VERSION "dbc-export 1 2026.26.6.5"

NS_ :

BS_:

BU_: ADSP APB APP APS APSB BB BMS CC CMP CMPD CP DAS DI DIF DIR DPB EPAS3P EPAS3S EPASTP EPASTS EPBL EPBR ESP EVSE FC GTW HCML HCMR HVP IBST ICR IDB LS OCS1P ODIN PARK PCS PCS2 PLG PM PMF PMR PNCD PTC RADC RCM RCM2 RCM3 RCU SCCM SCM SCS SDCR TAS TCU TCU2 TPMS TRCM UDS UI UIS UMC USM V2G VC VCBATT VCBATT0 VCBATT1 VCBATT2 VCCC VCFRONT VCFRONT1 VCFRONT2 VCLEFT VCRIGHT VCSEAT2L VCSEAT2R VCSEC VEH

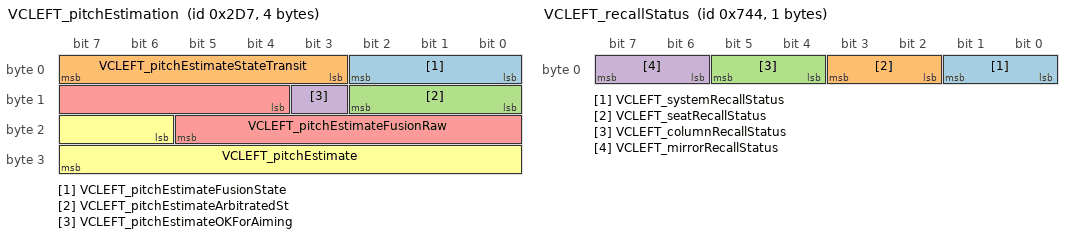
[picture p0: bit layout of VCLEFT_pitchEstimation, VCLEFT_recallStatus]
BO_ 727 VCLEFT_pitchEstimation: 4 VCLEFT
 SG_ VCLEFT_pitchEstimateFusionState : 0|3@1+ (1,0) [0|7] "" Vector__XXX
 SG_ VCLEFT_pitchEstimateStateTransit : 3|5@1+ (1,0) [0|31] "" Vector__XXX
 SG_ VCLEFT_pitchEstimateArbitratedSt : 8|3@1+ (1,0) [0|7] "" Vector__XXX
 SG_ VCLEFT_pitchEstimateOKForAiming : 11|1@1+ (1,0) [0|1] "" Vector__XXX
 SG_ VCLEFT_pitchEstimateFusionRaw : 12|10@1- (0.0002,0) [-0.1024|0.1022] "rad" Vector__XXX
 SG_ VCLEFT_pitchEstimate : 22|10@1- (0.0002,0) [-0.1022|0.1022] "rad" Vector__XXX

BO_ 1860 VCLEFT_recallStatus: 1 VCLEFT
 SG_ VCLEFT_systemRecallStatus : 0|2@1+ (1,0) [1|3] "" Vector__XXX
 SG_ VCLEFT_seatRecallStatus : 2|2@1+ (1,0) [1|3] "" Vector__XXX
 SG_ VCLEFT_columnRecallStatus : 4|2@1+ (1,0) [1|3] "" Vector__XXX
 SG_ VCLEFT_mirrorRecallStatus : 6|2@1+ (1,0) [1|3] "" Vector__XXX

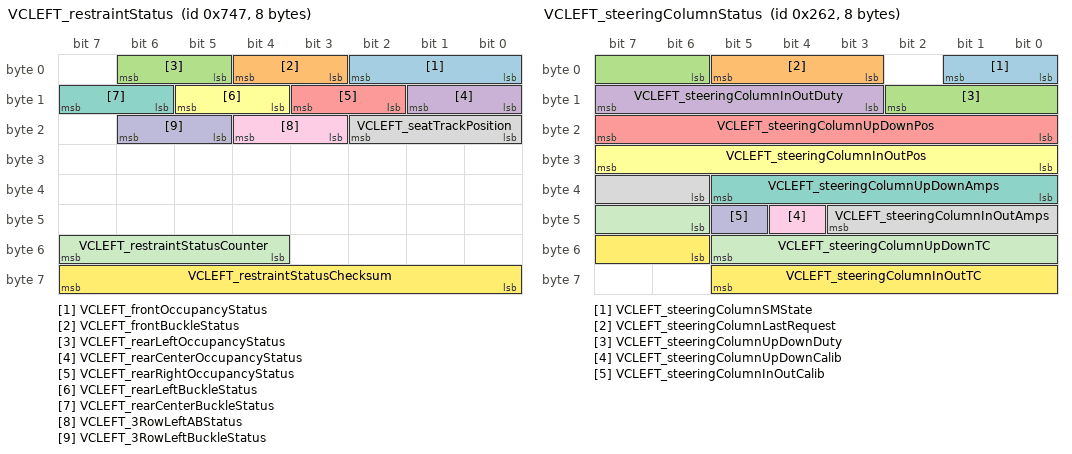
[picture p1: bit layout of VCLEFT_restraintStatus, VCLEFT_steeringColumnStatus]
BO_ 1863 VCLEFT_restraintStatus: 8 VCLEFT
 SG_ VCLEFT_frontOccupancyStatus : 0|3@1+ (1,0) [0|6] "" Vector__XXX
 SG_ VCLEFT_frontBuckleStatus : 3|2@1+ (1,0) [0|3] "" Vector__XXX
 SG_ VCLEFT_rearLeftOccupancyStatus : 5|2@1+ (1,0) [0|3] "" Vector__XXX
 SG_ VCLEFT_rearCenterOccupancyStatus : 8|2@1+ (1,0) [0|3] "" Vector__XXX
 SG_ VCLEFT_rearRightOccupancyStatus : 10|2@1+ (1,0) [0|3] "" Vector__XXX
 SG_ VCLEFT_rearLeftBuckleStatus : 12|2@1+ (1,0) [0|3] "" Vector__XXX
 SG_ VCLEFT_rearCenterBuckleStatus : 14|2@1+ (1,0) [0|3] "" Vector__XXX
 SG_ VCLEFT_seatTrackPosition : 16|3@1+ (1,0) [0|6] "" Vector__XXX
 SG_ VCLEFT_3RowLeftABStatus : 19|2@1+ (1,0) [0|3] "" Vector__XXX
 SG_ VCLEFT_3RowLeftBuckleStatus : 21|2@1+ (1,0) [0|3] "" Vector__XXX
 SG_ VCLEFT_restraintStatusCounter : 52|4@1+ (1,0) [0|15] "" Vector__XXX
 SG_ VCLEFT_restraintStatusChecksum : 56|8@1+ (1,0) [0|255] "" Vector__XXX

BO_ 1250 VCLEFT_seatStatus: 8 VCLEFT
 SG_ VCLEFT_seatStatusIndex M : 0|3@1+ (1,0) [0|7] "" Vector__XXX
 SG_ VC_AH_1RowLeftSeatMovementHealth m0 : 5|3@1+ (1,0) [0|7] "" Vector__XXX
 SG_ VCLEFT_frontSeatTrackPos m0 : 8|16@1- (1,0) [-32768|32767] "" Vector__XXX
 SG_ VCLEFT_frontSeatTrackCurrent m0 : 24|12@1- (0.01,0) [-20.48|20.47] "A" Vector__XXX
 SG_ VCLEFT_frontSeatTrackDuty m0 : 36|12@1- (0.1,0) [-204.8|204.7] "%" Vector__XXX
 SG_ VCLEFT_frontSeatTrackState m0 : 48|3@1+ (1,0) [0|7] "" Vector__XXX
 SG_ VCLEFT_frontSeatTrackCalibrated m0 : 51|1@1+ (1,0) [0|1] "" Vector__XXX
 SG_ VCLEFT_frontSeatTrackLog m0 : 52|1@1+ (1,0) [0|1] "" Vector__XXX
 SG_ VCLEFT_frontSeatTrackBridgeSt m0 : 53|2@1+ (1,0) [0|3] "" Vector__XXX
 SG_ VCLEFT_frontSeatTrackPercentage m0 : 55|7@1+ (1,0) [0|100] "%" Vector__XXX
 SG_ VCLEFT_frontSeatBackPos m1 : 8|16@1- (1,0) [-32768|32767] "" Vector__XXX
 SG_ VCLEFT_frontSeatBackCurrent m1 : 24|12@1- (0.01,0) [-20.48|20.47] "A" Vector__XXX
 SG_ VCLEFT_frontSeatBackDuty m1 : 36|12@1- (0.1,0) [-204.8|204.7] "%" Vector__XXX
 SG_ VCLEFT_frontSeatBackState m1 : 48|3@1+ (1,0) [0|7] "" Vector__XXX
 SG_ VCLEFT_frontSeatBackCalibrated m1 : 51|1@1+ (1,0) [0|1] "" Vector__XXX
 SG_ VCLEFT_frontSeatBackLog m1 : 52|1@1+ (1,0) [0|1] "" Vector__XXX
 SG_ VCLEFT_frontSeatBackBridgeSt m1 : 53|2@1+ (1,0) [0|3] "" Vector__XXX
 SG_ VCLEFT_frontSeatBackPercentage m1 : 55|7@1+ (1,0) [0|100] "%" Vector__XXX
 SG_ VCLEFT_frontSeatLiftPos m2 : 8|16@1- (1,0) [-32768|32767] "" Vector__XXX
 SG_ VCLEFT_frontSeatLiftCurrent m2 : 24|12@1- (0.01,0) [-20.48|20.47] "A" Vector__XXX
 SG_ VCLEFT_frontSeatLiftDuty m2 : 36|12@1- (0.1,0) [-204.8|204.7] "%" Vector__XXX
 SG_ VCLEFT_frontSeatLiftState m2 : 48|3@1+ (1,0) [0|7] "" Vector__XXX
 SG_ VCLEFT_frontSeatLiftCalibrated m2 : 51|1@1+ (1,0) [0|1] "" Vector__XXX
 SG_ VCLEFT_frontSeatLiftLog m2 : 52|1@1+ (1,0) [0|1] "" Vector__XXX
 SG_ VCLEFT_frontSeatLiftBridgeSt m2 : 53|2@1+ (1,0) [0|3] "" Vector__XXX
 SG_ VCLEFT_frontSeatLiftPercentage m2 : 55|7@1+ (1,0) [0|100] "%" Vector__XXX
 SG_ VCLEFT_frontSeatTiltPos m3 : 8|16@1- (1,0) [-32768|32767] "" Vector__XXX
 SG_ VCLEFT_frontSeatTiltCurrent m3 : 24|12@1- (0.01,0) [-20.48|20.47] "A" Vector__XXX
 SG_ VCLEFT_frontSeatTiltDuty m3 : 36|12@1- (0.1,0) [-204.8|204.7] "%" Vector__XXX
 SG_ VCLEFT_frontSeatTiltState m3 : 48|3@1+ (1,0) [0|7] "" Vector__XXX
 SG_ VCLEFT_frontSeatTiltCalibrated m3 : 51|1@1+ (1,0) [0|1] "" Vector__XXX
 SG_ VCLEFT_frontSeatTiltLog m3 : 52|1@1+ (1,0) [0|1] "" Vector__XXX
 SG_ VCLEFT_frontSeatTiltBridgeSt m3 : 53|2@1+ (1,0) [0|3] "" Vector__XXX
 SG_ VCLEFT_frontSeatTiltPercentage m3 : 55|7@1+ (1,0) [0|100] "%" Vector__XXX
 SG_ VCLEFT_lumbarAState m4 : 3|3@1+ (1,0) [0|7] "" Vector__XXX
 SG_ VCLEFT_lumbarBState m4 : 6|3@1+ (1,0) [0|7] "" Vector__XXX
 SG_ VCLEFT_lumbarAPressureHpa m4 : 9|12@1+ (1,0) [0|4095] "" Vector__XXX
 SG_ VCLEFT_lumbarAPressureHpaFilt m4 : 21|10@1+ (1,0) [0|1023] "" Vector__XXX
 SG_ VCLEFT_lumbarBPressureHpa m4 : 31|12@1+ (1,0) [0|4095] "" Vector__XXX
 SG_ VCLEFT_lumbarBPressureHpaFilt m4 : 43|10@1+ (1,0) [0|1023] "" Vector__XXX
 SG_ VCLEFT_lumbarActiveTooLongErr m4 : 53|1@1+ (1,0) [0|1] "" Vector__XXX
 SG_ VCLEFT_lumbarMaxPErr m4 : 54|1@1+ (1,0) [0|1] "" Vector__XXX
 SG_ VCLEFT_lumbarOvercurrentErr m4 : 55|1@1+ (1,0) [0|1] "" Vector__XXX
 SG_ VCLEFT_lumbarMaxOperatingPErr m4 : 56|1@1+ (1,0) [0|1] "" Vector__XXX
 SG_ VCLEFT_lumbarMinPErr m4 : 57|1@1+ (1,0) [0|1] "" Vector__XXX
 SG_ VCLEFT_lumbarGeneralErr m4 : 58|1@1+ (1,0) [0|1] "" Vector__XXX
 SG_ VCLEFT_lumbarDevMaxPumpPressA m4 : 59|1@1+ (1,0) [0|1] "" Vector__XXX
 SG_ VCLEFT_lumbarDevMaxPumpPressB m4 : 60|1@1+ (1,0) [0|1] "" Vector__XXX
 SG_ VCLEFT_frontSeatTrackPosReal m5 : 3|12@1- (1,0) [-2048|2047] "mm" Vector__XXX
 SG_ VCLEFT_frontSeatBackPosReal m5 : 16|12@1- (0.1,0) [-204.8|204.7] "deg" Vector__XXX
 SG_ VCLEFT_frontSeatLiftPosReal m5 : 28|12@1- (1,0) [-2048|2047] "mm" Vector__XXX
 SG_ VCLEFT_frontSeatTiltPosReal m5 : 40|12@1- (0.1,0) [-204.8|204.7] "deg" Vector__XXX
 SG_ VCLEFT_frontSeatThighSupportPosR m5 : 52|12@1- (1,0) [-2048|2047] "mm" Vector__XXX
 SG_ VCLEFT_frontSeatTrackPosOffset m6 : 3|12@1- (1,0) [-2048|2047] "mm" Vector__XXX
 SG_ VCLEFT_frontSeatBackPosOffset m6 : 16|12@1- (0.1,0) [-204.8|204.7] "deg" Vector__XXX
 SG_ VCLEFT_frontSeatLiftPosOffset m6 : 28|12@1- (1,0) [-2048|2047] "mm" Vector__XXX
 SG_ VCLEFT_frontSeatTiltPosOffset m6 : 40|12@1- (0.1,0) [-204.8|204.7] "deg" Vector__XXX
 SG_ VCLEFT_frontSeatThighSupportPosO m6 : 52|12@1- (1,0) [-2048|2047] "mm" Vector__XXX
 SG_ VCLEFT_lumbarAPressurePercentage m7 : 3|7@1+ (1,0) [0|100] "%" Vector__XXX
 SG_ VCLEFT_lumbarBPressurePercentage m7 : 10|7@1+ (1,0) [0|100] "%" Vector__XXX

BO_ 738 VCLEFT_seatStatus2: 8 VCLEFT
 SG_ VCLEFT_seatStatus2Index M : 0|4@1+ (1,0) [0|15] "" Vector__XXX
 SG_ VCLEFT_frontSeatHeatCurrent m0 : 4|12@1+ (0.01,0) [0|40.95] "A" Vector__XXX
 SG_ VCLEFT_frontSeatHeatDuty m0 : 16|8@1+ (1,0) [0|255] "%" Vector__XXX
 SG_ VCLEFT_frontSeatHeatTmp m0 : 24|12@1- (0.05,0) [-40|80] "degC" Vector__XXX
 SG_ VCLEFT_frontSeatHeatTmpTarget m0 : 36|8@1- (0.5,0) [0|60] "degC" Vector__XXX
 SG_ VCLEFT_frontSeatHeatInhibited m0 : 44|1@1+ (1,0) [0|1] "" Vector__XXX
 SG_ VCLEFT_frontSeatHeatPowered m0 : 45|1@1+ (1,0) [0|1] "" Vector__XXX
 SG_ VCLEFT_2RowSeatFoldLeftSwitch m0 : 46|2@1+ (1,0) [1|3] "" Vector__XXX
 SG_ VCLEFT_2RowSeatUnfoldLeftSwitch m0 : 48|2@1+ (1,0) [1|3] "" Vector__XXX
 SG_ VCLEFT_2RowSeatFoldRightSwitch m0 : 50|2@1+ (1,0) [1|3] "" Vector__XXX
 SG_ VCLEFT_2RowSeatUnfoldRightSwitch m0 : 52|2@1+ (1,0) [1|3] "" Vector__XXX
 SG_ VCLEFT_3RowSeatFoldLeftSwitch m0 : 54|2@1+ (1,0) [1|3] "" Vector__XXX
 SG_ VCLEFT_3RowSeatUnfoldLeftSwitch m0 : 56|2@1+ (1,0) [1|3] "" Vector__XXX
 SG_ VCLEFT_3RowSeatFoldRightSwitch m0 : 58|2@1+ (1,0) [1|3] "" Vector__XXX
 SG_ VCLEFT_3RowSeatUnfoldRightSwitch m0 : 60|2@1+ (1,0) [1|3] "" Vector__XXX
 SG_ VC_AH_1RowLeftSeatHeatVentHealth m0 : 62|2@1+ (1,0) [0|3] "" Vector__XXX
 SG_ VCLEFT_2RowSeatReclineState m11 : 4|4@1+ (1,0) [0|14] "" Vector__XXX
 SG_ VCLEFT_2RowSeatReclineDuty m11 : 8|8@1- (1,0) [-100|100] "%" Vector__XXX
 SG_ VCLEFT_2RowSeatReclineCurrent m11 : 16|12@1- (0.05,0) [-100|100] "A" Vector__XXX
 SG_ VCLEFT_2RowSeatReclineCalibrated m11 : 28|1@1+ (1,0) [0|1] "" Vector__XXX
 SG_ VCLEFT_2RowSeatReclinePositionRa m11 : 29|12@1- (1,0) [-2048|2047] "" Vector__XXX
 SG_ VCLEFT_2RowSeatReclineAngle m11 : 41|12@1- (0.1,0) [-204.8|204.7] "deg" Vector__XXX
 SG_ VCLEFT_2RowSeatReclineAbsPosSwit m11 : 53|2@1+ (1,0) [1|3] "" Vector__XXX
 SG_ VCLEFT_2RowSeatReclinePositionSt m12 : 4|3@1+ (1,0) [0|7] "" Vector__XXX
 SG_ VCLEFT_2RowSeatReclineAdjustment m12 : 7|1@1+ (1,0) [0|1] "" Vector__XXX
 SG_ VCLEFT_2RowSeatReclineFoldAllowe m12 : 8|1@1+ (1,0) [0|1] "" Vector__XXX
 SG_ VCLEFT_2RowSeatReclineUnfoldAllo m12 : 9|1@1+ (1,0) [0|1] "" Vector__XXX
 SG_ VCLEFT_2RowSeatReclineNextToggle m12 : 10|2@1+ (1,0) [0|3] "" Vector__XXX
 SG_ VCLEFT_2RowSeatReclineChoreoBloc m12 : 12|1@1+ (1,0) [0|1] "" Vector__XXX
 SG_ VCLEFT_2RowSeat1RClashAvoidanceB m12 : 13|3@1+ (1,0) [0|7] "" Vector__XXX
 SG_ VCLEFT_2RowSeat1RClashAvoidanceS m12 : 16|2@1+ (1,0) [0|3] "" Vector__XXX
 SG_ VCLEFT_2RowSeatReclineAbsPo_0001 m12 : 18|12@1- (0.1,0) [-204.8|204.7] "deg" Vector__XXX
 SG_ VC_AH_2RowLeftSeatMovementHealth m12 : 61|3@1+ (1,0) [0|7] "" Vector__XXX
 SG_ VCLEFT_3RowSeatReclineState m14 : 4|4@1+ (1,0) [0|14] "" Vector__XXX
 SG_ VCLEFT_3RowSeatReclineDuty m14 : 8|8@1- (1,0) [-100|100] "%" Vector__XXX
 SG_ VCLEFT_3RowSeatReclineCurrent m14 : 16|12@1- (0.05,0) [-100|100] "A" Vector__XXX
 SG_ VCLEFT_3RowSeatReclineCalibrated m14 : 28|1@1+ (1,0) [0|1] "" Vector__XXX
 SG_ VCLEFT_3RowSeatReclinePositionRa m14 : 29|12@1- (1,0) [-2048|2047] "" Vector__XXX
 SG_ VCLEFT_3RowSeatReclineAngle m14 : 41|12@1- (0.1,0) [-204.8|204.7] "deg" Vector__XXX
 SG_ VCLEFT_3RowSeatReclineNextToggle m14 : 53|2@1+ (1,0) [0|3] "" Vector__XXX
 SG_ VCLEFT_3RRightCushionHeatCurrent m15 : 4|12@1+ (0.01,0) [0|40.95] "A" Vector__XXX
 SG_ VCLEFT_3RRightCushionHeatDuty m15 : 16|8@1- (1,0) [-100|100] "%" Vector__XXX
 SG_ VCLEFT_3RRightCushionHeatTmp m15 : 24|12@1- (0.05,0) [-40|80] "degC" Vector__XXX
 SG_ VCLEFT_3RRightCushionHeatTmpTarg m15 : 36|8@1- (0.5,0) [0|60] "degC" Vector__XXX
 SG_ VCLEFT_3RRightCushionHeatInhibit m15 : 44|1@1+ (1,0) [0|1] "" Vector__XXX
 SG_ VCLEFT_3RowSeatReclinePositionSt m15 : 46|3@1+ (1,0) [0|7] "" Vector__XXX
 SG_ VCLEFT_3RowSeatReclineAdjustment m15 : 49|1@1+ (1,0) [0|1] "" Vector__XXX
 SG_ VCLEFT_3RowSeatReclineFoldAllowe m15 : 50|1@1+ (1,0) [0|1] "" Vector__XXX
 SG_ VCLEFT_3RowSeatReclineUnfoldAllo m15 : 51|1@1+ (1,0) [0|1] "" Vector__XXX
 SG_ VCLEFT_3RowSeatReclineChoreoBloc m15 : 52|1@1+ (1,0) [0|1] "" Vector__XXX
 SG_ VCLEFT_3RowSeatReclineAbsPosSwit m15 : 53|2@1+ (1,0) [1|3] "" Vector__XXX

BO_ 930 VCLEFT_status: 8 VCLEFT
 SG_ VCLEFT_statusIndex M : 0|2@1+ (1,0) [0|3] "" Vector__XXX
 SG_ VCLEFT_securityControllerEnable m0 : 5|1@1+ (1,0) [0|1] "" Vector__XXX
 SG_ VCLEFT_securityControllerVoltage m0 : 6|5@1+ (0.625,0) [0|19.375] "V" Vector__XXX
 SG_ VCLEFT_consoleDoorAssist m0 : 11|1@1+ (1,0) [0|1] "" Vector__XXX
 SG_ VCLEFT_OTAState m0 : 12|1@1+ (1,0) [0|1] "" Vector__XXX
 SG_ VCLEFT_5AVoltage m0 : 13|10@1+ (0.005443676,0) [0|5.568880548] "V" Vector__XXX
 SG_ VCLEFT_vbatProt m0 : 23|12@1+ (0.005443676,0) [0|22.29185322] "V" Vector__XXX
 SG_ VCLEFT_footwellLightCurrent m0 : 35|12@1- (0.1,0) [-204.8|204.7] "mA" Vector__XXX
 SG_ VCLEFT_swcInputVoltage m0 : 47|8@1+ (0.1,0) [0|25.4] "V" Vector__XXX
 SG_ VCLEFT_swcPCBATemperature m0 : 55|8@1- (1,68) [-59|195] "degC" Vector__XXX
 SG_ VCLEFT_obdEthernetActive m0 : 63|1@1+ (1,0) [0|1] "" Vector__XXX
 SG_ VCLEFT_rationalityAggregateCurre m1 : 12|8@1+ (0.5,0) [0|127.5] "A" Vector__XXX
 SG_ VCLEFT_LVBatteryTypeDBG m1 : 20|3@1+ (1,0) [0|7] "" Vector__XXX
 SG_ VCLEFT_DIeFuseFault m1 : 24|1@1+ (1,0) [0|1] "" Vector__XXX
 SG_ VCLEFT_eFuseMgmtVoltageMonitor m1 : 25|7@1+ (0.125,0) [0|15.875] "V" Vector__XXX
 SG_ VCLEFT_trailerAuxCurrent m1 : 32|12@1+ (0.025,0) [0|102.35] "A" Vector__XXX
 SG_ VCLEFT_swcHeatTmp m1 : 44|10@1+ (0.1,-35) [-35|65] "degC" Vector__XXX
 SG_ VCLEFT_swcHeatStatus m1 : 54|3@1+ (1,0) [1|7] "" Vector__XXX
 SG_ VCLEFT_swcHeatInhibited m1 : 57|1@1+ (1,0) [0|1] "" Vector__XXX
 SG_ VCLEFT_obdDeviceDetected m1 : 58|1@1+ (1,0) [0|1] "" Vector__XXX
 SG_ VCLEFT_pcbaTemperature m2 : 4|11@1+ (0.125,-40) [-40|150] "degC" Vector__XXX
 SG_ VCLEFT_swcHeatPwr m2 : 15|9@1+ (0.5,0) [0|254] "W" Vector__XXX
 SG_ VCLEFT_swcHeatDutyCycle m2 : 24|7@1+ (1,0) [0|100] "%" Vector__XXX
 SG_ VCLEFT_DIeFuseCurrent m2 : 31|6@1+ (0.1,0) [0|6.3] "A" Vector__XXX
 SG_ VCLEFT_SWCpresent m2 : 37|1@1+ (1,0) [0|1] "" Vector__XXX
 SG_ VCLEFT_trailerBrakeControllerCur m2 : 38|8@1+ (0.1,0) [0|25.5] "A" Vector__XXX
 SG_ VCLEFT_autonomyBehaviorStatus m2 : 46|2@1+ (1,0) [0|3] "" Vector__XXX
 SG_ VCLEFT_thirdRowLeftMapLightStatu m2 : 48|2@1+ (1,0) [0|2] "" Vector__XXX
 SG_ VCLEFT_thirdRowRightMapLightStat m2 : 50|2@1+ (1,0) [0|2] "" Vector__XXX

BO_ 610 VCLEFT_steeringColumnStatus: 8 VCLEFT
 SG_ VCLEFT_steeringColumnSMState : 0|2@1+ (1,0) [1|3] "" Vector__XXX
 SG_ VCLEFT_steeringColumnLastRequest : 3|3@1+ (1,0) [1|7] "" Vector__XXX
 SG_ VCLEFT_steeringColumnUpDownDuty : 6|5@1- (7,0) [-100|100] "%" Vector__XXX
 SG_ VCLEFT_steeringColumnInOutDuty : 11|5@1- (7,0) [-100|100] "%" Vector__XXX
 SG_ VCLEFT_steeringColumnUpDownPos : 16|8@1- (1,103) [-25|230] "mm" Vector__XXX
 SG_ VCLEFT_steeringColumnInOutPos : 24|8@1- (1,103) [-25|230] "mm" Vector__XXX
 SG_ VCLEFT_steeringColumnUpDownAmps : 32|6@1- (0.63,0) [-20|19.53] "A" Vector__XXX
 SG_ VCLEFT_steeringColumnInOutAmps : 38|6@1- (0.63,0) [-20|19.53] "A" Vector__XXX
 SG_ VCLEFT_steeringColumnUpDownCalib : 44|1@1+ (1,0) [0|1] "" Vector__XXX
 SG_ VCLEFT_steeringColumnInOutCalib : 45|1@1+ (1,0) [0|1] "" Vector__XXX
 SG_ VCLEFT_steeringColumnUpDownTC : 46|8@1+ (0.5,-10) [-10|117.5] "s" Vector__XXX
 SG_ VCLEFT_steeringColumnInOutTC : 54|8@1+ (0.5,-10) [-10|117.5] "s" Vector__XXX

BO_ 962 VCLEFT_switchStatus: 8 VCLEFT
 SG_ VCLEFT_switchStatusIndex M : 0|1@1+ (1,0) [0|1] "" Vector__XXX
 SG_ VCLEFT_hornSwitchPressed m0 : 2|1@1+ (1,0) [0|1] "" Vector__XXX
 SG_ VCLEFT_hazardButtonPressed m0 : 3|1@1+ (1,0) [0|1] "" Vector__XXX
 SG_ VCLEFT_brakeSwitchPressed m0 : 4|1@1+ (1,0) [0|1] "" Vector__XXX
 SG_ VCLEFT_rightMirrorTilt m0 : 5|3@1+ (1,0) [0|7] "" Vector__XXX
 SG_ VCLEFT_frontSeatTrackBack m0 : 8|2@1+ (1,0) [1|3] "" Vector__XXX
 SG_ VCLEFT_frontSeatTrackForward m0 : 10|2@1+ (1,0) [1|3] "" Vector__XXX
 SG_ VCLEFT_frontSeatTiltDown m0 : 12|2@1+ (1,0) [1|3] "" Vector__XXX
 SG_ VCLEFT_frontSeatTiltUp m0 : 14|2@1+ (1,0) [1|3] "" Vector__XXX
 SG_ VCLEFT_frontSeatLiftDown m0 : 16|2@1+ (1,0) [1|3] "" Vector__XXX
 SG_ VCLEFT_frontSeatLiftUp m0 : 18|2@1+ (1,0) [1|3] "" Vector__XXX
 SG_ VCLEFT_frontSeatBackrestBack m0 : 20|2@1+ (1,0) [1|3] "" Vector__XXX
 SG_ VCLEFT_frontSeatBackrestForward m0 : 22|2@1+ (1,0) [1|3] "" Vector__XXX
 SG_ VCLEFT_frontSeatLumbarDown m0 : 24|2@1+ (1,0) [1|3] "" Vector__XXX
 SG_ VCLEFT_frontSeatLumbarUp m0 : 26|2@1+ (1,0) [1|3] "" Vector__XXX
 SG_ VCLEFT_frontSeatLumbarIn m0 : 28|2@1+ (1,0) [1|3] "" Vector__XXX
 SG_ VCLEFT_frontSeatLumbarOut m0 : 30|2@1+ (1,0) [1|3] "" Vector__XXX
 SG_ VCLEFT_btnWindowSwPackUpLF m0 : 32|1@1+ (1,0) [0|1] "" Vector__XXX
 SG_ VCLEFT_btnWindowSwPackAutoUpLF m0 : 33|1@1+ (1,0) [0|1] "" Vector__XXX
 SG_ VCLEFT_btnWindowSwPackDownLF m0 : 34|1@1+ (1,0) [0|1] "" Vector__XXX
 SG_ VCLEFT_btnWindowSwPackAutoDownLF m0 : 35|1@1+ (1,0) [0|1] "" Vector__XXX
 SG_ VCLEFT_btnWindowSwPackUpLR m0 : 36|1@1+ (1,0) [0|1] "" Vector__XXX
 SG_ VCLEFT_btnWindowSwPackAutoUpLR m0 : 37|1@1+ (1,0) [0|1] "" Vector__XXX
 SG_ VCLEFT_btnWindowSwPackDownLR m0 : 38|1@1+ (1,0) [0|1] "" Vector__XXX
 SG_ VCLEFT_btnWindowSwPackAutoDownLR m0 : 39|1@1+ (1,0) [0|1] "" Vector__XXX
 SG_ VCLEFT_btnWindowSwPackUpRF m0 : 40|1@1+ (1,0) [0|1] "" Vector__XXX
 SG_ VCLEFT_btnWindowSwPackAutoUpRF m0 : 41|1@1+ (1,0) [0|1] "" Vector__XXX
 SG_ VCLEFT_btnWindowSwPackDownRF m0 : 42|1@1+ (1,0) [0|1] "" Vector__XXX
 SG_ VCLEFT_btnWindowSwPackAutoDownRF m0 : 43|1@1+ (1,0) [0|1] "" Vector__XXX
 SG_ VCLEFT_btnWindowSwPackUpRR m0 : 44|1@1+ (1,0) [0|1] "" Vector__XXX
 SG_ VCLEFT_btnWindowSwPackAutoUpRR m0 : 45|1@1+ (1,0) [0|1] "" Vector__XXX
 SG_ VCLEFT_btnWindowSwPackDownRR m0 : 46|1@1+ (1,0) [0|1] "" Vector__XXX
 SG_ VCLEFT_btnWindowSwPackAutoDownRR m0 : 47|1@1+ (1,0) [0|1] "" Vector__XXX
 SG_ VCLEFT_frontBuckleSwitch m0 : 48|2@1+ (1,0) [1|3] "" Vector__XXX
 SG_ VCLEFT_frontOccupancySwitch m0 : 50|2@1+ (1,0) [1|3] "" Vector__XXX
 SG_ VCLEFT_rearLeftBuckleSwitch m0 : 52|2@1+ (1,0) [1|3] "" Vector__XXX
 SG_ VCLEFT_rearCenterOccupancySwitch m0 : 54|2@1+ (1,0) [1|3] "" Vector__XXX
 SG_ VCLEFT_rearLeftOccupancySwitch m0 : 56|2@1+ (1,0) [1|3] "" Vector__XXX
 SG_ VCLEFT_rearRightOccupancySwitch m0 : 58|2@1+ (1,0) [1|3] "" Vector__XXX
 SG_ VCLEFT_brakePressed m0 : 60|1@1+ (1,0) [0|1] "" Vector__XXX
 SG_ VCLEFT_rearHVACButtonPressed m0 : 61|1@1+ (1,0) [0|1] "" Vector__XXX
 SG_ VCLEFT_rearCenterBuckleSwitch m0 : 62|2@1+ (1,0) [1|3] "" Vector__XXX
 SG_ VCLEFT_isAlcoholInterlockSet m1 : 2|1@1+ (1,0) [0|1] "" Vector__XXX
 SG_ VCLEFT_swcLeftTiltRight m1 : 3|2@1+ (1,0) [1|3] "" Vector__XXX
 SG_ VCLEFT_swcLeftPressed m1 : 5|2@1+ (1,0) [1|3] "" Vector__XXX
 SG_ VCLEFT_swcRightTiltLeft m1 : 8|2@1+ (1,0) [1|3] "" Vector__XXX
 SG_ VCLEFT_swcRightTiltRight m1 : 10|2@1+ (1,0) [1|3] "" Vector__XXX
 SG_ VCLEFT_swcRightPressed m1 : 12|2@1+ (1,0) [1|3] "" Vector__XXX
 SG_ VCLEFT_swcLeftTiltLeft m1 : 14|2@1+ (1,0) [1|3] "" Vector__XXX
 SG_ VCLEFT_swcLeftScrollTicks m1 : 16|6@1- (1,0) [-32|31] "" Vector__XXX
 SG_ VCLEFT_swcWiperButtonState m1 : 22|2@1+ (1,0) [0|3] "" Vector__XXX
 SG_ VCLEFT_swcRightScrollTicks m1 : 24|6@1- (1,0) [-32|31] "" Vector__XXX
 SG_ VCLEFT_swcTurnSignalLeftButtonSt m1 : 30|2@1+ (1,0) [0|3] "" Vector__XXX
 SG_ VCLEFT_btnWindowUpLR m1 : 32|1@1+ (1,0) [0|1] "" Vector__XXX
 SG_ VCLEFT_btnWindowAutoUpLR m1 : 33|1@1+ (1,0) [0|1] "" Vector__XXX
 SG_ VCLEFT_btnWindowDownLR m1 : 34|1@1+ (1,0) [0|1] "" Vector__XXX
 SG_ VCLEFT_btnWindowAutoDownLR m1 : 35|1@1+ (1,0) [0|1] "" Vector__XXX
 SG_ VCLEFT_2RowSeatReclineSwitch m1 : 36|1@1+ (1,0) [0|1] "" Vector__XXX
 SG_ VCLEFT_2RowSeatCenterSwitch m1 : 37|1@1+ (1,0) [0|1] "" Vector__XXX
 SG_ VCLEFT_2RowSeatLeftFoldFlatSwitc m1 : 38|1@1+ (1,0) [0|1] "" Vector__XXX
 SG_ VCLEFT_2RowSeatRightFoldFlatSwit m1 : 39|1@1+ (1,0) [0|1] "" Vector__XXX
 SG_ VCLEFT_2RowSeatBothFoldFlatSwitc m1 : 40|1@1+ (1,0) [0|1] "" Vector__XXX
 SG_ VCLEFT_swcLeftDoublePress m1 : 41|1@1+ (1,0) [0|1] "" Vector__XXX
 SG_ VCLEFT_swcRightDoublePress m1 : 42|1@1+ (1,0) [0|1] "" Vector__XXX
 SG_ VCLEFT_2RowSeatBackrestFoldSwitc m1 : 43|1@1+ (1,0) [0|1] "" Vector__XXX
 SG_ VCLEFT_swcTurnSignalRightButtonS m1 : 44|2@1+ (1,0) [0|3] "" Vector__XXX
 SG_ VCLEFT_swcHighBeamButtonState m1 : 46|2@1+ (1,0) [0|3] "" Vector__XXX
 SG_ VCLEFT_swcVoiceControlPress m1 : 48|2@1+ (1,0) [1|3] "" Vector__XXX
 SG_ VCLEFT_swcCameraButtonState m1 : 50|2@1+ (1,0) [0|3] "" Vector__XXX
 SG_ VCLEFT_swcRightPressedQF m1 : 52|1@1+ (1,0) [0|1] "" Vector__XXX
 SG_ VCLEFT_2RowSeatReclineSwitchpack m1 : 53|3@1+ (1,0) [0|7] "" Vector__XXX
 SG_ VCLEFT_3RowLeftBuckleSwitch m1 : 56|2@1+ (1,0) [1|3] "" Vector__XXX
 SG_ VCLEFT_frontSeatThighSupportExte m1 : 58|2@1+ (1,0) [1|3] "" Vector__XXX
 SG_ VCLEFT_frontSeatThighSupportRetr m1 : 60|2@1+ (1,0) [1|3] "" Vector__XXX
 SG_ VCLEFT_frontSeatResistiveOccupan m1 : 62|2@1+ (1,0) [1|3] "" Vector__XXX

BO_ 656 VCLEFT_thermalLogging10Hz: 8 VCLEFT
 SG_ VCLEFT_thermalLogging10HzIndex M : 0|3@1+ (1,0) [0|7] "" Vector__XXX
 SG_ VCLEFT_hvac2RLeftLateralVoltage m2 : 8|8@1+ (0.02,0) [0|5] "V" Vector__XXX
 SG_ VCLEFT_hvac2RLeftVerticalVoltage m2 : 16|8@1+ (0.02,0) [0|5] "V" Vector__XXX
 SG_ VCLEFT_hvac2RRightLateralVoltage m2 : 24|8@1+ (0.02,0) [0|5] "V" Vector__XXX
 SG_ VCLEFT_hvac2RRightVerticalVoltag m2 : 32|8@1+ (0.02,0) [0|5] "V" Vector__XXX
 SG_ VCLEFT_hvac2RLeftLateralCalibrat m2 : 40|1@1+ (1,0) [0|1] "" Vector__XXX
 SG_ VCLEFT_hvac2RLeftVerticalCalibra m2 : 41|1@1+ (1,0) [0|1] "" Vector__XXX
 SG_ VCLEFT_hvac2RRightLateralCalibra m2 : 42|1@1+ (1,0) [0|1] "" Vector__XXX
 SG_ VCLEFT_hvac2RRightVerticalCalibr m2 : 43|1@1+ (1,0) [0|1] "" Vector__XXX
 SG_ VCLEFT_hvac2RLeftLateralState m2 : 44|4@1+ (1,0) [0|15] "" Vector__XXX
 SG_ VCLEFT_hvac2RLeftVerticalState m2 : 48|4@1+ (1,0) [0|15] "" Vector__XXX
 SG_ VCLEFT_hvac2RRightLateralState m2 : 52|4@1+ (1,0) [0|15] "" Vector__XXX
 SG_ VCLEFT_hvac2RRightVerticalState m2 : 56|4@1+ (1,0) [0|15] "" Vector__XXX
 SG_ VCLEFT_hvacBlowerWindmillElecRpm m3 : 3|14@1+ (1,0) [0|16383] "RPM" Vector__XXX
 SG_ VCLEFT_hvac2RRightVerticalVeloci m3 : 17|8@1- (1,0) [-100|100] "deg/s" Vector__XXX
 SG_ VCLEFT_hvacBlowerWindmillBemf m3 : 25|14@1+ (4,0) [0|65532] "mV" Vector__XXX
 SG_ VCLEFT_hvac2RLeftVerticalVelocit m3 : 39|8@1- (1,0) [-100|100] "deg/s" Vector__XXX
 SG_ VCLEFT_hvac2RLeftLateralVelocity m3 : 47|8@1- (1,0) [-100|100] "deg/s" Vector__XXX
 SG_ VCLEFT_vcusbLinSchedule m3 : 55|2@1+ (1,0) [0|3] "" Vector__XXX
 SG_ VCLEFT_hvacBlowerArbState m3 : 57|3@1+ (1,0) [0|7] "" Vector__XXX
 SG_ VCLEFT_hvacBlowerArbResult m3 : 60|2@1+ (1,0) [0|3] "" Vector__XXX
 SG_ VCLEFT_hvac2RLeftLateralDuty m4 : 3|8@1- (1,0) [-100|100] "%" Vector__XXX
 SG_ VCLEFT_hvac2RLeftVerticalDuty m4 : 11|8@1- (1,0) [-100|100] "%" Vector__XXX
 SG_ VCLEFT_hvac2RRightLateralDuty m4 : 19|8@1- (1,0) [-100|100] "%" Vector__XXX
 SG_ VCLEFT_hvac2RRightVerticalDuty m4 : 27|8@1- (1,0) [-100|100] "%" Vector__XXX
 SG_ VCLEFT_hvacBlowerWindmilling m4 : 35|1@1+ (1,0) [0|1] "" Vector__XXX
 SG_ VCLEFT_hvac2RRightLateralVelocit m4 : 36|8@1- (1,0) [-100|100] "deg/s" Vector__XXX
 SG_ VCLEFT_hvacBlower1msOverrunFrequ m4 : 44|10@1+ (1,0) [0|1023] "" Vector__XXX
 SG_ VCLEFT_hvacBlower10msOverrunFreq m4 : 54|7@1+ (1,0) [0|127] "" Vector__XXX

BO_ 657 VCLEFT_thermalLogging1Hz: 7 VCLEFT
 SG_ VCLEFT_thermalLogging1HzIndex M : 0|4@1+ (1,0) [0|15] "" Vector__XXX
 SG_ VCLEFT_hvac2RLeftLateralZeroStop m0 : 8|8@1+ (0.02,0) [0|5] "V" Vector__XXX
 SG_ VCLEFT_hvac2RLeftVerticalZeroSto m0 : 16|8@1+ (0.02,0) [0|5] "V" Vector__XXX
 SG_ VCLEFT_hvac2RRightLateralZeroSto m0 : 24|8@1+ (0.02,0) [0|5] "V" Vector__XXX
 SG_ VCLEFT_hvac2RRightVerticalZeroSt m0 : 32|8@1+ (0.02,0) [0|5] "V" Vector__XXX
 SG_ VCLEFT_hvac2RLeftLateralEndStopV m1 : 8|8@1+ (0.02,0) [0|5] "V" Vector__XXX
 SG_ VCLEFT_hvac2RLeftVerticalEndStop m1 : 16|8@1+ (0.02,0) [0|5] "V" Vector__XXX
 SG_ VCLEFT_hvac2RRightLateralEndStop m1 : 24|8@1+ (0.02,0) [0|5] "V" Vector__XXX
 SG_ VCLEFT_hvac2RRightVerticalEndSto m1 : 32|8@1+ (0.02,0) [0|5] "V" Vector__XXX
 SG_ VCLEFT_hvacBlowerArbCurrent m1 : 40|8@1+ (0.1,0) [0|25.5] "A" Vector__XXX
 SG_ VCLEFT_hvacBlowerTorqueIndexFilt m1 : 48|7@1+ (1,0) [0|127] "%" Vector__XXX

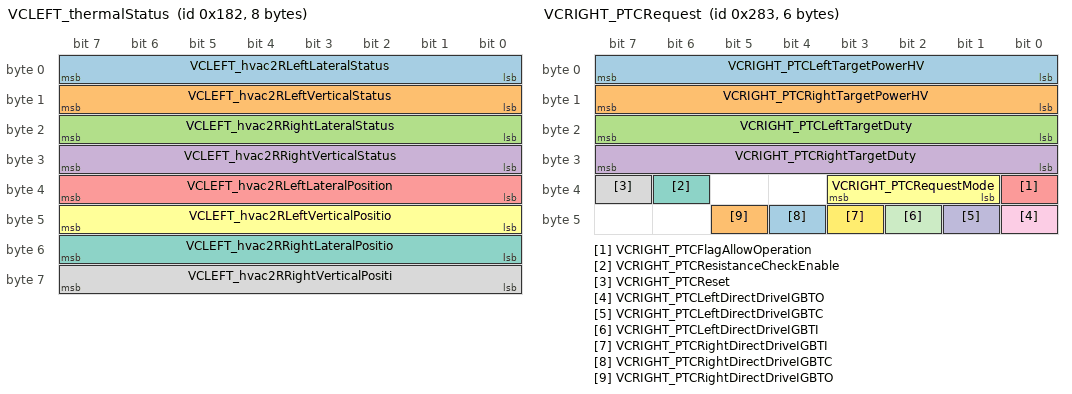
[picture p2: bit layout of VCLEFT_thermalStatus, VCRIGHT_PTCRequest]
BO_ 386 VCLEFT_thermalStatus: 8 VCLEFT
 SG_ VCLEFT_hvac2RLeftLateralStatus : 0|8@1+ (1,0) [0|255] "" Vector__XXX
 SG_ VCLEFT_hvac2RLeftVerticalStatus : 8|8@1+ (1,0) [0|255] "" Vector__XXX
 SG_ VCLEFT_hvac2RRightLateralStatus : 16|8@1+ (1,0) [0|255] "" Vector__XXX
 SG_ VCLEFT_hvac2RRightVerticalStatus : 24|8@1+ (1,0) [0|255] "" Vector__XXX
 SG_ VCLEFT_hvac2RLeftLateralPosition : 32|8@1+ (0.4,0) [0|100] "%" Vector__XXX
 SG_ VCLEFT_hvac2RLeftVerticalPositio : 40|8@1+ (0.4,0) [0|100] "%" Vector__XXX
 SG_ VCLEFT_hvac2RRightLateralPositio : 48|8@1+ (0.4,0) [0|100] "%" Vector__XXX
 SG_ VCLEFT_hvac2RRightVerticalPositi : 56|8@1+ (0.4,0) [0|100] "%" Vector__XXX

BO_ 1571 VCLEFT_udsResponse: 8 VCLEFT
 SG_ VCLEFT_udsResponseData_H : 7|32@0+ (1,0) [0|4294967295] "" Vector__XXX
 SG_ VCLEFT_udsResponseData_L : 39|32@0+ (1,0) [0|4294967295] "" Vector__XXX

BO_ 706 VCLEFT_windowStatus: 8 VCLEFT
 SG_ VCLEFT_windowStatusIndex M : 0|1@1+ (1,0) [0|1] "" Vector__XXX
 SG_ VCLEFT_windowStateLF m0 : 1|4@1+ (1,0) [0|15] "" Vector__XXX
 SG_ VCLEFT_windowTrimClearMoveReques m0 : 5|2@1+ (1,0) [0|3] "" Vector__XXX
 SG_ VCLEFT_windowDutyLF m0 : 8|6@1- (5,0) [-100|100] "%" Vector__XXX
 SG_ VCLEFT_windowTrimClearActiveRequ m0 : 14|2@1+ (1,0) [1|3] "" Vector__XXX
 SG_ VCLEFT_windowCurrentLF m0 : 16|6@1- (0.5,0) [-15|15] "A" Vector__XXX
 SG_ VCLEFT_windowPositionLF m0 : 22|9@1- (1.25,265) [-50|580] "mm" Vector__XXX
 SG_ VCLEFT_windowCalibratedLF m0 : 32|1@1+ (1,0) [0|1] "" Vector__XXX
 SG_ VCLEFT_windowStateLR m0 : 33|4@1+ (1,0) [0|15] "" Vector__XXX
 SG_ VCLEFT_windowDutyLR m0 : 40|6@1- (5,0) [-100|100] "%" Vector__XXX
 SG_ VCLEFT_windowCurrentLR m0 : 48|6@1- (0.5,0) [-15|15] "A" Vector__XXX
 SG_ VCLEFT_windowPositionLR m0 : 54|9@1- (1.25,265) [-50|580] "mm" Vector__XXX
 SG_ VCLEFT_windowCalibratedLR m0 : 63|1@1+ (1,0) [0|1] "" Vector__XXX
 SG_ VCLEFT_windowThermalTCLF m1 : 1|8@1+ (1,0) [0|255] "s" Vector__XXX
 SG_ VCLEFT_windowThermalModeLF m1 : 9|2@1+ (1,0) [1|3] "" Vector__XXX
 SG_ VCLEFT_windowStopReasonLF m1 : 11|3@1+ (1,0) [0|7] "" Vector__XXX
 SG_ VCLEFT_windowStopReqReasonLF m1 : 14|4@1+ (1,0) [0|15] "" Vector__XXX
 SG_ VCLEFT_windowThermalTCLR m1 : 18|8@1+ (1,0) [0|255] "s" Vector__XXX
 SG_ VCLEFT_windowThermalModeLR m1 : 26|2@1+ (1,0) [1|3] "" Vector__XXX
 SG_ VCLEFT_windowStopReasonLR m1 : 28|3@1+ (1,0) [0|7] "" Vector__XXX
 SG_ VCLEFT_windowStopReqReasonLR m1 : 31|4@1+ (1,0) [0|15] "" Vector__XXX
 SG_ VCLEFT_windowControlStateLF m1 : 35|2@1+ (1,0) [0|3] "" Vector__XXX
 SG_ VCLEFT_windowCtrlUnavailableLF m1 : 38|3@1+ (1,0) [0|7] "" Vector__XXX
 SG_ VCLEFT_windowControlStateLR m1 : 42|2@1+ (1,0) [0|3] "" Vector__XXX
 SG_ VCLEFT_windowCtrlUnavailableLR m1 : 45|3@1+ (1,0) [0|7] "" Vector__XXX
 SG_ VCLEFT_windowPositionStateLF m1 : 49|3@1+ (1,0) [0|7] "" Vector__XXX
 SG_ VCLEFT_windowPositionStateLR m1 : 52|3@1+ (1,0) [0|7] "" Vector__XXX
 SG_ VCLEFT_windowVehGearStateLF m1 : 56|2@1+ (1,0) [1|3] "" Vector__XXX
 SG_ VCLEFT_windowVehGearStateLR m1 : 58|2@1+ (1,0) [1|3] "" Vector__XXX
 SG_ VCLEFT_windowSpeedTableStatusLF m1 : 60|2@1+ (1,0) [1|3] "" Vector__XXX
 SG_ VCLEFT_windowSpeedTableStatusLR m1 : 62|2@1+ (1,0) [1|3] "" Vector__XXX

BO_ 1114 VCRIGHT_AP_hvacState10Hz: 8 VCRIGHT
 SG_ VCRIGHT_AP_hvacState10HzIndex M : 0|2@1+ (1,0) [0|3] "" Vector__XXX
 SG_ VCRIGHT_AP_autoDefogAvailable m0 : 2|1@1+ (1,0) [0|1] "" Vector__XXX
 SG_ VCRIGHT_AP_hvacFlashFoggingDetec m0 : 3|1@1+ (1,0) [0|1] "" Vector__XXX
 SG_ VCRIGHT_AP_hvacModelInitStatus m0 : 4|3@1+ (1,0) [0|7] "" Vector__XXX
 SG_ VCRIGHT_AP_cabinTempWindshield m0 : 7|8@1+ (0.5,-40) [-40|80] "degC" Vector__XXX
 SG_ VCRIGHT_AP_cabinTempSideGlassRig m0 : 15|8@1+ (0.5,-40) [-40|80] "degC" Vector__XXX
 SG_ VCRIGHT_AP_cabinTempSideGlassLef m0 : 23|8@1+ (0.5,-40) [-40|80] "degC" Vector__XXX
 SG_ VCRIGHT_AP_hvacRecircDoorPercent m0 : 31|6@1+ (1.6,0) [0|100] "%" Vector__XXX
 SG_ VCRIGHT_AP_hvacAirDistributionMo m0 : 37|3@1+ (1,0) [0|7] "" Vector__XXX
 SG_ VCRIGHT_AP_hvacEstimateWindshiel m0 : 40|8@1+ (1,0) [0|150] "%" Vector__XXX
 SG_ VCRIGHT_AP_hvacMassflowTarget m0 : 48|8@1+ (1,0) [0|200] "g/s" Vector__XXX
 SG_ VCRIGHT_AP_tempDuctDefrost m0 : 56|8@1+ (0.5,-22) [-22|105] "degC" Vector__XXX
 SG_ VCRIGHT_AP_cameraTurnOnTime m1 : 2|9@1+ (5,0) [0|2540] "min" Vector__XXX
 SG_ VCRIGHT_AP_cameraDefogType m1 : 11|3@1+ (1,0) [0|7] "" Vector__XXX
 SG_ VCRIGHT_ah_hvacFaultSurvivabilit m1 : 14|5@1+ (10,0) [0|300] "sec" Vector__XXX
 SG_ VCRIGHT_ah_defoggingTimeNeeded m1 : 19|5@1+ (1,0) [0|30] "min" Vector__XXX
 SG_ VCRIGHT_AP_cameraFanDutyRequest m1 : 24|7@1+ (1,0) [0|100] "%" Vector__XXX
 SG_ VCRIGHT_ah_defogSystemState m1 : 31|3@1+ (1,0) [0|6] "" Vector__XXX
 SG_ VCRIGHT_AP_turnForwardCameraHeat m1 : 34|4@1+ (1,0) [0|15] "" Vector__XXX
 SG_ VCRIGHT_AP_turnCameraFanOffReaso m1 : 38|3@1+ (1,0) [0|7] "" Vector__XXX
 SG_ VCRIGHT_AP_forwardCameraIntegrat m1 : 41|1@1+ (1,0) [0|1] "" Vector__XXX
 SG_ VCRIGHT_AP_solarFluxOnRightWindo m1 : 48|8@1+ (5,0) [0|1150] "W/m2" Vector__XXX
 SG_ VCRIGHT_AP_solarFluxOnLeftWindow m1 : 56|8@1+ (5,0) [0|1150] "W/m2" Vector__XXX

BO_ 1124 VCRIGHT_AP_hvacState1Hz: 8 VCRIGHT
 SG_ VCRIGHT_AP_hvacState1HzIndex M : 0|1@1+ (1,0) [0|1] "" Vector__XXX
 SG_ VCRIGHT_AP_tempCameraModele_0001 m0 : 2|8@1+ (0.5,-40) [-40|85] "degC" Vector__XXX
 SG_ VCRIGHT_AP_tempCameraModeledWind m0 : 10|8@1+ (0.5,-40) [-40|85] "degC" Vector__XXX
 SG_ VCRIGHT_AP_cameraModeledWin_0001 m0 : 18|7@1+ (1,0) [0|100] "%" Vector__XXX
 SG_ VCRIGHT_AP_cameraModeledWindshie m0 : 25|7@1+ (1,0) [0|100] "%" Vector__XXX
 SG_ VCRIGHT_AP_maxAchievableASideTem m0 : 32|7@1+ (1,-20) [-20|70] "degC" Vector__XXX
 SG_ VCRIGHT_AP_cameraModeledPocketWa m0 : 42|10@1+ (0.04,0) [0|40] "g/kg" Vector__XXX
 SG_ VCRIGHT_AP_humidityModelInitStat m0 : 52|5@1+ (1,0) [0|31] "" Vector__XXX
 SG_ VCRIGHT_AP_humidityModelStatus m0 : 57|5@1+ (1,0) [0|31] "" Vector__XXX

BO_ 549 VCRIGHT_LVPowerState: 4 VCRIGHT
 SG_ VCRIGHT_ptcLVState : 0|2@1+ (1,0) [0|3] "" Vector__XXX
 SG_ VCRIGHT_ocsLVState : 2|2@1+ (1,0) [0|3] "" Vector__XXX
 SG_ VCRIGHT_premAudioLVState : 4|2@1+ (1,0) [0|3] "" Vector__XXX
 SG_ VCRIGHT_rearOilPumpLVState : 6|2@1+ (1,0) [0|3] "" Vector__XXX
 SG_ VCRIGHT_tunerLVState : 8|2@1+ (1,0) [0|3] "" Vector__XXX
 SG_ VCRIGHT_hvcLVState : 10|2@1+ (1,0) [0|3] "" Vector__XXX
 SG_ VCRIGHT_rcmLVState : 12|2@1+ (1,0) [0|3] "" Vector__XXX
 SG_ VCRIGHT_lumbarLVState : 14|2@1+ (1,0) [0|3] "" Vector__XXX
 SG_ VCRIGHT_3RUSBPowered : 16|1@1+ (1,0) [0|1] "" Vector__XXX
 SG_ VCRIGHT_cntctrPwrState : 17|1@1+ (1,0) [0|1] "" Vector__XXX
 SG_ VCRIGHT_eFuseLockoutStatus : 18|2@1+ (1,0) [0|3] "" Vector__XXX
 SG_ VCRIGHT_swEnStatus : 20|1@1+ (1,0) [0|1] "" Vector__XXX
 SG_ VCRIGHT_vehiclePowerStateDBG : 21|2@1+ (1,0) [0|3] "" Vector__XXX
 SG_ VCRIGHT_parkLVState : 23|2@1+ (1,0) [0|3] "" Vector__XXX
 SG_ VCRIGHT_icrLVState : 25|2@1+ (1,0) [0|3] "" Vector__XXX
 SG_ VCRIGHT_interiorCameraLedLVState : 27|2@1+ (1,0) [0|3] "" Vector__XXX
 SG_ VCRIGHT_diLVState : 29|2@1+ (1,0) [0|3] "" Vector__XXX
 SG_ VCRIGHT_accDevicesDetected : 31|1@1+ (1,0) [0|1] "" Vector__XXX

BO_ 643 VCRIGHT_PTCRequest: 6 VCRIGHT
 SG_ VCRIGHT_PTCLeftTargetPowerHV : 0|8@1+ (30,0) [0|7650] "W" Vector__XXX
 SG_ VCRIGHT_PTCRightTargetPowerHV : 8|8@1+ (30,0) [0|7650] "W" Vector__XXX
 SG_ VCRIGHT_PTCLeftTargetDuty : 16|8@1+ (0.5,0) [0|100] "%" Vector__XXX
 SG_ VCRIGHT_PTCRightTargetDuty : 24|8@1+ (0.5,0) [0|100] "%" Vector__XXX
 SG_ VCRIGHT_PTCFlagAllowOperation : 32|1@1+ (1,0) [0|1] "" Vector__XXX
 SG_ VCRIGHT_PTCRequestMode : 33|3@1+ (1,0) [0|7] "" Vector__XXX
 SG_ VCRIGHT_PTCResistanceCheckEnable : 38|1@1+ (1,0) [0|1] "" Vector__XXX
 SG_ VCRIGHT_PTCReset : 39|1@1+ (1,0) [0|1] "" Vector__XXX
 SG_ VCRIGHT_PTCLeftDirectDriveIGBTO : 40|1@1+ (1,0) [0|1] "" Vector__XXX
 SG_ VCRIGHT_PTCLeftDirectDriveIGBTC : 41|1@1+ (1,0) [0|1] "" Vector__XXX
 SG_ VCRIGHT_PTCLeftDirectDriveIGBTI : 42|1@1+ (1,0) [0|1] "" Vector__XXX
 SG_ VCRIGHT_PTCRightDirectDriveIGBTI : 43|1@1+ (1,0) [0|1] "" Vector__XXX
 SG_ VCRIGHT_PTCRightDirectDriveIGBTC : 44|1@1+ (1,0) [0|1] "" Vector__XXX
 SG_ VCRIGHT_PTCRightDirectDriveIGBTO : 45|1@1+ (1,0) [0|1] "" Vector__XXX

BO_ 2011 VCRIGHT_alertLog: 8 VCRIGHT
 SG_ VCRIGHT_alertID M : 0|10@1+ (1,0) [0|1023] "" Vector__XXX
 SG_ VCRIGHT_alertState : 15|1@1+ (1,0) [0|1] "" Vector__XXX
 SG_ VCRIGHT_a001_InternalWatchdog m1 : 16|1@1+ (1,0) [0|1] "" Vector__XXX
 SG_ VCRIGHT_a010_UnderVoltageDetecte m10 : 16|1@1+ (1,0) [0|1] "" Vector__XXX
 SG_ VCRIGHT_a010_UnderVoltageTimeout m10 : 17|1@1+ (1,0) [0|1] "" Vector__XXX
 SG_ VCRIGHT_a015_NVMMMemOverflow m15 : 16|1@1+ (1,0) [0|1] "" Vector__XXX
 SG_ VCRIGHT_a015_NVMMFilesystemError m15 : 17|1@1+ (1,0) [0|1] "" Vector__XXX
 SG_ VCRIGHT_a015_NVMMRecordIDError m15 : 18|1@1+ (1,0) [0|1] "" Vector__XXX
 SG_ VCRIGHT_a057_VEH_cpControl m57 : 16|1@1+ (1,0) [0|1] "" Vector__XXX
 SG_ VCRIGHT_a059_voltageDrop m59 : 16|12@1+ (0.005443676,0) [0|22.29185322] "V" Vector__XXX
 SG_ VCRIGHT_a059_resistanceEstimate m59 : 28|12@1+ (0.00244,0) [0|9.9918] "Ohms" Vector__XXX
 SG_ VCRIGHT_a059_current m59 : 40|12@1+ (0.05,0) [0|204.75] "A" Vector__XXX
 SG_ VCRIGHT_a063_switchChannel m63 : 16|8@1+ (1,0) [0|255] "" Vector__XXX
 SG_ VCRIGHT_a063_switchType m63 : 24|8@1+ (1,0) [0|255] "" Vector__XXX
 SG_ VCRIGHT_a063_ADCVoltage m63 : 32|8@1+ (0.025,0) [0|6.375] "V" Vector__XXX
 SG_ VCRIGHT_a063_disconnected m63 : 40|1@1+ (1,0) [0|1] "" Vector__XXX
 SG_ VCRIGHT_a063_indeterminate m63 : 41|1@1+ (1,0) [0|1] "" Vector__XXX
 SG_ VCRIGHT_a063_stuckActive m63 : 42|1@1+ (1,0) [0|1] "" Vector__XXX
 SG_ VCRIGHT_a063_faulted m63 : 43|1@1+ (1,0) [0|1] "" Vector__XXX
 SG_ VCRIGHT_a082_RIPC_epbPrivateStat m82 : 16|1@1+ (1,0) [0|1] "" Vector__XXX
 SG_ VCRIGHT_a082_RIPC_remoteHSD m82 : 17|1@1+ (1,0) [0|1] "" Vector__XXX
 SG_ VCRIGHT_a082_RIPC_railStatus m82 : 18|1@1+ (1,0) [0|1] "" Vector__XXX
 SG_ VCRIGHT_a082_RIPC_remoteMux m82 : 19|1@1+ (1,0) [0|1] "" Vector__XXX
 SG_ VCRIGHT_a083_LIPC_epbPrivateStat m83 : 16|1@1+ (1,0) [0|1] "" Vector__XXX
 SG_ VCRIGHT_a083_LIPC_remoteHSD m83 : 17|1@1+ (1,0) [0|1] "" Vector__XXX
 SG_ VCRIGHT_a083_LIPC_railStatus m83 : 18|1@1+ (1,0) [0|1] "" Vector__XXX
 SG_ VCRIGHT_a083_LIPC_HSDFaults m83 : 19|1@1+ (1,0) [0|1] "" Vector__XXX
 SG_ VCRIGHT_a084_CH_StatusC m84 : 16|1@1+ (1,0) [0|1] "" Vector__XXX
 SG_ VCRIGHT_a085_PARTY_buttonStatus m85 : 16|1@1+ (1,0) [0|1] "" Vector__XXX
 SG_ VCRIGHT_a086_VEH_LVBMS_statusHig m86 : 16|1@1+ (1,0) [0|1] "" Vector__XXX
 SG_ VCRIGHT_a086_VEH_LVBMS_statusLow m86 : 17|1@1+ (1,0) [0|1] "" Vector__XXX
 SG_ VCRIGHT_a086_VEH_status m86 : 18|1@1+ (1,0) [0|1] "" Vector__XXX
 SG_ VCRIGHT_a086_VEH_12VBatteryStatu m86 : 19|1@1+ (1,0) [0|1] "" Vector__XXX
 SG_ VCRIGHT_a086_VEH_LVPowerState m86 : 20|1@1+ (1,0) [0|1] "" Vector__XXX
 SG_ VCRIGHT_a086_VEH_lightStatus m86 : 21|1@1+ (1,0) [0|1] "" Vector__XXX
 SG_ VCRIGHT_a086_VEH_systemStatus m86 : 22|1@1+ (1,0) [0|1] "" Vector__XXX
 SG_ VCRIGHT_a086_VEH_thermalStatus m86 : 23|1@1+ (1,0) [0|1] "" Vector__XXX
 SG_ VCRIGHT_a086_VEH_vehNm m86 : 24|1@1+ (1,0) [0|1] "" Vector__XXX
 SG_ VCRIGHT_a086_BDY_LVSelfTests m86 : 60|1@1+ (1,0) [0|1] "" Vector__XXX
 SG_ VCRIGHT_a086_VEH_LVSelfTests m86 : 61|1@1+ (1,0) [0|1] "" Vector__XXX
 SG_ VCRIGHT_a086_VEH_LVHealth m86 : 62|1@1+ (1,0) [0|1] "" Vector__XXX
 SG_ VCRIGHT_a086_BDY_12VBatteryStatu m86 : 63|1@1+ (1,0) [0|1] "" Vector__XXX
 SG_ VCRIGHT_a087_VEH_temperature m87 : 16|1@1+ (1,0) [0|1] "" Vector__XXX
 SG_ VCRIGHT_a087_VEH_thermalControl m87 : 17|1@1+ (1,0) [0|1] "" Vector__XXX
 SG_ VCRIGHT_a087_VEH_torque m87 : 18|1@1+ (1,0) [0|1] "" Vector__XXX
 SG_ VCRIGHT_a087_VEH_status m87 : 19|1@1+ (1,0) [0|1] "" Vector__XXX
 SG_ VCRIGHT_a087_PARTY_torque m87 : 20|1@1+ (1,0) [0|1] "" Vector__XXX
 SG_ VCRIGHT_a087_PARTY_status m87 : 21|1@1+ (1,0) [0|1] "" Vector__XXX
 SG_ VCRIGHT_a087_PARTY_temperature m87 : 22|1@1+ (1,0) [0|1] "" Vector__XXX
 SG_ VCRIGHT_a087_PARTY_thermalContro m87 : 23|1@1+ (1,0) [0|1] "" Vector__XXX
 SG_ VCRIGHT_a087_VEH_motorStatus m87 : 24|1@1+ (1,0) [0|1] "" Vector__XXX
 SG_ VCRIGHT_a088_VEH_temperature m88 : 16|1@1+ (1,0) [0|1] "" Vector__XXX
 SG_ VCRIGHT_a088_VEH_thermalControl m88 : 17|1@1+ (1,0) [0|1] "" Vector__XXX
 SG_ VCRIGHT_a088_VEH_torque m88 : 18|1@1+ (1,0) [0|1] "" Vector__XXX
 SG_ VCRIGHT_a088_VEH_status m88 : 19|1@1+ (1,0) [0|1] "" Vector__XXX
 SG_ VCRIGHT_a088_PARTY_torque m88 : 20|1@1+ (1,0) [0|1] "" Vector__XXX
 SG_ VCRIGHT_a088_PARTY_status m88 : 21|1@1+ (1,0) [0|1] "" Vector__XXX
 SG_ VCRIGHT_a088_PARTY_temperature m88 : 22|1@1+ (1,0) [0|1] "" Vector__XXX
 SG_ VCRIGHT_a088_PARTY_thermalContro m88 : 23|1@1+ (1,0) [0|1] "" Vector__XXX
 SG_ VCRIGHT_a088_VEH_motorStatus m88 : 24|1@1+ (1,0) [0|1] "" Vector__XXX
 SG_ VCRIGHT_a089_PARTY_party1 m89 : 16|1@1+ (1,0) [0|1] "" Vector__XXX
 SG_ VCRIGHT_a089_PARTY_status m89 : 17|1@1+ (1,0) [0|1] "" Vector__XXX
 SG_ VCRIGHT_a089_VEH_status m89 : 18|1@1+ (1,0) [0|1] "" Vector__XXX
 SG_ VCRIGHT_a089_BDY_party1 m89 : 19|1@1+ (1,0) [0|1] "" Vector__XXX
 SG_ VCRIGHT_a089_BDY_status m89 : 20|1@1+ (1,0) [0|1] "" Vector__XXX
 SG_ VCRIGHT_a089_CH_status m89 : 21|1@1+ (1,0) [0|1] "" Vector__XXX
 SG_ VCRIGHT_a089_CH_party1 m89 : 22|1@1+ (1,0) [0|1] "" Vector__XXX
 SG_ VCRIGHT_a089_CH_party3 m89 : 23|1@1+ (1,0) [0|1] "" Vector__XXX
 SG_ VCRIGHT_a089_VEH_party1 m89 : 24|1@1+ (1,0) [0|1] "" Vector__XXX
 SG_ VCRIGHT_a089_VEH_party3 m89 : 25|1@1+ (1,0) [0|1] "" Vector__XXX
 SG_ VCRIGHT_a091_VEH_faultsAndExtras m91 : 16|1@1+ (1,0) [0|1] "" Vector__XXX
 SG_ VCRIGHT_a091_VEH_info m91 : 17|1@1+ (1,0) [0|1] "" Vector__XXX
 SG_ VCRIGHT_a091_VEH_state m91 : 18|1@1+ (1,0) [0|1] "" Vector__XXX
 SG_ VCRIGHT_a092_VEH_restraintStatus m92 : 16|1@1+ (1,0) [0|1] "" Vector__XXX
 SG_ VCRIGHT_a092_VEH_switchStatus m92 : 17|1@1+ (1,0) [0|1] "" Vector__XXX
 SG_ VCRIGHT_a092_VEH_seatStatus2 m92 : 18|1@1+ (1,0) [0|1] "" Vector__XXX
 SG_ VCRIGHT_a092_VEH_vehNm m92 : 19|1@1+ (1,0) [0|1] "" Vector__XXX
 SG_ VCRIGHT_a093_VEH_restraintStatus m93 : 16|1@1+ (1,0) [0|1] "" Vector__XXX
 SG_ VCRIGHT_a093_VEH_switchStatus m93 : 17|1@1+ (1,0) [0|1] "" Vector__XXX
 SG_ VCRIGHT_a093_VEH_seatStatus2 m93 : 18|1@1+ (1,0) [0|1] "" Vector__XXX
 SG_ VCRIGHT_a093_VEH_vehNm m93 : 19|1@1+ (1,0) [0|1] "" Vector__XXX
 SG_ VCRIGHT_a094_VEH_sysStatus m94 : 16|1@1+ (1,0) [0|1] "" Vector__XXX
 SG_ VCRIGHT_a094_PARTY_sysStatus m94 : 17|1@1+ (1,0) [0|1] "" Vector__XXX
 SG_ VCRIGHT_a094_CH_sysStatus m94 : 18|1@1+ (1,0) [0|1] "" Vector__XXX
 SG_ VCRIGHT_a095_PT_ptNm m95 : 16|1@1+ (1,0) [0|1] "" Vector__XXX
 SG_ VCRIGHT_a095_PT_status m95 : 17|1@1+ (1,0) [0|1] "" Vector__XXX
 SG_ VCRIGHT_a096_VEH_status m96 : 16|1@1+ (1,0) [0|1] "" Vector__XXX
 SG_ VCRIGHT_a096_CH_status m96 : 17|1@1+ (1,0) [0|1] "" Vector__XXX
 SG_ VCRIGHT_a097_VEH_HVStatus m97 : 16|1@1+ (1,0) [0|1] "" Vector__XXX
 SG_ VCRIGHT_a097_VEH_state m97 : 17|1@1+ (1,0) [0|1] "" Vector__XXX
 SG_ VCRIGHT_a098_CH_torque m98 : 16|1@1+ (1,0) [0|1] "" Vector__XXX
 SG_ VCRIGHT_a098_VEH_hvStatus m98 : 17|1@1+ (1,0) [0|1] "" Vector__XXX
 SG_ VCRIGHT_a098_VEH_status m98 : 18|1@1+ (1,0) [0|1] "" Vector__XXX
 SG_ VCRIGHT_a098_VEH_thermalControl m98 : 19|1@1+ (1,0) [0|1] "" Vector__XXX
 SG_ VCRIGHT_a098_VEH_temperature m98 : 20|1@1+ (1,0) [0|1] "" Vector__XXX
 SG_ VCRIGHT_a098_VEH_torque m98 : 21|1@1+ (1,0) [0|1] "" Vector__XXX
 SG_ VCRIGHT_a098_PARTY_status m98 : 22|1@1+ (1,0) [0|1] "" Vector__XXX
 SG_ VCRIGHT_a098_PARTY_temperature m98 : 23|1@1+ (1,0) [0|1] "" Vector__XXX
 SG_ VCRIGHT_a098_PARTY_thermalContro m98 : 24|1@1+ (1,0) [0|1] "" Vector__XXX
 SG_ VCRIGHT_a098_PARTY_torque m98 : 25|1@1+ (1,0) [0|1] "" Vector__XXX
 SG_ VCRIGHT_a098_PT_thermalControl m98 : 26|1@1+ (1,0) [0|1] "" Vector__XXX
 SG_ VCRIGHT_a098_PT_temperature m98 : 27|1@1+ (1,0) [0|1] "" Vector__XXX
 SG_ VCRIGHT_a098_PARTY_motorStatus m98 : 28|1@1+ (1,0) [0|1] "" Vector__XXX
 SG_ VCRIGHT_a098_VEH_motorStatus m98 : 29|1@1+ (1,0) [0|1] "" Vector__XXX
 SG_ VCRIGHT_a099_VEH_oocStatus m99 : 16|1@1+ (1,0) [0|1] "" Vector__XXX
 SG_ VCRIGHT_a100_VEH m100 : 16|1@1+ (1,0) [0|1] "" Vector__XXX
 SG_ VCRIGHT_a100_PARTY m100 : 17|1@1+ (1,0) [0|1] "" Vector__XXX
 SG_ VCRIGHT_a100_PT m100 : 18|1@1+ (1,0) [0|1] "" Vector__XXX
 SG_ VCRIGHT_a100_CH m100 : 19|1@1+ (1,0) [0|1] "" Vector__XXX
 SG_ VCRIGHT_a100_OBD m100 : 20|1@1+ (1,0) [0|1] "" Vector__XXX
 SG_ VCRIGHT_a101_VEH_state m101 : 16|1@1+ (1,0) [0|1] "" Vector__XXX
 SG_ VCRIGHT_a101_PARTY_locState m101 : 17|1@1+ (1,0) [0|1] "" Vector__XXX
 SG_ VCRIGHT_a101_LIPC_externalWatchd m101 : 18|1@1+ (1,0) [0|1] "" Vector__XXX
 SG_ VCRIGHT_a101_VEH_locState m101 : 19|1@1+ (1,0) [0|1] "" Vector__XXX
 SG_ VCRIGHT_a101_BDY_locState m101 : 20|1@1+ (1,0) [0|1] "" Vector__XXX
 SG_ VCRIGHT_a102_VEH_faultsAndExtras m102 : 16|1@1+ (1,0) [0|1] "" Vector__XXX
 SG_ VCRIGHT_a102_VEH_feedbackStatus m102 : 17|1@1+ (1,0) [0|1] "" Vector__XXX
 SG_ VCRIGHT_a102_VEH_sensorStatus m102 : 18|1@1+ (1,0) [0|1] "" Vector__XXX
 SG_ VCRIGHT_a102_VEH_rods m102 : 19|1@1+ (1,0) [0|1] "" Vector__XXX
 SG_ VCRIGHT_a103_VEH_hvsNm m103 : 16|1@1+ (1,0) [0|1] "" Vector__XXX
 SG_ VCRIGHT_a103_VEH_vehNm m103 : 17|1@1+ (1,0) [0|1] "" Vector__XXX
 SG_ VCRIGHT_a103_VEH_status m103 : 18|1@1+ (1,0) [0|1] "" Vector__XXX
 SG_ VCRIGHT_a103_PT_ptNm m103 : 19|1@1+ (1,0) [0|1] "" Vector__XXX
 SG_ VCRIGHT_a103_PT_status m103 : 20|1@1+ (1,0) [0|1] "" Vector__XXX
 SG_ VCRIGHT_a103_VEH_evseStatus m103 : 21|1@1+ (1,0) [0|1] "" Vector__XXX
 SG_ VCRIGHT_a105_VEH_states m105 : 16|1@1+ (1,0) [0|1] "" Vector__XXX
 SG_ VCRIGHT_a105_VEH_chNm m105 : 17|1@1+ (1,0) [0|1] "" Vector__XXX
 SG_ VCRIGHT_a105_VEH_dampingStates m105 : 18|1@1+ (1,0) [0|1] "" Vector__XXX
 SG_ VCRIGHT_a106_VEH_dcdcStatus m106 : 16|1@1+ (1,0) [0|1] "" Vector__XXX
 SG_ VCRIGHT_a106_VEH_thermalControl m106 : 17|1@1+ (1,0) [0|1] "" Vector__XXX
 SG_ VCRIGHT_a106_VEH_dcdcRailStatus m106 : 18|1@1+ (1,0) [0|1] "" Vector__XXX
 SG_ VCRIGHT_a106_CH_dcdcRailStatus m106 : 19|1@1+ (1,0) [0|1] "" Vector__XXX
 SG_ VCRIGHT_a106_CH_alertMatrix m106 : 20|1@1+ (1,0) [0|1] "" Vector__XXX
 SG_ VCRIGHT_a107_VEH_hvsNm m107 : 16|1@1+ (1,0) [0|1] "" Vector__XXX
 SG_ VCRIGHT_a107_VEH_vehNm m107 : 17|1@1+ (1,0) [0|1] "" Vector__XXX
 SG_ VCRIGHT_a107_VEH_status m107 : 18|1@1+ (1,0) [0|1] "" Vector__XXX
 SG_ VCRIGHT_a107_VEH_thermalStatus m107 : 19|1@1+ (1,0) [0|1] "" Vector__XXX
 SG_ VCRIGHT_a107_VEH_bmbMinMax m107 : 20|1@1+ (1,0) [0|1] "" Vector__XXX
 SG_ VCRIGHT_a107_VEH_powerAvailable m107 : 21|1@1+ (1,0) [0|1] "" Vector__XXX
 SG_ VCRIGHT_a107_PT_ptNm m107 : 22|1@1+ (1,0) [0|1] "" Vector__XXX
 SG_ VCRIGHT_a107_PT_status m107 : 23|1@1+ (1,0) [0|1] "" Vector__XXX
 SG_ VCRIGHT_a107_PT_thermalStatus m107 : 24|1@1+ (1,0) [0|1] "" Vector__XXX
 SG_ VCRIGHT_a107_PT_socStatus m107 : 25|1@1+ (1,0) [0|1] "" Vector__XXX
 SG_ VCRIGHT_a107_VEH_socStatus m107 : 26|1@1+ (1,0) [0|1] "" Vector__XXX
 SG_ VCRIGHT_a107_VEH_packConfig m107 : 27|1@1+ (1,0) [0|1] "" Vector__XXX
 SG_ VCRIGHT_a107_VEH_energyStatus m107 : 28|1@1+ (1,0) [0|1] "" Vector__XXX
 SG_ VCRIGHT_a107_VEH_chargeInfo m107 : 29|1@1+ (1,0) [0|1] "" Vector__XXX
 SG_ VCRIGHT_a108_VEH_hvStatus m108 : 16|1@1+ (1,0) [0|1] "" Vector__XXX
 SG_ VCRIGHT_a108_VEH_temperature m108 : 17|1@1+ (1,0) [0|1] "" Vector__XXX
 SG_ VCRIGHT_a108_VEH_thermalControl m108 : 18|1@1+ (1,0) [0|1] "" Vector__XXX
 SG_ VCRIGHT_a108_VEH_torque m108 : 19|1@1+ (1,0) [0|1] "" Vector__XXX
 SG_ VCRIGHT_a108_VEH_status m108 : 20|1@1+ (1,0) [0|1] "" Vector__XXX
 SG_ VCRIGHT_a108_PARTY_torque m108 : 21|1@1+ (1,0) [0|1] "" Vector__XXX
 SG_ VCRIGHT_a108_PARTY_status m108 : 22|1@1+ (1,0) [0|1] "" Vector__XXX
 SG_ VCRIGHT_a108_PARTY_temperature m108 : 23|1@1+ (1,0) [0|1] "" Vector__XXX
 SG_ VCRIGHT_a108_PARTY_thermalContro m108 : 24|1@1+ (1,0) [0|1] "" Vector__XXX
 SG_ VCRIGHT_a108_PT_temperature m108 : 25|1@1+ (1,0) [0|1] "" Vector__XXX
 SG_ VCRIGHT_a108_PT_thermalControl m108 : 26|1@1+ (1,0) [0|1] "" Vector__XXX
 SG_ VCRIGHT_a108_PARTY_motorStatus m108 : 27|1@1+ (1,0) [0|1] "" Vector__XXX
 SG_ VCRIGHT_a108_VEH_motorStatus m108 : 28|1@1+ (1,0) [0|1] "" Vector__XXX
 SG_ VCRIGHT_a108_CH_torque m108 : 29|1@1+ (1,0) [0|1] "" Vector__XXX
 SG_ VCRIGHT_a110_VEH_carState m110 : 16|1@1+ (1,0) [0|1] "" Vector__XXX
 SG_ VCRIGHT_a110_VEH_carConfig m110 : 17|1@1+ (1,0) [0|1] "" Vector__XXX
 SG_ VCRIGHT_a110_VEH_time m110 : 18|1@1+ (1,0) [0|1] "" Vector__XXX
 SG_ VCRIGHT_a110_VEH_updateStatus m110 : 19|1@1+ (1,0) [0|1] "" Vector__XXX
 SG_ VCRIGHT_a110_VEH_vehNm m110 : 20|1@1+ (1,0) [0|1] "" Vector__XXX
 SG_ VCRIGHT_a110_VEH_mismatchFault m110 : 21|1@1+ (1,0) [0|1] "" Vector__XXX
 SG_ VCRIGHT_a110_VEH_vin m110 : 22|1@1+ (1,0) [0|1] "" Vector__XXX
 SG_ VCRIGHT_a110_VEH_bmpDebug m110 : 23|1@1+ (1,0) [0|1] "" Vector__XXX
 SG_ VCRIGHT_a110_VEH_gearControl m110 : 24|1@1+ (1,0) [0|1] "" Vector__XXX
 SG_ VCRIGHT_a110_VEH_canLogAvailabil m110 : 25|1@1+ (1,0) [0|1] "" Vector__XXX
 SG_ VCRIGHT_a110_CH_airbagCutoffStat m110 : 26|1@1+ (1,0) [0|1] "" Vector__XXX
 SG_ VCRIGHT_a110_CH_carConfig m110 : 27|1@1+ (1,0) [0|1] "" Vector__XXX
 SG_ VCRIGHT_a110_CH_carState m110 : 28|1@1+ (1,0) [0|1] "" Vector__XXX
 SG_ VCRIGHT_a110_CH_vin m110 : 29|1@1+ (1,0) [0|1] "" Vector__XXX
 SG_ VCRIGHT_a110_CH_chNm m110 : 30|1@1+ (1,0) [0|1] "" Vector__XXX
 SG_ VCRIGHT_a110_CH_epochTimeGtw m110 : 31|1@1+ (1,0) [0|1] "" Vector__XXX
 SG_ VCRIGHT_a110_PARTY_carConfig m110 : 32|1@1+ (1,0) [0|1] "" Vector__XXX
 SG_ VCRIGHT_a111_VEH_internalStatus m111 : 16|1@1+ (1,0) [0|1] "" Vector__XXX
 SG_ VCRIGHT_a111_VEH_status m111 : 17|1@1+ (1,0) [0|1] "" Vector__XXX
 SG_ VCRIGHT_a111_VEH_vehNm m111 : 18|1@1+ (1,0) [0|1] "" Vector__XXX
 SG_ VCRIGHT_a111_RIPC_LVPowerState m111 : 19|1@1+ (1,0) [0|1] "" Vector__XXX
 SG_ VCRIGHT_a111_RIPC_epbPrivateStat m111 : 20|1@1+ (1,0) [0|1] "" Vector__XXX
 SG_ VCRIGHT_a111_RIPC_railStatus m111 : 21|1@1+ (1,0) [0|1] "" Vector__XXX
 SG_ VCRIGHT_a111_RIPC_remoteADC m111 : 22|1@1+ (1,0) [0|1] "" Vector__XXX
 SG_ VCRIGHT_a111_RIPC_switchStatus m111 : 23|1@1+ (1,0) [0|1] "" Vector__XXX
 SG_ VCRIGHT_a111_VEH_LVPowerState m111 : 24|1@1+ (1,0) [0|1] "" Vector__XXX
 SG_ VCRIGHT_a111_VEH_seatStatus m111 : 25|1@1+ (1,0) [0|1] "" Vector__XXX
 SG_ VCRIGHT_a111_PARTY_status m111 : 26|1@1+ (1,0) [0|1] "" Vector__XXX
 SG_ VCRIGHT_a111_CH_status m111 : 27|1@1+ (1,0) [0|1] "" Vector__XXX
 SG_ VCRIGHT_a112_VEH_internalStatus m112 : 16|1@1+ (1,0) [0|1] "" Vector__XXX
 SG_ VCRIGHT_a112_VEH_status m112 : 17|1@1+ (1,0) [0|1] "" Vector__XXX
 SG_ VCRIGHT_a112_VEH_vehNm m112 : 18|1@1+ (1,0) [0|1] "" Vector__XXX
 SG_ VCRIGHT_a112_LIPC_LVPowerState m112 : 19|1@1+ (1,0) [0|1] "" Vector__XXX
 SG_ VCRIGHT_a112_LIPC_epbPrivateStat m112 : 20|1@1+ (1,0) [0|1] "" Vector__XXX
 SG_ VCRIGHT_a112_LIPC_railStatus m112 : 21|1@1+ (1,0) [0|1] "" Vector__XXX
 SG_ VCRIGHT_a112_LIPC_remoteADC m112 : 22|1@1+ (1,0) [0|1] "" Vector__XXX
 SG_ VCRIGHT_a112_LIPC_switchStatus m112 : 23|1@1+ (1,0) [0|1] "" Vector__XXX
 SG_ VCRIGHT_a112_VEH_LVPowerState m112 : 24|1@1+ (1,0) [0|1] "" Vector__XXX
 SG_ VCRIGHT_a112_PARTY_status m112 : 25|1@1+ (1,0) [0|1] "" Vector__XXX
 SG_ VCRIGHT_a112_CH_status m112 : 26|1@1+ (1,0) [0|1] "" Vector__XXX
 SG_ VCRIGHT_a114_PARTY_status m114 : 16|1@1+ (1,0) [0|1] "" Vector__XXX
 SG_ VCRIGHT_a114_PARTY_wheelSpeeds m114 : 17|1@1+ (1,0) [0|1] "" Vector__XXX
 SG_ VCRIGHT_a114_VEH_wheelSpeeds m114 : 18|1@1+ (1,0) [0|1] "" Vector__XXX
 SG_ VCRIGHT_a114_CH_wheelSpeeds m114 : 19|1@1+ (1,0) [0|1] "" Vector__XXX
 SG_ VCRIGHT_a114_PARTY_party3 m114 : 20|1@1+ (1,0) [0|1] "" Vector__XXX
 SG_ VCRIGHT_a114_VEH_party3 m114 : 21|1@1+ (1,0) [0|1] "" Vector__XXX
 SG_ VCRIGHT_a114_VEH_status m114 : 22|1@1+ (1,0) [0|1] "" Vector__XXX
 SG_ VCRIGHT_a114_PARTY_wheelRotation m114 : 23|1@1+ (1,0) [0|1] "" Vector__XXX
 SG_ VCRIGHT_a114_CH_wheelRotation m114 : 24|1@1+ (1,0) [0|1] "" Vector__XXX
 SG_ VCRIGHT_a114_VEH_wheelRotation m114 : 25|1@1+ (1,0) [0|1] "" Vector__XXX
 SG_ VCRIGHT_a114_PARTY_brakeTorque m114 : 26|1@1+ (1,0) [0|1] "" Vector__XXX
 SG_ VCRIGHT_a114_PARTY_offsets m114 : 27|1@1+ (1,0) [0|1] "" Vector__XXX
 SG_ VCRIGHT_a114_BDY_offsets m114 : 28|1@1+ (1,0) [0|1] "" Vector__XXX
 SG_ VCRIGHT_a114_BDY_party3 m114 : 29|1@1+ (1,0) [0|1] "" Vector__XXX
 SG_ VCRIGHT_a114_BDY_status m114 : 30|1@1+ (1,0) [0|1] "" Vector__XXX
 SG_ VCRIGHT_a114_BDY_wheelRotation m114 : 31|1@1+ (1,0) [0|1] "" Vector__XXX
 SG_ VCRIGHT_a114_BDY_wheelSpeeds m114 : 32|1@1+ (1,0) [0|1] "" Vector__XXX
 SG_ VCRIGHT_a114_CH_party1 m114 : 33|1@1+ (1,0) [0|1] "" Vector__XXX
 SG_ VCRIGHT_a114_CH_party3 m114 : 34|1@1+ (1,0) [0|1] "" Vector__XXX
 SG_ VCRIGHT_a114_CH_status m114 : 35|1@1+ (1,0) [0|1] "" Vector__XXX
 SG_ VCRIGHT_a115_VEH_vehNm m115 : 16|1@1+ (1,0) [0|1] "" Vector__XXX
 SG_ VCRIGHT_a115_VEH_authentication m115 : 17|1@1+ (1,0) [0|1] "" Vector__XXX
 SG_ VCRIGHT_a115_VEH_BLEResetRequest m115 : 18|1@1+ (1,0) [0|1] "" Vector__XXX
 SG_ VCRIGHT_a115_VEH_requests m115 : 19|1@1+ (1,0) [0|1] "" Vector__XXX
 SG_ VCRIGHT_a115_VEH_requests2 m115 : 20|1@1+ (1,0) [0|1] "" Vector__XXX
 SG_ VCRIGHT_a115_REM_authentication m115 : 21|1@1+ (1,0) [0|1] "" Vector__XXX
 SG_ VCRIGHT_a115_UI_corianderVehicle m115 : 22|1@1+ (1,0) [0|1] "" Vector__XXX
 SG_ VCRIGHT_a115_CH_TPMSDisplay m115 : 23|1@1+ (1,0) [0|1] "" Vector__XXX
 SG_ VCRIGHT_a115_VEH_RSSI m115 : 24|1@1+ (1,0) [0|1] "" Vector__XXX
 SG_ VCRIGHT_a115_VEH_authenticationW m115 : 25|1@1+ (1,0) [0|1] "" Vector__XXX
 SG_ VCRIGHT_a115_VEH_endpointTemp m115 : 26|1@1+ (1,0) [0|1] "" Vector__XXX
 SG_ VCRIGHT_a115_VEH_ChildSeatStatus m115 : 27|1@1+ (1,0) [0|1] "" Vector__XXX
 SG_ VCRIGHT_a115_BDY_ChildSeatStatus m115 : 28|1@1+ (1,0) [0|1] "" Vector__XXX
 SG_ VCRIGHT_a115_BDY_endpointTemp m115 : 42|1@1+ (1,0) [0|1] "" Vector__XXX
 SG_ VCRIGHT_a115_BDY_BLEResetRequest m115 : 48|1@1+ (1,0) [0|1] "" Vector__XXX
 SG_ VCRIGHT_a115_BDY_RSSI m115 : 49|1@1+ (1,0) [0|1] "" Vector__XXX
 SG_ VCRIGHT_a115_BDY_authentication m115 : 50|1@1+ (1,0) [0|1] "" Vector__XXX
 SG_ VCRIGHT_a115_BDY_requests m115 : 51|1@1+ (1,0) [0|1] "" Vector__XXX
 SG_ VCRIGHT_a115_BDY_requests2 m115 : 52|1@1+ (1,0) [0|1] "" Vector__XXX

BO_TX_BU_ 727 : VCLEFT;
BO_TX_BU_ 1860 : VCLEFT;
BO_TX_BU_ 1863 : VCLEFT;
BO_TX_BU_ 1250 : VCLEFT;
BO_TX_BU_ 738 : VCLEFT;
BO_TX_BU_ 930 : VCLEFT;
BO_TX_BU_ 610 : VCLEFT;
BO_TX_BU_ 962 : VCLEFT;
BO_TX_BU_ 656 : VCLEFT;
BO_TX_BU_ 657 : VCLEFT;
BO_TX_BU_ 386 : VCLEFT;
BO_TX_BU_ 1571 : VCLEFT;
BO_TX_BU_ 706 : VCLEFT;
BO_TX_BU_ 1114 : VCRIGHT;
BO_TX_BU_ 1124 : VCRIGHT;
BO_TX_BU_ 549 : VCRIGHT;
BO_TX_BU_ 643 : VCRIGHT;
BO_TX_BU_ 2011 : VCRIGHT;
CM_ BO_ 727 "Left body controller message: pitch estimation";
CM_ SG_ 727 VCLEFT_pitchEstimateFusionState "Left body controller: pitch estimate fusion state";
CM_ SG_ 727 VCLEFT_pitchEstimateStateTransit "Left body controller: pitch estimate state transition ID";
CM_ SG_ 727 VCLEFT_pitchEstimateArbitratedSt "Left body controller: pitch estimate arbitrated state";
CM_ SG_ 727 VCLEFT_pitchEstimateOKForAiming "Left body controller: pitch estimate OK for aiming";
CM_ SG_ 727 VCLEFT_pitchEstimateFusionRaw "Left body controller: pitch estimate fusion raw";
CM_ SG_ 727 VCLEFT_pitchEstimate "Left body controller: pitch estimate; raw 512 = signal not available (SNA)";
CM_ BO_ 1860 "Left body controller message: recall status";
CM_ SG_ 1860 VCLEFT_systemRecallStatus "Left body controller: system recall status; raw 0 = signal not available (SNA)";
CM_ SG_ 1860 VCLEFT_seatRecallStatus "Left body controller: seat recall status; raw 0 = signal not available (SNA)";
CM_ SG_ 1860 VCLEFT_columnRecallStatus "Left body controller: column recall status; raw 0 = signal not available (SNA)";
CM_ SG_ 1860 VCLEFT_mirrorRecallStatus "Recall status for the left side view mirror; raw 0 = signal not available (SNA)";
CM_ BO_ 1863 "Left body controller message: restraint status";
CM_ SG_ 1863 VCLEFT_frontOccupancyStatus "Left body controller: front occupancy status; raw 7 = signal not available (SNA)";
CM_ SG_ 1863 VCLEFT_frontBuckleStatus "Status of front left seatbelt buckle";
CM_ SG_ 1863 VCLEFT_rearLeftOccupancyStatus "Status of rear left seat occupancy sensor";
CM_ SG_ 1863 VCLEFT_rearCenterOccupancyStatus "Status of rear center seat occupancy sensor";
CM_ SG_ 1863 VCLEFT_rearRightOccupancyStatus "Status of rear right seat occupancy sensor";
CM_ SG_ 1863 VCLEFT_rearLeftBuckleStatus "Status of rear left seatbelt buckle";
CM_ SG_ 1863 VCLEFT_rearCenterBuckleStatus "Status of rear center seatbelt buckle";
CM_ SG_ 1863 VCLEFT_seatTrackPosition "Status of seat track position sensor; raw 7 = signal not available (SNA)";
CM_ SG_ 1863 VCLEFT_3RowLeftABStatus "Reports status of third row left airbag suppression; raw 2 = signal not available (SNA)";
CM_ SG_ 1863 VCLEFT_3RowLeftBuckleStatus "Reports status of third row left seatbelt buckle";
CM_ SG_ 1863 VCLEFT_restraintStatusCounter "Left body controller: restraint status counter";
CM_ SG_ 1863 VCLEFT_restraintStatusChecksum "Left body controller: restraint status checksum";
CM_ BO_ 1250 "Left body controller message: seat status";
CM_ SG_ 1250 VCLEFT_seatStatusIndex "Left body controller: seat status index";
CM_ SG_ 1250 VC_AH_1RowLeftSeatMovementHealth "Left body controller: AH 1 row left seat movement health";
CM_ SG_ 1250 VCLEFT_frontSeatTrackPos "communicates raw encoder count for driver seat track position";
CM_ SG_ 1250 VCLEFT_frontSeatTrackCurrent "Current drawn by front left seat track motor";
CM_ SG_ 1250 VCLEFT_frontSeatTrackDuty "Front left seat track motor duty cycle";
CM_ SG_ 1250 VCLEFT_frontSeatTrackState "State of front left seat track motor";
CM_ SG_ 1250 VCLEFT_frontSeatTrackCalibrated "Left body controller: front seat track calibrated";
CM_ SG_ 1250 VCLEFT_frontSeatTrackLog "Left body controller: front seat track log";
CM_ SG_ 1250 VCLEFT_frontSeatTrackBridgeSt "Bridge state";
CM_ SG_ 1250 VCLEFT_frontSeatTrackPercentage "Communicates position of front seat track as percentage of its total range";
CM_ SG_ 1250 VCLEFT_frontSeatBackPos "communicates raw encoder count for driver seat backrest position";
CM_ SG_ 1250 VCLEFT_frontSeatBackCurrent "Current drawn by front left seat backrest motor";
CM_ SG_ 1250 VCLEFT_frontSeatBackDuty "Front left seat backrest motor duty cycle";
CM_ SG_ 1250 VCLEFT_frontSeatBackState "Active state of front left seat backrest";
CM_ SG_ 1250 VCLEFT_frontSeatBackCalibrated "Left body controller: front seat back calibrated";
CM_ SG_ 1250 VCLEFT_frontSeatBackLog "Left body controller: front seat back log";
CM_ SG_ 1250 VCLEFT_frontSeatBackBridgeSt "Bridge state";
CM_ SG_ 1250 VCLEFT_frontSeatBackPercentage "Communicates position of front seat backrest recline as percentage of its total range";
CM_ SG_ 1250 VCLEFT_frontSeatLiftPos "communicates raw encoder count for driver seat lift position";
CM_ SG_ 1250 VCLEFT_frontSeatLiftCurrent "Current drawn by front left seat lift motor";
CM_ SG_ 1250 VCLEFT_frontSeatLiftDuty "Front left seat lift motor duty cycle";
CM_ SG_ 1250 VCLEFT_frontSeatLiftState "Status of front left seat motor";
CM_ SG_ 1250 VCLEFT_frontSeatLiftCalibrated "Left body controller: front seat lift calibrated";
CM_ SG_ 1250 VCLEFT_frontSeatLiftLog "Left body controller: front seat lift log";
CM_ SG_ 1250 VCLEFT_frontSeatLiftBridgeSt "Bridge state";
CM_ SG_ 1250 VCLEFT_frontSeatLiftPercentage "Communicates position of front seat lift as percentage of its total range";
CM_ SG_ 1250 VCLEFT_frontSeatTiltPos "communicates raw encoder count for driver seat tile position";
CM_ SG_ 1250 VCLEFT_frontSeatTiltCurrent "Current drawn by front left seat tilt motor";
CM_ SG_ 1250 VCLEFT_frontSeatTiltDuty "Front left seat tilt motor duty cycle";
CM_ SG_ 1250 VCLEFT_frontSeatTiltState "State of front left seat tilt motor";
CM_ SG_ 1250 VCLEFT_frontSeatTiltCalibrated "Left body controller: front seat tilt calibrated";
CM_ SG_ 1250 VCLEFT_frontSeatTiltLog "Left body controller: front seat tilt log";
CM_ SG_ 1250 VCLEFT_frontSeatTiltBridgeSt "Bridge state";
CM_ SG_ 1250 VCLEFT_frontSeatTiltPercentage "Communicates position of front seat tilt as percentage of its total range";
CM_ SG_ 1250 VCLEFT_lumbarAState "State of front left seat lumbar bladder A";
CM_ SG_ 1250 VCLEFT_lumbarBState "State of front left lumbar bladder B";
CM_ SG_ 1250 VCLEFT_lumbarAPressureHpa "Left body controller: lumbar a pressure hpa";
CM_ SG_ 1250 VCLEFT_lumbarAPressureHpaFilt "logs filtered pressure of left seat lumbar bladder A";
CM_ SG_ 1250 VCLEFT_lumbarBPressureHpa "Left body controller: lumbar b pressure hpa";
CM_ SG_ 1250 VCLEFT_lumbarBPressureHpaFilt "logs filtered pressure of left seat lumbar bladder B";
CM_ SG_ 1250 VCLEFT_lumbarActiveTooLongErr "Error reported by lumbar ECU: Valve activated too long";
CM_ SG_ 1250 VCLEFT_lumbarMaxPErr "Error reported by lumbar ECU: max bladder pressure reached";
CM_ SG_ 1250 VCLEFT_lumbarOvercurrentErr "Error reported by lumbar ECU: pump overcurrent";
CM_ SG_ 1250 VCLEFT_lumbarMaxOperatingPErr "Error reported by lumbar ECU: max bladder operating pressure reached";
CM_ SG_ 1250 VCLEFT_lumbarMinPErr "Error reported by lumbar ECU: min bladder pressure reached";
CM_ SG_ 1250 VCLEFT_lumbarGeneralErr "Error reported by lumbar ECU: general error";
CM_ SG_ 1250 VCLEFT_lumbarDevMaxPumpPressA "System has reached Tesla specified maximum pressure for lumbar bladder A";
CM_ SG_ 1250 VCLEFT_lumbarDevMaxPumpPressB "System has reached Tesla specified maximum pressure for lumbar bladder B";
CM_ SG_ 1250 VCLEFT_frontSeatTrackPosReal "communicates position of driver seat track in a physical unit";
CM_ SG_ 1250 VCLEFT_frontSeatBackPosReal "communicates position of driver seat backrest in degrees";
CM_ SG_ 1250 VCLEFT_frontSeatLiftPosReal "communicates position of driver seat lift in a physical unit";
CM_ SG_ 1250 VCLEFT_frontSeatTiltPosReal "communicates position of driver seat tilt in a physical unit";
CM_ SG_ 1250 VCLEFT_frontSeatThighSupportPosR "Position of front seat thigh support in a physical unit";
CM_ SG_ 1250 VCLEFT_frontSeatTrackPosOffset "Communicates post calibration position offset of front left seat track in a physical unit";
CM_ SG_ 1250 VCLEFT_frontSeatBackPosOffset "Communicates post calibration position offset of front left seat backrest in degrees";
CM_ SG_ 1250 VCLEFT_frontSeatLiftPosOffset "Communicates post calibration position offset of front left seat lift in a physical unit";
CM_ SG_ 1250 VCLEFT_frontSeatTiltPosOffset "Communicates post calibration position offset of front left seat tilt in a physical unit";
CM_ SG_ 1250 VCLEFT_frontSeatThighSupportPosO "Post calibration position offset of front seat thigh support in a physical unit";
CM_ SG_ 1250 VCLEFT_lumbarAPressurePercentage "Percentage of lumbar bladder A pressure relative to maximum pressure";
CM_ SG_ 1250 VCLEFT_lumbarBPressurePercentage "Percentage of lumbar bladder B pressure relative to maximum pressure";
CM_ BO_ 738 "Left body controller message: seat status2";
CM_ SG_ 738 VCLEFT_seatStatus2Index "Left body controller: seat status2 index";
CM_ SG_ 738 VCLEFT_frontSeatHeatCurrent "Left body controller: front seat heat current; raw 12 = signal not available (SNA)";
CM_ SG_ 738 VCLEFT_frontSeatHeatDuty "Left body controller: front seat heat duty";
CM_ SG_ 738 VCLEFT_frontSeatHeatTmp "Left body controller: front seat heat tmp";
CM_ SG_ 738 VCLEFT_frontSeatHeatTmpTarget "Left body controller: front seat heat tmp target";
CM_ SG_ 738 VCLEFT_frontSeatHeatInhibited "Left body controller: front seat heat inhibited";
CM_ SG_ 738 VCLEFT_frontSeatHeatPowered "Left body controller: front seat heat powered";
CM_ SG_ 738 VCLEFT_2RowSeatFoldLeftSwitch "Reports status of the left seat fold switch in the second row; raw 0 = signal not available (SNA)";
CM_ SG_ 738 VCLEFT_2RowSeatUnfoldLeftSwitch "Reports status of the left seat unfold switch in the second row; raw 0 = signal not available (SNA)";
CM_ SG_ 738 VCLEFT_2RowSeatFoldRightSwitch "Reports status of the right seat fold switch in the second row; raw 0 = signal not available (SNA)";
CM_ SG_ 738 VCLEFT_2RowSeatUnfoldRightSwitch "Reports status of the right seat unfold switch in the second row; raw 0 = signal not available (SNA)";
CM_ SG_ 738 VCLEFT_3RowSeatFoldLeftSwitch "Reports status of the left seat fold switch in the third row; raw 0 = signal not available (SNA)";
CM_ SG_ 738 VCLEFT_3RowSeatUnfoldLeftSwitch "Reports status of the left seat unfold switch in the third row; raw 0 = signal not available (SNA)";
CM_ SG_ 738 VCLEFT_3RowSeatFoldRightSwitch "Reports status of the right seat fold switch in the third row; raw 0 = signal not available (SNA)";
CM_ SG_ 738 VCLEFT_3RowSeatUnfoldRightSwitch "Reports status of the right seat unfold switch in the third row; raw 0 = signal not available (SNA)";
CM_ SG_ 738 VC_AH_1RowLeftSeatHeatVentHealth "Left body controller: AH 1 row left seat heat vent health";
CM_ SG_ 738 VCLEFT_2RowSeatReclineState "Reports the active state of the 2nd row seat recliner; raw 15 = signal not available (SNA)";
CM_ SG_ 738 VCLEFT_2RowSeatReclineDuty "Reports the 2nd row seat recliner motor duty cycle";
CM_ SG_ 738 VCLEFT_2RowSeatReclineCurrent "Reports the 2nd row seat recliner motor current";
CM_ SG_ 738 VCLEFT_2RowSeatReclineCalibrated "Reports calibration status of the 2nd row seat recliner";
CM_ SG_ 738 VCLEFT_2RowSeatReclinePositionRa "Reports the 2nd row seat recliner raw encoder count";
CM_ SG_ 738 VCLEFT_2RowSeatReclineAngle "Reports the position of the 2nd row seat recliner in degrees";
CM_ SG_ 738 VCLEFT_2RowSeatReclineAbsPosSwit "Reports the status of 2nd row seat recline absolute position (comfort zone) switch; raw 0 = signal not available (SNA)";
CM_ SG_ 738 VCLEFT_2RowSeatReclinePositionSt "Reports the active position state of the 2nd row seat recliner; raw 4 = signal not available (SNA)";
CM_ SG_ 738 VCLEFT_2RowSeatReclineAdjustment "Indicates whether adjustment requests are currently permitted for the rear seat recliner";
CM_ SG_ 738 VCLEFT_2RowSeatReclineFoldAllowe "Indicates whether auto-fold requests are currently permitted for the rear seat recliner";
CM_ SG_ 738 VCLEFT_2RowSeatReclineUnfoldAllo "Indicates whether auto-unfold requests are currently permitted for the rear seat recliner";
CM_ SG_ 738 VCLEFT_2RowSeatReclineNextToggle "Left body controller: 2 row seat recline next toggle direction; raw 2 = signal not available (SNA)";
CM_ SG_ 738 VCLEFT_2RowSeatReclineChoreoBloc "Left body controller: 2 row seat recline choreo blocked by occupancy";
CM_ SG_ 738 VCLEFT_2RowSeat1RClashAvoidanceB "Left body controller: 2 row seat1 r clash avoidance blocked reason";
CM_ SG_ 738 VCLEFT_2RowSeat1RClashAvoidanceS "Left body controller: 2 row seat1 r clash avoidance state";
CM_ SG_ 738 VCLEFT_2RowSeatReclineAbsPo_0001 "Left body controller: 2 row seat recline abs pos switch trans point";
CM_ SG_ 738 VC_AH_2RowLeftSeatMovementHealth "Left body controller: AH 2 row left seat movement health";
CM_ SG_ 738 VCLEFT_3RowSeatReclineState "Reports active state of the rear seat recliner; raw 15 = signal not available (SNA)";
CM_ SG_ 738 VCLEFT_3RowSeatReclineDuty "Reports the third row seat recliner motor duty cycle";
CM_ SG_ 738 VCLEFT_3RowSeatReclineCurrent "Reports the third row seat recliner motor current";
CM_ SG_ 738 VCLEFT_3RowSeatReclineCalibrated "Reports calibration status of the third row seat recliner";
CM_ SG_ 738 VCLEFT_3RowSeatReclinePositionRa "Reports the third row seat recliner raw encoder count";
CM_ SG_ 738 VCLEFT_3RowSeatReclineAngle "Reports position of the 3rd row seat recliner in degrees";
CM_ SG_ 738 VCLEFT_3RowSeatReclineNextToggle "Left body controller: 3 row seat recline next toggle direction; raw 2 = signal not available (SNA)";
CM_ SG_ 738 VCLEFT_3RRightCushionHeatCurrent "Current drawn by 3rd row right seat heater";
CM_ SG_ 738 VCLEFT_3RRightCushionHeatDuty "3rd row right seat heater duty cycle";
CM_ SG_ 738 VCLEFT_3RRightCushionHeatTmp "Left body controller: 3 r right cushion heat tmp";
CM_ SG_ 738 VCLEFT_3RRightCushionHeatTmpTarg "Target temperature for 3rd row right seat heater";
CM_ SG_ 738 VCLEFT_3RRightCushionHeatInhibit "Status describing whether 3rd row right seat heat is inhibited";
CM_ SG_ 738 VCLEFT_3RowSeatReclinePositionSt "Reports active position state of the rear seat recliner; raw 4 = signal not available (SNA)";
CM_ SG_ 738 VCLEFT_3RowSeatReclineAdjustment "Indicates whether adjustment requests are currently permitted for the rear seat recliner";
CM_ SG_ 738 VCLEFT_3RowSeatReclineFoldAllowe "Indicates whether auto-fold requests are currently permitted for the rear seat recliner";
CM_ SG_ 738 VCLEFT_3RowSeatReclineUnfoldAllo "Indicates whether auto-unfold requests are currently permitted for the rear seat recliner";
CM_ SG_ 738 VCLEFT_3RowSeatReclineChoreoBloc "Left body controller: 3 row seat recline choreo blocked by occupancy";
CM_ SG_ 738 VCLEFT_3RowSeatReclineAbsPosSwit "Reports status of 2R seat recline absolute position (comfort zone) switch; raw 0 = signal not available (SNA)";
CM_ BO_ 930 "Left body controller message: status";
CM_ SG_ 930 VCLEFT_statusIndex "Left body controller: status index";
CM_ SG_ 930 VCLEFT_securityControllerEnable "Left body controller: security controller enable";
CM_ SG_ 930 VCLEFT_securityControllerVoltage "Voltage of the VCSEC power feed";
CM_ SG_ 930 VCLEFT_consoleDoorAssist "Left body controller: console door assist";
CM_ SG_ 930 VCLEFT_OTAState "Left body controller: OTA state";
CM_ SG_ 930 VCLEFT_5AVoltage "Left body controller: 5 a voltage";
CM_ SG_ 930 VCLEFT_vbatProt "Left body controller: vbat prot";
CM_ SG_ 930 VCLEFT_footwellLightCurrent "Left body controller: footwell light current";
CM_ SG_ 930 VCLEFT_swcInputVoltage "Input voltage reported by steering wheel controller module; raw 255 = signal not available (SNA)";
CM_ SG_ 930 VCLEFT_swcPCBATemperature "Left body controller: swc PCBA temperature; raw 128 = signal not available (SNA)";
CM_ SG_ 930 VCLEFT_obdEthernetActive "Left body controller: obd ethernet active";
CM_ SG_ 930 VCLEFT_rationalityAggregateCurre "Left body controller: rationality aggregate current";
CM_ SG_ 930 VCLEFT_LVBatteryTypeDBG "Left body controller: LV battery type DBG";
CM_ SG_ 930 VCLEFT_DIeFuseFault "Left body controller: d ie fuse fault";
CM_ SG_ 930 VCLEFT_eFuseMgmtVoltageMonitor "Left body controller: e fuse mgmt voltage monitor";
CM_ SG_ 930 VCLEFT_trailerAuxCurrent "Current Draw of the trailer aux output; raw 4095 = signal not available (SNA)";
CM_ SG_ 930 VCLEFT_swcHeatTmp "Temperature of steering wheel heater as reported by NTC; raw 1023 = signal not available (SNA)";
CM_ SG_ 930 VCLEFT_swcHeatStatus "Status of steering wheel heater; raw 0 = signal not available (SNA)";
CM_ SG_ 930 VCLEFT_swcHeatInhibited "Status describing whether steering wheel heat is inhibited";
CM_ SG_ 930 VCLEFT_obdDeviceDetected "Reports whether the Left Vehicle Controller (VCLEFT) detects that an external device is connected to the OBD port.";
CM_ SG_ 930 VCLEFT_pcbaTemperature "Left body controller: pcba temperature";
CM_ SG_ 930 VCLEFT_swcHeatPwr "Power of steering wheel heater; raw 511 = signal not available (SNA)";
CM_ SG_ 930 VCLEFT_swcHeatDutyCycle "Steering wheel heater duty cycle; raw 127 = signal not available (SNA)";
CM_ SG_ 930 VCLEFT_DIeFuseCurrent "Left body controller: d ie fuse current";
CM_ SG_ 930 VCLEFT_SWCpresent "Left body controller: SW cpresent";
CM_ SG_ 930 VCLEFT_trailerBrakeControllerCur "Value of the trailer brake controller HSD (high side driver) current sense.";
CM_ SG_ 930 VCLEFT_autonomyBehaviorStatus "Left body controller: autonomy behavior status";
CM_ SG_ 930 VCLEFT_thirdRowLeftMapLightStatu "Reports the status of the third row left overhead map light; raw 3 = signal not available (SNA)";
CM_ SG_ 930 VCLEFT_thirdRowRightMapLightStat "Reports the status of the third row right overhead map light; raw 3 = signal not available (SNA)";
CM_ BO_ 610 "Left body controller message: steering column status";
CM_ SG_ 610 VCLEFT_steeringColumnSMState "Status of steering column state machine; raw 0 = signal not available (SNA)";
CM_ SG_ 610 VCLEFT_steeringColumnLastRequest "Left body controller: steering column last request; raw 0 = signal not available (SNA)";
CM_ SG_ 610 VCLEFT_steeringColumnUpDownDuty "Steering column tilt motor duty cycle";
CM_ SG_ 610 VCLEFT_steeringColumnInOutDuty "Steering column telescope motor duty cycle";
CM_ SG_ 610 VCLEFT_steeringColumnUpDownPos "Motor encoder value representing steering column tilt position";
CM_ SG_ 610 VCLEFT_steeringColumnInOutPos "Motor encoder value representing steering column telescope position";
CM_ SG_ 610 VCLEFT_steeringColumnUpDownAmps "Measures current used by the steering column tilt motor.";
CM_ SG_ 610 VCLEFT_steeringColumnInOutAmps "Measures current used by the steering column telescope motor.";
CM_ SG_ 610 VCLEFT_steeringColumnUpDownCalib "Left body controller: steering column up down calib";
CM_ SG_ 610 VCLEFT_steeringColumnInOutCalib "Left body controller: steering column in out calib";
CM_ SG_ 610 VCLEFT_steeringColumnUpDownTC "Left body controller: steering column up down TC";
CM_ SG_ 610 VCLEFT_steeringColumnInOutTC "Left body controller: steering column in out TC";
CM_ BO_ 962 "Left body controller message: switch status";
CM_ SG_ 962 VCLEFT_switchStatusIndex "Left body controller: switch status index";
CM_ SG_ 962 VCLEFT_hornSwitchPressed "Left body controller: horn switch pressed";
CM_ SG_ 962 VCLEFT_hazardButtonPressed "Left body controller: hazard button pressed";
CM_ SG_ 962 VCLEFT_brakeSwitchPressed "Status of the brake pedal switch";
CM_ SG_ 962 VCLEFT_rightMirrorTilt "Left body controller: right mirror tilt";
CM_ SG_ 962 VCLEFT_frontSeatTrackBack "Left body controller: front seat track back; raw 0 = signal not available (SNA)";
CM_ SG_ 962 VCLEFT_frontSeatTrackForward "Left body controller: front seat track forward; raw 0 = signal not available (SNA)";
CM_ SG_ 962 VCLEFT_frontSeatTiltDown "Left body controller: front seat tilt down; raw 0 = signal not available (SNA)";
CM_ SG_ 962 VCLEFT_frontSeatTiltUp "Left body controller: front seat tilt up; raw 0 = signal not available (SNA)";
CM_ SG_ 962 VCLEFT_frontSeatLiftDown "Left body controller: front seat lift down; raw 0 = signal not available (SNA)";
CM_ SG_ 962 VCLEFT_frontSeatLiftUp "Left body controller: front seat lift up; raw 0 = signal not available (SNA)";
CM_ SG_ 962 VCLEFT_frontSeatBackrestBack "Left body controller: front seat backrest back; raw 0 = signal not available (SNA)";
CM_ SG_ 962 VCLEFT_frontSeatBackrestForward "Left body controller: front seat backrest forward; raw 0 = signal not available (SNA)";
CM_ SG_ 962 VCLEFT_frontSeatLumbarDown "Left body controller: front seat lumbar down; raw 0 = signal not available (SNA)";
CM_ SG_ 962 VCLEFT_frontSeatLumbarUp "Left body controller: front seat lumbar up; raw 0 = signal not available (SNA)";
CM_ SG_ 962 VCLEFT_frontSeatLumbarIn "Left body controller: front seat lumbar in; raw 0 = signal not available (SNA)";
CM_ SG_ 962 VCLEFT_frontSeatLumbarOut "Left body controller: front seat lumbar out; raw 0 = signal not available (SNA)";
CM_ SG_ 962 VCLEFT_btnWindowSwPackUpLF "Left body controller: btn window sw pack up LF";
CM_ SG_ 962 VCLEFT_btnWindowSwPackAutoUpLF "Left body controller: btn window sw pack auto up LF";
CM_ SG_ 962 VCLEFT_btnWindowSwPackDownLF "Left body controller: btn window sw pack down LF";
CM_ SG_ 962 VCLEFT_btnWindowSwPackAutoDownLF "Left body controller: btn window sw pack auto down LF";
CM_ SG_ 962 VCLEFT_btnWindowSwPackUpLR "Left body controller: btn window sw pack up LR";
CM_ SG_ 962 VCLEFT_btnWindowSwPackAutoUpLR "Left body controller: btn window sw pack auto up LR";
CM_ SG_ 962 VCLEFT_btnWindowSwPackDownLR "Left body controller: btn window sw pack down LR";
CM_ SG_ 962 VCLEFT_btnWindowSwPackAutoDownLR "Left body controller: btn window sw pack auto down LR";
CM_ SG_ 962 VCLEFT_btnWindowSwPackUpRF "Left body controller: btn window sw pack up RF";
CM_ SG_ 962 VCLEFT_btnWindowSwPackAutoUpRF "Left body controller: btn window sw pack auto up RF";
CM_ SG_ 962 VCLEFT_btnWindowSwPackDownRF "Left body controller: btn window sw pack down RF";
CM_ SG_ 962 VCLEFT_btnWindowSwPackAutoDownRF "Left body controller: btn window sw pack auto down RF";
CM_ SG_ 962 VCLEFT_btnWindowSwPackUpRR "Left body controller: btn window sw pack up RR";
CM_ SG_ 962 VCLEFT_btnWindowSwPackAutoUpRR "Left body controller: btn window sw pack auto up RR";
CM_ SG_ 962 VCLEFT_btnWindowSwPackDownRR "Left body controller: btn window sw pack down RR";
CM_ SG_ 962 VCLEFT_btnWindowSwPackAutoDownRR "Left body controller: btn window sw pack auto down RR";
CM_ SG_ 962 VCLEFT_frontBuckleSwitch "Left body controller: front buckle switch; raw 0 = signal not available (SNA)";
CM_ SG_ 962 VCLEFT_frontOccupancySwitch "Front left seat occupancy status; raw 0 = signal not available (SNA)";
CM_ SG_ 962 VCLEFT_rearLeftBuckleSwitch "Left body controller: rear left buckle switch; raw 0 = signal not available (SNA)";
CM_ SG_ 962 VCLEFT_rearCenterOccupancySwitch "Left body controller: rear center occupancy switch; raw 0 = signal not available (SNA)";
CM_ SG_ 962 VCLEFT_rearLeftOccupancySwitch "Left body controller: rear left occupancy switch; raw 0 = signal not available (SNA)";
CM_ SG_ 962 VCLEFT_rearRightOccupancySwitch "Left body controller: rear right occupancy switch; raw 0 = signal not available (SNA)";
CM_ SG_ 962 VCLEFT_brakePressed "Status of the brake pedal";
CM_ SG_ 962 VCLEFT_rearHVACButtonPressed "Left body controller: rear HVAC button pressed";
CM_ SG_ 962 VCLEFT_rearCenterBuckleSwitch "Left body controller: rear center buckle switch; raw 0 = signal not available (SNA)";
CM_ SG_ 962 VCLEFT_isAlcoholInterlockSet "Reports if the alcohol interlock is set.";
CM_ SG_ 962 VCLEFT_swcLeftTiltRight "Left body controller: swc left tilt right; raw 0 = signal not available (SNA)";
CM_ SG_ 962 VCLEFT_swcLeftPressed "Left body controller: swc left pressed; raw 0 = signal not available (SNA)";
CM_ SG_ 962 VCLEFT_swcRightTiltLeft "Left body controller: swc right tilt left; raw 0 = signal not available (SNA)";
CM_ SG_ 962 VCLEFT_swcRightTiltRight "Left body controller: swc right tilt right; raw 0 = signal not available (SNA)";
CM_ SG_ 962 VCLEFT_swcRightPressed "Left body controller: swc right pressed; raw 0 = signal not available (SNA)";
CM_ SG_ 962 VCLEFT_swcLeftTiltLeft "Left body controller: swc left tilt left; raw 0 = signal not available (SNA)";
CM_ SG_ 962 VCLEFT_swcLeftScrollTicks "Left body controller: swc left scroll ticks";
CM_ SG_ 962 VCLEFT_swcWiperButtonState "Left body controller: swc wiper button state";
CM_ SG_ 962 VCLEFT_swcRightScrollTicks "Encoder value for right steering wheel switch scroll";
CM_ SG_ 962 VCLEFT_swcTurnSignalLeftButtonSt "Left body controller: swc turn signal left button state";
CM_ SG_ 962 VCLEFT_btnWindowUpLR "Left body controller: btn window up LR";
CM_ SG_ 962 VCLEFT_btnWindowAutoUpLR "Left body controller: btn window auto up LR";
CM_ SG_ 962 VCLEFT_btnWindowDownLR "Left body controller: btn window down LR";
CM_ SG_ 962 VCLEFT_btnWindowAutoDownLR "Left body controller: btn window auto down LR";
CM_ SG_ 962 VCLEFT_2RowSeatReclineSwitch "Second row seat recline switch";
CM_ SG_ 962 VCLEFT_2RowSeatCenterSwitch "Second row seat center switch";
CM_ SG_ 962 VCLEFT_2RowSeatLeftFoldFlatSwitc "Second row seat left fold flat switch";
CM_ SG_ 962 VCLEFT_2RowSeatRightFoldFlatSwit "Second row seat right fold flat switch";
CM_ SG_ 962 VCLEFT_2RowSeatBothFoldFlatSwitc "Second row seat both fold flat switch";
CM_ SG_ 962 VCLEFT_swcLeftDoublePress "Left body controller: swc left double press";
CM_ SG_ 962 VCLEFT_swcRightDoublePress "Left body controller: swc right double press";
CM_ SG_ 962 VCLEFT_2RowSeatBackrestFoldSwitc "Second row seat backrest fold switch";
CM_ SG_ 962 VCLEFT_swcTurnSignalRightButtonS "Left body controller: swc turn signal right button state";
CM_ SG_ 962 VCLEFT_swcHighBeamButtonState "Left body controller: swc high beam button state";
CM_ SG_ 962 VCLEFT_swcVoiceControlPress "Left body controller: swc voice control press; raw 0 = signal not available (SNA)";
CM_ SG_ 962 VCLEFT_swcCameraButtonState "Left body controller: swc camera button state";
CM_ SG_ 962 VCLEFT_swcRightPressedQF "Quality of steering wheel right scroll wheel button signal";
CM_ SG_ 962 VCLEFT_2RowSeatReclineSwitchpack "State of the left second row powered recline adjustment switchpack";
CM_ SG_ 962 VCLEFT_3RowLeftBuckleSwitch "Report status of 3rd row left seatbelt buckle; raw 0 = signal not available (SNA)";
CM_ SG_ 962 VCLEFT_frontSeatThighSupportExte "Status of the switch used to extend front seat thigh support; raw 0 = signal not available (SNA)";
CM_ SG_ 962 VCLEFT_frontSeatThighSupportRetr "Status of the switch used to retract front seat thigh support; raw 0 = signal not available (SNA)";
CM_ SG_ 962 VCLEFT_frontSeatResistiveOccupan "Front left seat occupancy status; raw 0 = signal not available (SNA)";
CM_ BO_ 656 "Left body controller message: thermal logging10 hz";
CM_ SG_ 656 VCLEFT_thermalLogging10HzIndex "Left body controller: thermal logging10 hz index";
CM_ SG_ 656 VCLEFT_hvac2RLeftLateralVoltage "Left body controller: hvac2 r left lateral voltage";
CM_ SG_ 656 VCLEFT_hvac2RLeftVerticalVoltage "Left body controller: hvac2 r left vertical voltage";
CM_ SG_ 656 VCLEFT_hvac2RRightLateralVoltage "Left body controller: hvac2 r right lateral voltage";
CM_ SG_ 656 VCLEFT_hvac2RRightVerticalVoltag "Left body controller: hvac2 r right vertical voltage";
CM_ SG_ 656 VCLEFT_hvac2RLeftLateralCalibrat "Left body controller: hvac2 r left lateral calibrated";
CM_ SG_ 656 VCLEFT_hvac2RLeftVerticalCalibra "Left body controller: hvac2 r left vertical calibrated";
CM_ SG_ 656 VCLEFT_hvac2RRightLateralCalibra "Left body controller: hvac2 r right lateral calibrated";
CM_ SG_ 656 VCLEFT_hvac2RRightVerticalCalibr "Left body controller: hvac2 r right vertical calibrated";
CM_ SG_ 656 VCLEFT_hvac2RLeftLateralState "Left body controller: hvac2 r left lateral state";
CM_ SG_ 656 VCLEFT_hvac2RLeftVerticalState "Left body controller: hvac2 r left vertical state";
CM_ SG_ 656 VCLEFT_hvac2RRightLateralState "Left body controller: hvac2 r right lateral state";
CM_ SG_ 656 VCLEFT_hvac2RRightVerticalState "Left body controller: hvac2 r right vertical state";
CM_ SG_ 656 VCLEFT_hvacBlowerWindmillElecRpm "Left body controller: hvac blower windmill elec rpm";
CM_ SG_ 656 VCLEFT_hvac2RRightVerticalVeloci "Left body controller: hvac2 r right vertical velocity";
CM_ SG_ 656 VCLEFT_hvacBlowerWindmillBemf "Left body controller: hvac blower windmill bemf";
CM_ SG_ 656 VCLEFT_hvac2RLeftVerticalVelocit "Left body controller: hvac2 r left vertical velocity";
CM_ SG_ 656 VCLEFT_hvac2RLeftLateralVelocity "Left body controller: hvac2 r left lateral velocity";
CM_ SG_ 656 VCLEFT_vcusbLinSchedule "Left body controller: vcusb lin schedule";
CM_ SG_ 656 VCLEFT_hvacBlowerArbState "Left body controller: hvac blower arb state";
CM_ SG_ 656 VCLEFT_hvacBlowerArbResult "Left body controller: hvac blower arb result";
CM_ SG_ 656 VCLEFT_hvac2RLeftLateralDuty "Left body controller: hvac2 r left lateral duty";
CM_ SG_ 656 VCLEFT_hvac2RLeftVerticalDuty "Left body controller: hvac2 r left vertical duty";
CM_ SG_ 656 VCLEFT_hvac2RRightLateralDuty "Left body controller: hvac2 r right lateral duty";
CM_ SG_ 656 VCLEFT_hvac2RRightVerticalDuty "Left body controller: hvac2 r right vertical duty";
CM_ SG_ 656 VCLEFT_hvacBlowerWindmilling "Left body controller: hvac blower windmilling";
CM_ SG_ 656 VCLEFT_hvac2RRightLateralVelocit "Left body controller: hvac2 r right lateral velocity";
CM_ SG_ 656 VCLEFT_hvacBlower1msOverrunFrequ "Left body controller: hvac blower1ms overrun frequency";
CM_ SG_ 656 VCLEFT_hvacBlower10msOverrunFreq "Left body controller: hvac blower10ms overrun frequency";
CM_ BO_ 657 "Left body controller message: thermal logging1 hz";
CM_ SG_ 657 VCLEFT_thermalLogging1HzIndex "Left body controller: thermal logging1 hz index";
CM_ SG_ 657 VCLEFT_hvac2RLeftLateralZeroStop "Left body controller: hvac2 r left lateral zero stop voltage";
CM_ SG_ 657 VCLEFT_hvac2RLeftVerticalZeroSto "Left body controller: hvac2 r left vertical zero stop voltage";
CM_ SG_ 657 VCLEFT_hvac2RRightLateralZeroSto "Left body controller: hvac2 r right lateral zero stop voltage";
CM_ SG_ 657 VCLEFT_hvac2RRightVerticalZeroSt "Left body controller: hvac2 r right vertical zero stop voltage";
CM_ SG_ 657 VCLEFT_hvac2RLeftLateralEndStopV "Left body controller: hvac2 r left lateral end stop voltage";
CM_ SG_ 657 VCLEFT_hvac2RLeftVerticalEndStop "Left body controller: hvac2 r left vertical end stop voltage";
CM_ SG_ 657 VCLEFT_hvac2RRightLateralEndStop "Left body controller: hvac2 r right lateral end stop voltage";
CM_ SG_ 657 VCLEFT_hvac2RRightVerticalEndSto "Left body controller: hvac2 r right vertical end stop voltage";
CM_ SG_ 657 VCLEFT_hvacBlowerArbCurrent "Left body controller: hvac blower arb current";
CM_ SG_ 657 VCLEFT_hvacBlowerTorqueIndexFilt "Left body controller: hvac blower torque index filtered";
CM_ BO_ 386 "Left body controller message: thermal status";
CM_ SG_ 386 VCLEFT_hvac2RLeftLateralStatus "Left body controller: hvac2 r left lateral status";
CM_ SG_ 386 VCLEFT_hvac2RLeftVerticalStatus "Left body controller: hvac2 r left vertical status";
CM_ SG_ 386 VCLEFT_hvac2RRightLateralStatus "Left body controller: hvac2 r right lateral status";
CM_ SG_ 386 VCLEFT_hvac2RRightVerticalStatus "Left body controller: hvac2 r right vertical status";
CM_ SG_ 386 VCLEFT_hvac2RLeftLateralPosition "Left body controller: hvac2 r left lateral position";
CM_ SG_ 386 VCLEFT_hvac2RLeftVerticalPositio "Left body controller: hvac2 r left vertical position";
CM_ SG_ 386 VCLEFT_hvac2RRightLateralPositio "Left body controller: hvac2 r right lateral position";
CM_ SG_ 386 VCLEFT_hvac2RRightVerticalPositi "Left body controller: hvac2 r right vertical position";
CM_ BO_ 1571 "Left body controller message: uds response";
CM_ SG_ 1571 VCLEFT_udsResponseData_H "Left body controller: uds response data h";
CM_ SG_ 1571 VCLEFT_udsResponseData_L "Left body controller: uds response data l";
CM_ BO_ 706 "Left body controller message: window status";
CM_ SG_ 706 VCLEFT_windowStatusIndex "Left body controller: window status index";
CM_ SG_ 706 VCLEFT_windowStateLF "Status of left front window motor";
CM_ SG_ 706 VCLEFT_windowTrimClearMoveReques "Requests whether windows should enter or exit trim clear. Signal only valid if Vehicle Controller Left (VCLEFT) is on driver side.";
CM_ SG_ 706 VCLEFT_windowDutyLF "Left body controller: window duty LF";
CM_ SG_ 706 VCLEFT_windowTrimClearActiveRequ "Reports whether window trim clear is active. Signal is only valid if Vehicle Controller Left (VCLEFT) is on driver side; raw 0 = signal not available (SNA)";
CM_ SG_ 706 VCLEFT_windowCurrentLF "Current drawn by left front window regulator";
CM_ SG_ 706 VCLEFT_windowPositionLF "Left body controller: window position LF; raw 1 = signal not available (SNA)";
CM_ SG_ 706 VCLEFT_windowCalibratedLF "Calibration status of left front window motor";
CM_ SG_ 706 VCLEFT_windowStateLR "Status of left rear window motor";
CM_ SG_ 706 VCLEFT_windowDutyLR "Left body controller: window duty LR";
CM_ SG_ 706 VCLEFT_windowCurrentLR "Current drawn by left rear window regulator";
CM_ SG_ 706 VCLEFT_windowPositionLR "Left body controller: window position LR";
CM_ SG_ 706 VCLEFT_windowCalibratedLR "Calibraiton status of left rear window motor";
CM_ SG_ 706 VCLEFT_windowThermalTCLF "Left body controller: window thermal TCLF";
CM_ SG_ 706 VCLEFT_windowThermalModeLF "Left body controller: window thermal mode LF; raw 0 = signal not available (SNA)";
CM_ SG_ 706 VCLEFT_windowStopReasonLF "Reason for left front window stopping motion";
CM_ SG_ 706 VCLEFT_windowStopReqReasonLF "Reason for left front window stopping motion";
CM_ SG_ 706 VCLEFT_windowThermalTCLR "Left body controller: window thermal TCLR";
CM_ SG_ 706 VCLEFT_windowThermalModeLR "Left body controller: window thermal mode LR; raw 0 = signal not available (SNA)";
CM_ SG_ 706 VCLEFT_windowStopReasonLR "Reason for left rear window stopping motion";
CM_ SG_ 706 VCLEFT_windowStopReqReasonLR "Reason for left rear window stopping motion";
CM_ SG_ 706 VCLEFT_windowControlStateLF "Window control state";
CM_ SG_ 706 VCLEFT_windowCtrlUnavailableLF "Window control unavailable reason";
CM_ SG_ 706 VCLEFT_windowControlStateLR "Window control state";
CM_ SG_ 706 VCLEFT_windowCtrlUnavailableLR "Window control unavailable reason";
CM_ SG_ 706 VCLEFT_windowPositionStateLF "Window position state";
CM_ SG_ 706 VCLEFT_windowPositionStateLR "Window position state";
CM_ SG_ 706 VCLEFT_windowVehGearStateLF "Window's interpretation of vehicle gear state; raw 0 = signal not available (SNA)";
CM_ SG_ 706 VCLEFT_windowVehGearStateLR "Window's interpretation of vehicle gear state; raw 0 = signal not available (SNA)";
CM_ SG_ 706 VCLEFT_windowSpeedTableStatusLF "Speed table build status of left front window; raw 0 = signal not available (SNA)";
CM_ SG_ 706 VCLEFT_windowSpeedTableStatusLR "Speed table build status of left rear window; raw 0 = signal not available (SNA)";
CM_ BO_ 1114 "Right body controller message: AP hvac state10 hz";
CM_ SG_ 1114 VCRIGHT_AP_hvacState10HzIndex "Right body controller: AP hvac state10 hz index";
CM_ SG_ 1114 VCRIGHT_AP_autoDefogAvailable "Right body controller: AP auto defog available";
CM_ SG_ 1114 VCRIGHT_AP_hvacFlashFoggingDetec "Right body controller: AP hvac flash fogging detected";
CM_ SG_ 1114 VCRIGHT_AP_hvacModelInitStatus "Right body controller: AP hvac model init status";
CM_ SG_ 1114 VCRIGHT_AP_cabinTempWindshield "Right body controller: AP cabin temp windshield; raw 255 = signal not available (SNA)";
CM_ SG_ 1114 VCRIGHT_AP_cabinTempSideGlassRig "Right body controller: AP cabin temp side glass right; raw 255 = signal not available (SNA)";
CM_ SG_ 1114 VCRIGHT_AP_cabinTempSideGlassLef "Right body controller: AP cabin temp side glass left; raw 255 = signal not available (SNA)";
CM_ SG_ 1114 VCRIGHT_AP_hvacRecircDoorPercent "Right body controller: AP hvac recirc door percent";
CM_ SG_ 1114 VCRIGHT_AP_hvacAirDistributionMo "Right body controller: AP hvac air distribution mode";
CM_ SG_ 1114 VCRIGHT_AP_hvacEstimateWindshiel "Right body controller: AP hvac estimate windshield RH";
CM_ SG_ 1114 VCRIGHT_AP_hvacMassflowTarget "Right body controller: AP hvac massflow target";
CM_ SG_ 1114 VCRIGHT_AP_tempDuctDefrost "Right body controller: AP temp duct defrost; raw 255 = signal not available (SNA)";
CM_ SG_ 1114 VCRIGHT_AP_cameraTurnOnTime "Reports the time duration requested to run the Autopilot (AP) cameras for defogging purposes; raw 511 = signal not available (SNA)";
CM_ SG_ 1114 VCRIGHT_AP_cameraDefogType "Right body controller: AP camera defog type";
CM_ SG_ 1114 VCRIGHT_ah_hvacFaultSurvivabilit "Right body controller: ah hvac fault survivability time; raw 31 = signal not available (SNA)";
CM_ SG_ 1114 VCRIGHT_ah_defoggingTimeNeeded "Right body controller: ah defogging time needed; raw 31 = signal not available (SNA)";
CM_ SG_ 1114 VCRIGHT_AP_cameraFanDutyRequest "Right body controller: AP camera fan duty request; raw 127 = signal not available (SNA)";
CM_ SG_ 1114 VCRIGHT_ah_defogSystemState "Right body controller: ah defog system state; raw 7 = signal not available (SNA)";
CM_ SG_ 1114 VCRIGHT_AP_turnForwardCameraHeat "Right body controller: AP turn forward camera heater on reason";
CM_ SG_ 1114 VCRIGHT_AP_turnCameraFanOffReaso "Reports the reason for requesting the triple camera fan to turn off.";
CM_ SG_ 1114 VCRIGHT_AP_forwardCameraIntegrat "Request to run forward camera heating.";
CM_ SG_ 1114 VCRIGHT_AP_solarFluxOnRightWindo "Right body controller: AP solar flux on right window; raw 255 = signal not available (SNA)";
CM_ SG_ 1114 VCRIGHT_AP_solarFluxOnLeftWindow "Right body controller: AP solar flux on left window; raw 255 = signal not available (SNA)";
CM_ BO_ 1124 "Right body controller message: AP hvac state1 hz";
CM_ SG_ 1124 VCRIGHT_AP_hvacState1HzIndex "Right body controller: AP hvac state1 hz index";
CM_ SG_ 1124 VCRIGHT_AP_tempCameraModele_0001 "Right body controller: AP temp camera modeled windshield out; raw 255 = signal not available (SNA)";
CM_ SG_ 1124 VCRIGHT_AP_tempCameraModeledWind "Right body controller: AP temp camera modeled windshield in; raw 255 = signal not available (SNA)";
CM_ SG_ 1124 VCRIGHT_AP_cameraModeledWin_0001 "Right body controller: AP camera modeled windshield out rh; raw 127 = signal not available (SNA)";
CM_ SG_ 1124 VCRIGHT_AP_cameraModeledWindshie "Right body controller: AP camera modeled windshield in rh; raw 127 = signal not available (SNA)";
CM_ SG_ 1124 VCRIGHT_AP_maxAchievableASideTem "Right body controller: AP max achievable a side temp camera pocket";
CM_ SG_ 1124 VCRIGHT_AP_cameraModeledPocketWa "Right body controller: AP camera modeled pocket water mass; raw 1023 = signal not available (SNA)";
CM_ SG_ 1124 VCRIGHT_AP_humidityModelInitStat "Right body controller: AP humidity model init status";
CM_ SG_ 1124 VCRIGHT_AP_humidityModelStatus "Right body controller: AP humidity model status";
CM_ BO_ 549 "Right body controller message: LV power state";
CM_ SG_ 549 VCRIGHT_ptcLVState "Right body controller: ptc LV state";
CM_ SG_ 549 VCRIGHT_ocsLVState "Right body controller: ocs LV state";
CM_ SG_ 549 VCRIGHT_premAudioLVState "Right body controller: prem audio LV state";
CM_ SG_ 549 VCRIGHT_rearOilPumpLVState "Right body controller: rear oil pump LV state";
CM_ SG_ 549 VCRIGHT_tunerLVState "Right body controller: tuner LV state";
CM_ SG_ 549 VCRIGHT_hvcLVState "Right body controller: hvc LV state";
CM_ SG_ 549 VCRIGHT_rcmLVState "Right body controller: rcm LV state";
CM_ SG_ 549 VCRIGHT_lumbarLVState "Right body controller: lumbar LV state";
CM_ SG_ 549 VCRIGHT_3RUSBPowered "State of power to the 3R USB Ports";
CM_ SG_ 549 VCRIGHT_cntctrPwrState "Right body controller: cntctr pwr state";
CM_ SG_ 549 VCRIGHT_eFuseLockoutStatus "Right body controller: e fuse lockout status";
CM_ SG_ 549 VCRIGHT_swEnStatus "Status of the internal switched power rail on the board";
CM_ SG_ 549 VCRIGHT_vehiclePowerStateDBG "Right body controller: vehicle power state DBG";
CM_ SG_ 549 VCRIGHT_parkLVState "Right body controller: park LV state";
CM_ SG_ 549 VCRIGHT_icrLVState "Right body controller: icr LV state";
CM_ SG_ 549 VCRIGHT_interiorCameraLedLVState "Right body controller: interior camera led LV state";
CM_ SG_ 549 VCRIGHT_diLVState "Right body controller: di LV state";
CM_ SG_ 549 VCRIGHT_accDevicesDetected "At least one accessory device detected on accessory ports";
CM_ BO_ 643 "Right body controller message: PTC request";
CM_ SG_ 643 VCRIGHT_PTCLeftTargetPowerHV "Right body controller: PTC left target power HV";
CM_ SG_ 643 VCRIGHT_PTCRightTargetPowerHV "Right body controller: PTC right target power HV";
CM_ SG_ 643 VCRIGHT_PTCLeftTargetDuty "Right body controller: PTC left target duty";
CM_ SG_ 643 VCRIGHT_PTCRightTargetDuty "Right body controller: PTC right target duty";
CM_ SG_ 643 VCRIGHT_PTCFlagAllowOperation "Right body controller: PTC flag allow operation";
CM_ SG_ 643 VCRIGHT_PTCRequestMode "Right body controller: PTC request mode";
CM_ SG_ 643 VCRIGHT_PTCResistanceCheckEnable "Right body controller: PTC resistance check enable";
CM_ SG_ 643 VCRIGHT_PTCReset "Right body controller: PTC reset";
CM_ SG_ 643 VCRIGHT_PTCLeftDirectDriveIGBTO "Right body controller: PTC left direct drive IGBTO";
CM_ SG_ 643 VCRIGHT_PTCLeftDirectDriveIGBTC "Right body controller: PTC left direct drive IGBTC";
CM_ SG_ 643 VCRIGHT_PTCLeftDirectDriveIGBTI "Right body controller: PTC left direct drive IGBTI";
CM_ SG_ 643 VCRIGHT_PTCRightDirectDriveIGBTI "Right body controller: PTC right direct drive IGBTI";
CM_ SG_ 643 VCRIGHT_PTCRightDirectDriveIGBTC "Right body controller: PTC right direct drive IGBTC";
CM_ SG_ 643 VCRIGHT_PTCRightDirectDriveIGBTO "Right body controller: PTC right direct drive IGBTO";
CM_ BO_ 2011 "Right body controller message: alert log";
CM_ SG_ 2011 VCRIGHT_alertID "Right body controller: alert ID";
CM_ SG_ 2011 VCRIGHT_alertState "Right body controller: alert state";
CM_ SG_ 2011 VCRIGHT_a001_InternalWatchdog "Right body controller: a001 internal watchdog";
CM_ SG_ 2011 VCRIGHT_a010_UnderVoltageDetecte "Right body controller: a010 under voltage detected";
CM_ SG_ 2011 VCRIGHT_a010_UnderVoltageTimeout "Right body controller: a010 under voltage timeout";
CM_ SG_ 2011 VCRIGHT_a015_NVMMMemOverflow "Right body controller: a015 NVMM mem overflow";
CM_ SG_ 2011 VCRIGHT_a015_NVMMFilesystemError "Right body controller: a015 NVMM filesystem error";
CM_ SG_ 2011 VCRIGHT_a015_NVMMRecordIDError "Right body controller: a015 NVMM record ID error";
CM_ SG_ 2011 VCRIGHT_a057_VEH_cpControl "Right body controller: a057 VEH cp control";
CM_ SG_ 2011 VCRIGHT_a059_voltageDrop "Right body controller: a059 voltage drop";
CM_ SG_ 2011 VCRIGHT_a059_resistanceEstimate "Right body controller: a059 resistance estimate";
CM_ SG_ 2011 VCRIGHT_a059_current "Right body controller: a059 current";
CM_ SG_ 2011 VCRIGHT_a063_switchChannel "Right body controller: a063 switch channel";
CM_ SG_ 2011 VCRIGHT_a063_switchType "Right body controller: a063 switch type";
CM_ SG_ 2011 VCRIGHT_a063_ADCVoltage "Right body controller: a063 ADC voltage";
CM_ SG_ 2011 VCRIGHT_a063_disconnected "Right body controller: a063 disconnected";
CM_ SG_ 2011 VCRIGHT_a063_indeterminate "Right body controller: a063 indeterminate";
CM_ SG_ 2011 VCRIGHT_a063_stuckActive "Right body controller: a063 stuck active";
CM_ SG_ 2011 VCRIGHT_a063_faulted "Right body controller: a063 faulted";
CM_ SG_ 2011 VCRIGHT_a082_RIPC_epbPrivateStat "Right body controller: a082 RIPC epb private state";
CM_ SG_ 2011 VCRIGHT_a082_RIPC_remoteHSD "Right body controller: a082 RIPC remote HSD";
CM_ SG_ 2011 VCRIGHT_a082_RIPC_railStatus "Right body controller: a082 RIPC rail status";
CM_ SG_ 2011 VCRIGHT_a082_RIPC_remoteMux "Right body controller: a082 RIPC remote mux";
CM_ SG_ 2011 VCRIGHT_a083_LIPC_epbPrivateStat "Right body controller: a083 LIPC epb private state";
CM_ SG_ 2011 VCRIGHT_a083_LIPC_remoteHSD "Right body controller: a083 LIPC remote HSD";
CM_ SG_ 2011 VCRIGHT_a083_LIPC_railStatus "Right body controller: a083 LIPC rail status";
CM_ SG_ 2011 VCRIGHT_a083_LIPC_HSDFaults "Right body controller: a083 LIPC HSD faults";
CM_ SG_ 2011 VCRIGHT_a084_CH_StatusC "Right body controller: a084 CH status c";
CM_ SG_ 2011 VCRIGHT_a085_PARTY_buttonStatus "Right body controller: a085 PARTY button status";
CM_ SG_ 2011 VCRIGHT_a086_VEH_LVBMS_statusHig "Right body controller: a086 VEH LVBMS status high";
CM_ SG_ 2011 VCRIGHT_a086_VEH_LVBMS_statusLow "Right body controller: a086 VEH LVBMS status low";
CM_ SG_ 2011 VCRIGHT_a086_VEH_status "Right body controller: a086 VEH status";
CM_ SG_ 2011 VCRIGHT_a086_VEH_12VBatteryStatu "Right body controller: a086 VEH 12 v battery status";
CM_ SG_ 2011 VCRIGHT_a086_VEH_LVPowerState "Right body controller: a086 VEH LV power state";
CM_ SG_ 2011 VCRIGHT_a086_VEH_lightStatus "Right body controller: a086 VEH light status";
CM_ SG_ 2011 VCRIGHT_a086_VEH_systemStatus "Right body controller: a086 VEH system status";
CM_ SG_ 2011 VCRIGHT_a086_VEH_thermalStatus "Right body controller: a086 VEH thermal status";
CM_ SG_ 2011 VCRIGHT_a086_VEH_vehNm "Right body controller: a086 VEH veh nm";
CM_ SG_ 2011 VCRIGHT_a086_BDY_LVSelfTests "Right body controller: a086 BDY LV self tests";
CM_ SG_ 2011 VCRIGHT_a086_VEH_LVSelfTests "Right body controller: a086 VEH LV self tests";
CM_ SG_ 2011 VCRIGHT_a086_VEH_LVHealth "Right body controller: a086 VEH LV health";
CM_ SG_ 2011 VCRIGHT_a086_BDY_12VBatteryStatu "Right body controller: a086 BDY 12 v battery status";
CM_ SG_ 2011 VCRIGHT_a087_VEH_temperature "Right body controller: a087 VEH temperature";
CM_ SG_ 2011 VCRIGHT_a087_VEH_thermalControl "Right body controller: a087 VEH thermal control";
CM_ SG_ 2011 VCRIGHT_a087_VEH_torque "Right body controller: a087 VEH torque";
CM_ SG_ 2011 VCRIGHT_a087_VEH_status "Right body controller: a087 VEH status";
CM_ SG_ 2011 VCRIGHT_a087_PARTY_torque "Right body controller: a087 PARTY torque";
CM_ SG_ 2011 VCRIGHT_a087_PARTY_status "Right body controller: a087 PARTY status";
CM_ SG_ 2011 VCRIGHT_a087_PARTY_temperature "Right body controller: a087 PARTY temperature";
CM_ SG_ 2011 VCRIGHT_a087_PARTY_thermalContro "Right body controller: a087 PARTY thermal control";
CM_ SG_ 2011 VCRIGHT_a087_VEH_motorStatus "Right body controller: a087 VEH motor status";
CM_ SG_ 2011 VCRIGHT_a088_VEH_temperature "Right body controller: a088 VEH temperature";
CM_ SG_ 2011 VCRIGHT_a088_VEH_thermalControl "Right body controller: a088 VEH thermal control";
CM_ SG_ 2011 VCRIGHT_a088_VEH_torque "Right body controller: a088 VEH torque";
CM_ SG_ 2011 VCRIGHT_a088_VEH_status "Right body controller: a088 VEH status";
CM_ SG_ 2011 VCRIGHT_a088_PARTY_torque "Right body controller: a088 PARTY torque";
CM_ SG_ 2011 VCRIGHT_a088_PARTY_status "Right body controller: a088 PARTY status";
CM_ SG_ 2011 VCRIGHT_a088_PARTY_temperature "Right body controller: a088 PARTY temperature";
CM_ SG_ 2011 VCRIGHT_a088_PARTY_thermalContro "Right body controller: a088 PARTY thermal control";
CM_ SG_ 2011 VCRIGHT_a088_VEH_motorStatus "Right body controller: a088 VEH motor status";
CM_ SG_ 2011 VCRIGHT_a089_PARTY_party1 "Right body controller: a089 PARTY party1";
CM_ SG_ 2011 VCRIGHT_a089_PARTY_status "Right body controller: a089 PARTY status";
CM_ SG_ 2011 VCRIGHT_a089_VEH_status "Right body controller: a089 VEH status";
CM_ SG_ 2011 VCRIGHT_a089_BDY_party1 "Right body controller: a089 BDY party1";
CM_ SG_ 2011 VCRIGHT_a089_BDY_status "Right body controller: a089 BDY status";
CM_ SG_ 2011 VCRIGHT_a089_CH_status "Right body controller: a089 CH status";
CM_ SG_ 2011 VCRIGHT_a089_CH_party1 "Right body controller: a089 CH party1";
CM_ SG_ 2011 VCRIGHT_a089_CH_party3 "Right body controller: a089 CH party3";
CM_ SG_ 2011 VCRIGHT_a089_VEH_party1 "Right body controller: a089 VEH party1";
CM_ SG_ 2011 VCRIGHT_a089_VEH_party3 "Right body controller: a089 VEH party3";
CM_ SG_ 2011 VCRIGHT_a091_VEH_faultsAndExtras "Right body controller: a091 VEH faults and extras";
CM_ SG_ 2011 VCRIGHT_a091_VEH_info "Right body controller: a091 VEH info";
CM_ SG_ 2011 VCRIGHT_a091_VEH_state "Right body controller: a091 VEH state";
CM_ SG_ 2011 VCRIGHT_a092_VEH_restraintStatus "Right body controller: a092 VEH restraint status";
CM_ SG_ 2011 VCRIGHT_a092_VEH_switchStatus "Right body controller: a092 VEH switch status";
CM_ SG_ 2011 VCRIGHT_a092_VEH_seatStatus2 "Right body controller: a092 VEH seat status2";
CM_ SG_ 2011 VCRIGHT_a092_VEH_vehNm "Right body controller: a092 VEH veh nm";
CM_ SG_ 2011 VCRIGHT_a093_VEH_restraintStatus "Right body controller: a093 VEH restraint status";
CM_ SG_ 2011 VCRIGHT_a093_VEH_switchStatus "Right body controller: a093 VEH switch status";
CM_ SG_ 2011 VCRIGHT_a093_VEH_seatStatus2 "Right body controller: a093 VEH seat status2";
CM_ SG_ 2011 VCRIGHT_a093_VEH_vehNm "Right body controller: a093 VEH veh nm";
CM_ SG_ 2011 VCRIGHT_a094_VEH_sysStatus "Right body controller: a094 VEH sys status";
CM_ SG_ 2011 VCRIGHT_a094_PARTY_sysStatus "Right body controller: a094 PARTY sys status";
CM_ SG_ 2011 VCRIGHT_a094_CH_sysStatus "Right body controller: a094 CH sys status";
CM_ SG_ 2011 VCRIGHT_a095_PT_ptNm "Right body controller: a095 PT pt nm";
CM_ SG_ 2011 VCRIGHT_a095_PT_status "Right body controller: a095 PT status";
CM_ SG_ 2011 VCRIGHT_a096_VEH_status "Right body controller: a096 VEH status";
CM_ SG_ 2011 VCRIGHT_a096_CH_status "Right body controller: a096 CH status";
CM_ SG_ 2011 VCRIGHT_a097_VEH_HVStatus "Right body controller: a097 VEH HV status";
CM_ SG_ 2011 VCRIGHT_a097_VEH_state "Right body controller: a097 VEH state";
CM_ SG_ 2011 VCRIGHT_a098_CH_torque "Right body controller: a098 CH torque";
CM_ SG_ 2011 VCRIGHT_a098_VEH_hvStatus "Right body controller: a098 VEH hv status";
CM_ SG_ 2011 VCRIGHT_a098_VEH_status "Right body controller: a098 VEH status";
CM_ SG_ 2011 VCRIGHT_a098_VEH_thermalControl "Right body controller: a098 VEH thermal control";
CM_ SG_ 2011 VCRIGHT_a098_VEH_temperature "Right body controller: a098 VEH temperature";
CM_ SG_ 2011 VCRIGHT_a098_VEH_torque "Right body controller: a098 VEH torque";
CM_ SG_ 2011 VCRIGHT_a098_PARTY_status "Right body controller: a098 PARTY status";
CM_ SG_ 2011 VCRIGHT_a098_PARTY_temperature "Right body controller: a098 PARTY temperature";
CM_ SG_ 2011 VCRIGHT_a098_PARTY_thermalContro "Right body controller: a098 PARTY thermal control";
CM_ SG_ 2011 VCRIGHT_a098_PARTY_torque "Right body controller: a098 PARTY torque";
CM_ SG_ 2011 VCRIGHT_a098_PT_thermalControl "Right body controller: a098 PT thermal control";
CM_ SG_ 2011 VCRIGHT_a098_PT_temperature "Right body controller: a098 PT temperature";
CM_ SG_ 2011 VCRIGHT_a098_PARTY_motorStatus "Right body controller: a098 PARTY motor status";
CM_ SG_ 2011 VCRIGHT_a098_VEH_motorStatus "Right body controller: a098 VEH motor status";
CM_ SG_ 2011 VCRIGHT_a099_VEH_oocStatus "Right body controller: a099 VEH ooc status";
CM_ SG_ 2011 VCRIGHT_a100_VEH "Right body controller: a100 VEH";
CM_ SG_ 2011 VCRIGHT_a100_PARTY "Right body controller: a100 PARTY";
CM_ SG_ 2011 VCRIGHT_a100_PT "Right body controller: a100 PT";
CM_ SG_ 2011 VCRIGHT_a100_CH "Right body controller: a100 CH";
CM_ SG_ 2011 VCRIGHT_a100_OBD "Right body controller: a100 OBD";
CM_ SG_ 2011 VCRIGHT_a101_VEH_state "Right body controller: a101 VEH state";
CM_ SG_ 2011 VCRIGHT_a101_PARTY_locState "Right body controller: a101 PARTY loc state";
CM_ SG_ 2011 VCRIGHT_a101_LIPC_externalWatchd "Right body controller: a101 LIPC external watchdog heart beat";
CM_ SG_ 2011 VCRIGHT_a101_VEH_locState "Right body controller: a101 VEH loc state";
CM_ SG_ 2011 VCRIGHT_a101_BDY_locState "Right body controller: a101 BDY loc state";
CM_ SG_ 2011 VCRIGHT_a102_VEH_faultsAndExtras "Right body controller: a102 VEH faults and extras";
CM_ SG_ 2011 VCRIGHT_a102_VEH_feedbackStatus "Right body controller: a102 VEH feedback status";
CM_ SG_ 2011 VCRIGHT_a102_VEH_sensorStatus "Right body controller: a102 VEH sensor status";
CM_ SG_ 2011 VCRIGHT_a102_VEH_rods "Right body controller: a102 VEH rods";
CM_ SG_ 2011 VCRIGHT_a103_VEH_hvsNm "Right body controller: a103 VEH hvs nm";
CM_ SG_ 2011 VCRIGHT_a103_VEH_vehNm "Right body controller: a103 VEH veh nm";
CM_ SG_ 2011 VCRIGHT_a103_VEH_status "Right body controller: a103 VEH status";
CM_ SG_ 2011 VCRIGHT_a103_PT_ptNm "Right body controller: a103 PT pt nm";
CM_ SG_ 2011 VCRIGHT_a103_PT_status "Right body controller: a103 PT status";
CM_ SG_ 2011 VCRIGHT_a103_VEH_evseStatus "Right body controller: a103 VEH evse status";
CM_ SG_ 2011 VCRIGHT_a105_VEH_states "Right body controller: a105 VEH states";
CM_ SG_ 2011 VCRIGHT_a105_VEH_chNm "Right body controller: a105 VEH ch nm";
CM_ SG_ 2011 VCRIGHT_a105_VEH_dampingStates "Right body controller: a105 VEH damping states";
CM_ SG_ 2011 VCRIGHT_a106_VEH_dcdcStatus "Right body controller: a106 VEH dcdc status";
CM_ SG_ 2011 VCRIGHT_a106_VEH_thermalControl "Right body controller: a106 VEH thermal control";
CM_ SG_ 2011 VCRIGHT_a106_VEH_dcdcRailStatus "Right body controller: a106 VEH dcdc rail status";
CM_ SG_ 2011 VCRIGHT_a106_CH_dcdcRailStatus "Right body controller: a106 CH dcdc rail status";
CM_ SG_ 2011 VCRIGHT_a106_CH_alertMatrix "Right body controller: a106 CH alert matrix";
CM_ SG_ 2011 VCRIGHT_a107_VEH_hvsNm "Right body controller: a107 VEH hvs nm";
CM_ SG_ 2011 VCRIGHT_a107_VEH_vehNm "Right body controller: a107 VEH veh nm";
CM_ SG_ 2011 VCRIGHT_a107_VEH_status "Right body controller: a107 VEH status";
CM_ SG_ 2011 VCRIGHT_a107_VEH_thermalStatus "Right body controller: a107 VEH thermal status";
CM_ SG_ 2011 VCRIGHT_a107_VEH_bmbMinMax "Right body controller: a107 VEH bmb min max";
CM_ SG_ 2011 VCRIGHT_a107_VEH_powerAvailable "Right body controller: a107 VEH power available";
CM_ SG_ 2011 VCRIGHT_a107_PT_ptNm "Right body controller: a107 PT pt nm";
CM_ SG_ 2011 VCRIGHT_a107_PT_status "Right body controller: a107 PT status";
CM_ SG_ 2011 VCRIGHT_a107_PT_thermalStatus "Right body controller: a107 PT thermal status";
CM_ SG_ 2011 VCRIGHT_a107_PT_socStatus "Right body controller: a107 PT soc status";
CM_ SG_ 2011 VCRIGHT_a107_VEH_socStatus "Right body controller: a107 VEH soc status";
CM_ SG_ 2011 VCRIGHT_a107_VEH_packConfig "Right body controller: a107 VEH pack config";
CM_ SG_ 2011 VCRIGHT_a107_VEH_energyStatus "Right body controller: a107 VEH energy status";
CM_ SG_ 2011 VCRIGHT_a107_VEH_chargeInfo "Right body controller: a107 VEH charge info";
CM_ SG_ 2011 VCRIGHT_a108_VEH_hvStatus "Right body controller: a108 VEH hv status";
CM_ SG_ 2011 VCRIGHT_a108_VEH_temperature "Right body controller: a108 VEH temperature";
CM_ SG_ 2011 VCRIGHT_a108_VEH_thermalControl "Right body controller: a108 VEH thermal control";
CM_ SG_ 2011 VCRIGHT_a108_VEH_torque "Right body controller: a108 VEH torque";
CM_ SG_ 2011 VCRIGHT_a108_VEH_status "Right body controller: a108 VEH status";
CM_ SG_ 2011 VCRIGHT_a108_PARTY_torque "Right body controller: a108 PARTY torque";
CM_ SG_ 2011 VCRIGHT_a108_PARTY_status "Right body controller: a108 PARTY status";
CM_ SG_ 2011 VCRIGHT_a108_PARTY_temperature "Right body controller: a108 PARTY temperature";
CM_ SG_ 2011 VCRIGHT_a108_PARTY_thermalContro "Right body controller: a108 PARTY thermal control";
CM_ SG_ 2011 VCRIGHT_a108_PT_temperature "Right body controller: a108 PT temperature";
CM_ SG_ 2011 VCRIGHT_a108_PT_thermalControl "Right body controller: a108 PT thermal control";
CM_ SG_ 2011 VCRIGHT_a108_PARTY_motorStatus "Right body controller: a108 PARTY motor status";
CM_ SG_ 2011 VCRIGHT_a108_VEH_motorStatus "Right body controller: a108 VEH motor status";
CM_ SG_ 2011 VCRIGHT_a108_CH_torque "Right body controller: a108 CH torque";
CM_ SG_ 2011 VCRIGHT_a110_VEH_carState "Right body controller: a110 VEH car state";
CM_ SG_ 2011 VCRIGHT_a110_VEH_carConfig "Right body controller: a110 VEH car config";
CM_ SG_ 2011 VCRIGHT_a110_VEH_time "Right body controller: a110 VEH time";
CM_ SG_ 2011 VCRIGHT_a110_VEH_updateStatus "Right body controller: a110 VEH update status";
CM_ SG_ 2011 VCRIGHT_a110_VEH_vehNm "Right body controller: a110 VEH veh nm";
CM_ SG_ 2011 VCRIGHT_a110_VEH_mismatchFault "Right body controller: a110 VEH mismatch fault";
CM_ SG_ 2011 VCRIGHT_a110_VEH_vin "Right body controller: a110 VEH vin";
CM_ SG_ 2011 VCRIGHT_a110_VEH_bmpDebug "Right body controller: a110 VEH bmp debug";
CM_ SG_ 2011 VCRIGHT_a110_VEH_gearControl "Right body controller: a110 VEH gear control";
CM_ SG_ 2011 VCRIGHT_a110_VEH_canLogAvailabil "Right body controller: a110 VEH can log availability";
CM_ SG_ 2011 VCRIGHT_a110_CH_airbagCutoffStat "Right body controller: a110 CH airbag cutoff status";
CM_ SG_ 2011 VCRIGHT_a110_CH_carConfig "Right body controller: a110 CH car config";
CM_ SG_ 2011 VCRIGHT_a110_CH_carState "Right body controller: a110 CH car state";
CM_ SG_ 2011 VCRIGHT_a110_CH_vin "Right body controller: a110 CH vin";
CM_ SG_ 2011 VCRIGHT_a110_CH_chNm "Right body controller: a110 CH ch nm";
CM_ SG_ 2011 VCRIGHT_a110_CH_epochTimeGtw "Right body controller: a110 CH epoch time gtw";
CM_ SG_ 2011 VCRIGHT_a110_PARTY_carConfig "Right body controller: a110 PARTY car config";
CM_ SG_ 2011 VCRIGHT_a111_VEH_internalStatus "Right body controller: a111 VEH internal status";
CM_ SG_ 2011 VCRIGHT_a111_VEH_status "Right body controller: a111 VEH status";
CM_ SG_ 2011 VCRIGHT_a111_VEH_vehNm "Right body controller: a111 VEH veh nm";
CM_ SG_ 2011 VCRIGHT_a111_RIPC_LVPowerState "Right body controller: a111 RIPC LV power state";
CM_ SG_ 2011 VCRIGHT_a111_RIPC_epbPrivateStat "Right body controller: a111 RIPC epb private state";
CM_ SG_ 2011 VCRIGHT_a111_RIPC_railStatus "Right body controller: a111 RIPC rail status";
CM_ SG_ 2011 VCRIGHT_a111_RIPC_remoteADC "Right body controller: a111 RIPC remote ADC";
CM_ SG_ 2011 VCRIGHT_a111_RIPC_switchStatus "Right body controller: a111 RIPC switch status";
CM_ SG_ 2011 VCRIGHT_a111_VEH_LVPowerState "Right body controller: a111 VEH LV power state";
CM_ SG_ 2011 VCRIGHT_a111_VEH_seatStatus "Right body controller: a111 VEH seat status";
CM_ SG_ 2011 VCRIGHT_a111_PARTY_status "Right body controller: a111 PARTY status";
CM_ SG_ 2011 VCRIGHT_a111_CH_status "Right body controller: a111 CH status";
CM_ SG_ 2011 VCRIGHT_a112_VEH_internalStatus "Right body controller: a112 VEH internal status";
CM_ SG_ 2011 VCRIGHT_a112_VEH_status "Right body controller: a112 VEH status";
CM_ SG_ 2011 VCRIGHT_a112_VEH_vehNm "Right body controller: a112 VEH veh nm";
CM_ SG_ 2011 VCRIGHT_a112_LIPC_LVPowerState "Right body controller: a112 LIPC LV power state";
CM_ SG_ 2011 VCRIGHT_a112_LIPC_epbPrivateStat "Right body controller: a112 LIPC epb private state";
CM_ SG_ 2011 VCRIGHT_a112_LIPC_railStatus "Right body controller: a112 LIPC rail status";
CM_ SG_ 2011 VCRIGHT_a112_LIPC_remoteADC "Right body controller: a112 LIPC remote ADC";
CM_ SG_ 2011 VCRIGHT_a112_LIPC_switchStatus "Right body controller: a112 LIPC switch status";
CM_ SG_ 2011 VCRIGHT_a112_VEH_LVPowerState "Right body controller: a112 VEH LV power state";
CM_ SG_ 2011 VCRIGHT_a112_PARTY_status "Right body controller: a112 PARTY status";
CM_ SG_ 2011 VCRIGHT_a112_CH_status "Right body controller: a112 CH status";
CM_ SG_ 2011 VCRIGHT_a114_PARTY_status "Right body controller: a114 PARTY status";
CM_ SG_ 2011 VCRIGHT_a114_PARTY_wheelSpeeds "Right body controller: a114 PARTY wheel speeds";
CM_ SG_ 2011 VCRIGHT_a114_VEH_wheelSpeeds "Right body controller: a114 VEH wheel speeds";
CM_ SG_ 2011 VCRIGHT_a114_CH_wheelSpeeds "Right body controller: a114 CH wheel speeds";
CM_ SG_ 2011 VCRIGHT_a114_PARTY_party3 "Right body controller: a114 PARTY party3";
CM_ SG_ 2011 VCRIGHT_a114_VEH_party3 "Right body controller: a114 VEH party3";
CM_ SG_ 2011 VCRIGHT_a114_VEH_status "Right body controller: a114 VEH status";
CM_ SG_ 2011 VCRIGHT_a114_PARTY_wheelRotation "Right body controller: a114 PARTY wheel rotation";
CM_ SG_ 2011 VCRIGHT_a114_CH_wheelRotation "Right body controller: a114 CH wheel rotation";
CM_ SG_ 2011 VCRIGHT_a114_VEH_wheelRotation "Right body controller: a114 VEH wheel rotation";
CM_ SG_ 2011 VCRIGHT_a114_PARTY_brakeTorque "Right body controller: a114 PARTY brake torque";
CM_ SG_ 2011 VCRIGHT_a114_PARTY_offsets "Right body controller: a114 PARTY offsets";
CM_ SG_ 2011 VCRIGHT_a114_BDY_offsets "Right body controller: a114 BDY offsets";
CM_ SG_ 2011 VCRIGHT_a114_BDY_party3 "Right body controller: a114 BDY party3";
CM_ SG_ 2011 VCRIGHT_a114_BDY_status "Right body controller: a114 BDY status";
CM_ SG_ 2011 VCRIGHT_a114_BDY_wheelRotation "Right body controller: a114 BDY wheel rotation";
CM_ SG_ 2011 VCRIGHT_a114_BDY_wheelSpeeds "Right body controller: a114 BDY wheel speeds";
CM_ SG_ 2011 VCRIGHT_a114_CH_party1 "Right body controller: a114 CH party1";
CM_ SG_ 2011 VCRIGHT_a114_CH_party3 "Right body controller: a114 CH party3";
CM_ SG_ 2011 VCRIGHT_a114_CH_status "Right body controller: a114 CH status";
CM_ SG_ 2011 VCRIGHT_a115_VEH_vehNm "Right body controller: a115 VEH veh nm";
CM_ SG_ 2011 VCRIGHT_a115_VEH_authentication "Right body controller: a115 VEH authentication";
CM_ SG_ 2011 VCRIGHT_a115_VEH_BLEResetRequest "Right body controller: a115 VEH BLE reset request";
CM_ SG_ 2011 VCRIGHT_a115_VEH_requests "Right body controller: a115 VEH requests";
CM_ SG_ 2011 VCRIGHT_a115_VEH_requests2 "Right body controller: a115 VEH requests2";
CM_ SG_ 2011 VCRIGHT_a115_REM_authentication "Right body controller: a115 REM authentication";
CM_ SG_ 2011 VCRIGHT_a115_UI_corianderVehicle "Right body controller: a115 UI coriander vehicle control";
CM_ SG_ 2011 VCRIGHT_a115_CH_TPMSDisplay "Right body controller: a115 CH TPMS display";
CM_ SG_ 2011 VCRIGHT_a115_VEH_RSSI "Right body controller: a115 VEH RSSI";
CM_ SG_ 2011 VCRIGHT_a115_VEH_authenticationW "Right body controller: a115 VEH authentication with mac";
CM_ SG_ 2011 VCRIGHT_a115_VEH_endpointTemp "Right body controller: a115 VEH endpoint temp";
CM_ SG_ 2011 VCRIGHT_a115_VEH_ChildSeatStatus "Right body controller: a115 VEH child seat status";
CM_ SG_ 2011 VCRIGHT_a115_BDY_ChildSeatStatus "Right body controller: a115 BDY child seat status";
CM_ SG_ 2011 VCRIGHT_a115_BDY_endpointTemp "Right body controller: a115 BDY endpoint temp";
CM_ SG_ 2011 VCRIGHT_a115_BDY_BLEResetRequest "Right body controller: a115 BDY BLE reset request";
CM_ SG_ 2011 VCRIGHT_a115_BDY_RSSI "Right body controller: a115 BDY RSSI";
CM_ SG_ 2011 VCRIGHT_a115_BDY_authentication "Right body controller: a115 BDY authentication";
CM_ SG_ 2011 VCRIGHT_a115_BDY_requests "Right body controller: a115 BDY requests";
CM_ SG_ 2011 VCRIGHT_a115_BDY_requests2 "Right body controller: a115 BDY requests2";
BA_DEF_ BO_ "GenMsgCycleTime" INT 0 3600000;
BA_DEF_ BO_ "GenMsgSendType" ENUM "Cyclic","NotUsed","NotUsed","NotUsed","NotUsed","NotUsed","NotUsed","IfActive","NoMsgSendType","NotUsed";
BA_DEF_ BO_ "VFrameFormat" ENUM "StandardCAN","ExtendedCAN","reserved","J1939PG","reserved","reserved","reserved","reserved","reserved","reserved","reserved","reserved","reserved","reserved","StandardCAN_FD","ExtendedCAN_FD";
BA_DEF_ BO_ "CANFD_BRS" ENUM "0","1";
BA_DEF_ SG_ "GenSigSNA" STRING;
BA_DEF_ SG_ "SystemSignalLongSymbol" STRING;
BA_DEF_ SG_ "Confidence" ENUM "validated","plausible","layout-only","contradicted";
BA_DEF_DEF_ "GenMsgCycleTime" 0;
BA_DEF_DEF_ "GenMsgSendType" "NoMsgSendType";
BA_DEF_DEF_ "VFrameFormat" "StandardCAN";
BA_DEF_DEF_ "CANFD_BRS" "1";
BA_DEF_DEF_ "GenSigSNA" "";
BA_DEF_DEF_ "SystemSignalLongSymbol" "";
BA_DEF_DEF_ "Confidence" "layout-only";
BA_ "GenMsgCycleTime" BO_ 727 1000;
BA_ "GenMsgSendType" BO_ 727 0;
BA_ "GenMsgCycleTime" BO_ 1860 1000;
BA_ "GenMsgSendType" BO_ 1860 0;
BA_ "GenMsgCycleTime" BO_ 1863 50;
BA_ "GenMsgSendType" BO_ 1863 0;
BA_ "GenMsgCycleTime" BO_ 1250 100;
BA_ "GenMsgSendType" BO_ 1250 0;
BA_ "GenMsgCycleTime" BO_ 738 200;
BA_ "GenMsgSendType" BO_ 738 0;
BA_ "GenMsgCycleTime" BO_ 930 33;
BA_ "GenMsgSendType" BO_ 930 0;
BA_ "GenMsgCycleTime" BO_ 610 1000;
BA_ "GenMsgSendType" BO_ 610 0;
BA_ "GenMsgCycleTime" BO_ 962 50;
BA_ "GenMsgSendType" BO_ 962 0;
BA_ "GenMsgCycleTime" BO_ 656 20;
BA_ "GenMsgSendType" BO_ 656 0;
BA_ "GenMsgCycleTime" BO_ 657 500;
BA_ "GenMsgSendType" BO_ 657 0;
BA_ "GenMsgCycleTime" BO_ 386 100;
BA_ "GenMsgSendType" BO_ 386 0;
BA_ "GenMsgCycleTime" BO_ 706 100;
BA_ "GenMsgSendType" BO_ 706 0;
BA_ "GenMsgCycleTime" BO_ 1114 50;
BA_ "GenMsgSendType" BO_ 1114 0;
BA_ "GenMsgCycleTime" BO_ 1124 1000;
BA_ "GenMsgSendType" BO_ 1124 0;
BA_ "GenMsgCycleTime" BO_ 549 100;
BA_ "GenMsgSendType" BO_ 549 0;
BA_ "GenMsgCycleTime" BO_ 643 100;
BA_ "GenMsgSendType" BO_ 643 0;
BA_ "Confidence" SG_ 727 VCLEFT_pitchEstimateFusionState 0;
BA_ "Confidence" SG_ 727 VCLEFT_pitchEstimateStateTransit 0;
BA_ "SystemSignalLongSymbol" SG_ 727 VCLEFT_pitchEstimateStateTransit "VCLEFT_pitchEstimateStateTransitionID";
BA_ "Confidence" SG_ 727 VCLEFT_pitchEstimateArbitratedSt 0;
BA_ "SystemSignalLongSymbol" SG_ 727 VCLEFT_pitchEstimateArbitratedSt "VCLEFT_pitchEstimateArbitratedState";
BA_ "Confidence" SG_ 727 VCLEFT_pitchEstimateOKForAiming 0;
BA_ "Confidence" SG_ 727 VCLEFT_pitchEstimateFusionRaw 0;
BA_ "Confidence" SG_ 727 VCLEFT_pitchEstimate 0;
BA_ "GenSigSNA" SG_ 727 VCLEFT_pitchEstimate "512";
BA_ "Confidence" SG_ 1860 VCLEFT_systemRecallStatus 0;
BA_ "GenSigSNA" SG_ 1860 VCLEFT_systemRecallStatus "0";
BA_ "Confidence" SG_ 1860 VCLEFT_seatRecallStatus 0;
BA_ "GenSigSNA" SG_ 1860 VCLEFT_seatRecallStatus "0";
BA_ "Confidence" SG_ 1860 VCLEFT_columnRecallStatus 0;
BA_ "GenSigSNA" SG_ 1860 VCLEFT_columnRecallStatus "0";
BA_ "Confidence" SG_ 1860 VCLEFT_mirrorRecallStatus 0;
BA_ "GenSigSNA" SG_ 1860 VCLEFT_mirrorRecallStatus "0";
BA_ "Confidence" SG_ 1863 VCLEFT_frontOccupancyStatus 1;
BA_ "GenSigSNA" SG_ 1863 VCLEFT_frontOccupancyStatus "7";
BA_ "Confidence" SG_ 1863 VCLEFT_frontBuckleStatus 1;
BA_ "Confidence" SG_ 1863 VCLEFT_rearLeftOccupancyStatus 1;
BA_ "Confidence" SG_ 1863 VCLEFT_rearCenterOccupancyStatus 1;
BA_ "Confidence" SG_ 1863 VCLEFT_rearRightOccupancyStatus 1;
BA_ "Confidence" SG_ 1863 VCLEFT_rearLeftBuckleStatus 1;
BA_ "Confidence" SG_ 1863 VCLEFT_rearCenterBuckleStatus 1;
BA_ "Confidence" SG_ 1863 VCLEFT_seatTrackPosition 1;
BA_ "GenSigSNA" SG_ 1863 VCLEFT_seatTrackPosition "7";
BA_ "Confidence" SG_ 1863 VCLEFT_3RowLeftABStatus 1;
BA_ "GenSigSNA" SG_ 1863 VCLEFT_3RowLeftABStatus "2";
BA_ "Confidence" SG_ 1863 VCLEFT_3RowLeftBuckleStatus 1;
BA_ "Confidence" SG_ 1250 VCLEFT_seatStatusIndex 0;
BA_ "Confidence" SG_ 1250 VC_AH_1RowLeftSeatMovementHealth 0;
BA_ "Confidence" SG_ 1250 VCLEFT_frontSeatTrackPos 0;
BA_ "Confidence" SG_ 1250 VCLEFT_frontSeatTrackCurrent 0;
BA_ "Confidence" SG_ 1250 VCLEFT_frontSeatTrackDuty 0;
BA_ "Confidence" SG_ 1250 VCLEFT_frontSeatTrackState 0;
BA_ "Confidence" SG_ 1250 VCLEFT_frontSeatTrackCalibrated 0;
BA_ "Confidence" SG_ 1250 VCLEFT_frontSeatTrackLog 0;
BA_ "Confidence" SG_ 1250 VCLEFT_frontSeatTrackBridgeSt 0;
BA_ "Confidence" SG_ 1250 VCLEFT_frontSeatTrackPercentage 0;
BA_ "Confidence" SG_ 1250 VCLEFT_frontSeatBackPos 0;
BA_ "Confidence" SG_ 1250 VCLEFT_frontSeatBackCurrent 0;
BA_ "Confidence" SG_ 1250 VCLEFT_frontSeatBackDuty 0;
BA_ "Confidence" SG_ 1250 VCLEFT_frontSeatBackState 0;
BA_ "Confidence" SG_ 1250 VCLEFT_frontSeatBackCalibrated 0;
BA_ "Confidence" SG_ 1250 VCLEFT_frontSeatBackLog 0;
BA_ "Confidence" SG_ 1250 VCLEFT_frontSeatBackBridgeSt 0;
BA_ "Confidence" SG_ 1250 VCLEFT_frontSeatBackPercentage 0;
BA_ "Confidence" SG_ 1250 VCLEFT_frontSeatLiftPos 0;
BA_ "Confidence" SG_ 1250 VCLEFT_frontSeatLiftCurrent 0;
BA_ "Confidence" SG_ 1250 VCLEFT_frontSeatLiftDuty 0;
BA_ "Confidence" SG_ 1250 VCLEFT_frontSeatLiftState 0;
BA_ "Confidence" SG_ 1250 VCLEFT_frontSeatLiftCalibrated 0;
BA_ "Confidence" SG_ 1250 VCLEFT_frontSeatLiftLog 0;
BA_ "Confidence" SG_ 1250 VCLEFT_frontSeatLiftBridgeSt 0;
BA_ "Confidence" SG_ 1250 VCLEFT_frontSeatLiftPercentage 0;
BA_ "Confidence" SG_ 1250 VCLEFT_frontSeatTiltPos 0;
BA_ "Confidence" SG_ 1250 VCLEFT_frontSeatTiltCurrent 0;
BA_ "Confidence" SG_ 1250 VCLEFT_frontSeatTiltDuty 0;
BA_ "Confidence" SG_ 1250 VCLEFT_frontSeatTiltState 0;
BA_ "Confidence" SG_ 1250 VCLEFT_frontSeatTiltCalibrated 0;
BA_ "Confidence" SG_ 1250 VCLEFT_frontSeatTiltLog 0;
BA_ "Confidence" SG_ 1250 VCLEFT_frontSeatTiltBridgeSt 0;
BA_ "Confidence" SG_ 1250 VCLEFT_frontSeatTiltPercentage 0;
BA_ "Confidence" SG_ 1250 VCLEFT_lumbarAState 0;
BA_ "Confidence" SG_ 1250 VCLEFT_lumbarBState 0;
BA_ "Confidence" SG_ 1250 VCLEFT_lumbarAPressureHpa 0;
BA_ "Confidence" SG_ 1250 VCLEFT_lumbarAPressureHpaFilt 0;
BA_ "Confidence" SG_ 1250 VCLEFT_lumbarBPressureHpa 0;
BA_ "Confidence" SG_ 1250 VCLEFT_lumbarBPressureHpaFilt 0;
BA_ "Confidence" SG_ 1250 VCLEFT_lumbarActiveTooLongErr 0;
BA_ "Confidence" SG_ 1250 VCLEFT_lumbarMaxPErr 0;
BA_ "Confidence" SG_ 1250 VCLEFT_lumbarOvercurrentErr 0;
BA_ "Confidence" SG_ 1250 VCLEFT_lumbarMaxOperatingPErr 0;
BA_ "Confidence" SG_ 1250 VCLEFT_lumbarMinPErr 0;
BA_ "Confidence" SG_ 1250 VCLEFT_lumbarGeneralErr 0;
BA_ "Confidence" SG_ 1250 VCLEFT_lumbarDevMaxPumpPressA 0;
BA_ "Confidence" SG_ 1250 VCLEFT_lumbarDevMaxPumpPressB 0;
BA_ "Confidence" SG_ 1250 VCLEFT_frontSeatTrackPosReal 0;
BA_ "Confidence" SG_ 1250 VCLEFT_frontSeatBackPosReal 0;
BA_ "Confidence" SG_ 1250 VCLEFT_frontSeatLiftPosReal 0;
BA_ "Confidence" SG_ 1250 VCLEFT_frontSeatTiltPosReal 0;
BA_ "Confidence" SG_ 1250 VCLEFT_frontSeatThighSupportPosR 0;
BA_ "SystemSignalLongSymbol" SG_ 1250 VCLEFT_frontSeatThighSupportPosR "VCLEFT_frontSeatThighSupportPosReal";
BA_ "Confidence" SG_ 1250 VCLEFT_frontSeatTrackPosOffset 0;
BA_ "Confidence" SG_ 1250 VCLEFT_frontSeatBackPosOffset 0;
BA_ "Confidence" SG_ 1250 VCLEFT_frontSeatLiftPosOffset 0;
BA_ "Confidence" SG_ 1250 VCLEFT_frontSeatTiltPosOffset 0;
BA_ "Confidence" SG_ 1250 VCLEFT_frontSeatThighSupportPosO 0;
BA_ "SystemSignalLongSymbol" SG_ 1250 VCLEFT_frontSeatThighSupportPosO "VCLEFT_frontSeatThighSupportPosOffset";
BA_ "Confidence" SG_ 1250 VCLEFT_lumbarAPressurePercentage 0;
BA_ "Confidence" SG_ 1250 VCLEFT_lumbarBPressurePercentage 0;
BA_ "Confidence" SG_ 738 VCLEFT_seatStatus2Index 0;
BA_ "Confidence" SG_ 738 VCLEFT_frontSeatHeatCurrent 0;
BA_ "GenSigSNA" SG_ 738 VCLEFT_frontSeatHeatCurrent "12";
BA_ "Confidence" SG_ 738 VCLEFT_frontSeatHeatDuty 0;
BA_ "Confidence" SG_ 738 VCLEFT_frontSeatHeatTmp 0;
BA_ "Confidence" SG_ 738 VCLEFT_frontSeatHeatTmpTarget 0;
BA_ "Confidence" SG_ 738 VCLEFT_frontSeatHeatInhibited 0;
BA_ "Confidence" SG_ 738 VCLEFT_frontSeatHeatPowered 0;
BA_ "Confidence" SG_ 738 VCLEFT_2RowSeatFoldLeftSwitch 0;
BA_ "GenSigSNA" SG_ 738 VCLEFT_2RowSeatFoldLeftSwitch "0";
BA_ "Confidence" SG_ 738 VCLEFT_2RowSeatUnfoldLeftSwitch 0;
BA_ "GenSigSNA" SG_ 738 VCLEFT_2RowSeatUnfoldLeftSwitch "0";
BA_ "Confidence" SG_ 738 VCLEFT_2RowSeatFoldRightSwitch 0;
BA_ "GenSigSNA" SG_ 738 VCLEFT_2RowSeatFoldRightSwitch "0";
BA_ "Confidence" SG_ 738 VCLEFT_2RowSeatUnfoldRightSwitch 0;
BA_ "GenSigSNA" SG_ 738 VCLEFT_2RowSeatUnfoldRightSwitch "0";
BA_ "Confidence" SG_ 738 VCLEFT_3RowSeatFoldLeftSwitch 0;
BA_ "GenSigSNA" SG_ 738 VCLEFT_3RowSeatFoldLeftSwitch "0";
BA_ "Confidence" SG_ 738 VCLEFT_3RowSeatUnfoldLeftSwitch 0;
BA_ "GenSigSNA" SG_ 738 VCLEFT_3RowSeatUnfoldLeftSwitch "0";
BA_ "Confidence" SG_ 738 VCLEFT_3RowSeatFoldRightSwitch 0;
BA_ "GenSigSNA" SG_ 738 VCLEFT_3RowSeatFoldRightSwitch "0";
BA_ "Confidence" SG_ 738 VCLEFT_3RowSeatUnfoldRightSwitch 0;
BA_ "GenSigSNA" SG_ 738 VCLEFT_3RowSeatUnfoldRightSwitch "0";
BA_ "Confidence" SG_ 738 VC_AH_1RowLeftSeatHeatVentHealth 0;
BA_ "Confidence" SG_ 738 VCLEFT_2RowSeatReclineState 0;
BA_ "GenSigSNA" SG_ 738 VCLEFT_2RowSeatReclineState "15";
BA_ "Confidence" SG_ 738 VCLEFT_2RowSeatReclineDuty 0;
BA_ "Confidence" SG_ 738 VCLEFT_2RowSeatReclineCurrent 0;
BA_ "Confidence" SG_ 738 VCLEFT_2RowSeatReclineCalibrated 0;
BA_ "Confidence" SG_ 738 VCLEFT_2RowSeatReclinePositionRa 0;
BA_ "SystemSignalLongSymbol" SG_ 738 VCLEFT_2RowSeatReclinePositionRa "VCLEFT_2RowSeatReclinePositionRaw";
BA_ "Confidence" SG_ 738 VCLEFT_2RowSeatReclineAngle 0;
BA_ "Confidence" SG_ 738 VCLEFT_2RowSeatReclineAbsPosSwit 0;
BA_ "GenSigSNA" SG_ 738 VCLEFT_2RowSeatReclineAbsPosSwit "0";
BA_ "SystemSignalLongSymbol" SG_ 738 VCLEFT_2RowSeatReclineAbsPosSwit "VCLEFT_2RowSeatReclineAbsPosSwitchState";
BA_ "Confidence" SG_ 738 VCLEFT_2RowSeatReclinePositionSt 0;
BA_ "GenSigSNA" SG_ 738 VCLEFT_2RowSeatReclinePositionSt "4";
BA_ "SystemSignalLongSymbol" SG_ 738 VCLEFT_2RowSeatReclinePositionSt "VCLEFT_2RowSeatReclinePositionState";
BA_ "Confidence" SG_ 738 VCLEFT_2RowSeatReclineAdjustment 0;
BA_ "SystemSignalLongSymbol" SG_ 738 VCLEFT_2RowSeatReclineAdjustment "VCLEFT_2RowSeatReclineAdjustmentAllowed";
BA_ "Confidence" SG_ 738 VCLEFT_2RowSeatReclineFoldAllowe 0;
BA_ "SystemSignalLongSymbol" SG_ 738 VCLEFT_2RowSeatReclineFoldAllowe "VCLEFT_2RowSeatReclineFoldAllowed";
BA_ "Confidence" SG_ 738 VCLEFT_2RowSeatReclineUnfoldAllo 0;
BA_ "SystemSignalLongSymbol" SG_ 738 VCLEFT_2RowSeatReclineUnfoldAllo "VCLEFT_2RowSeatReclineUnfoldAllowed";
BA_ "Confidence" SG_ 738 VCLEFT_2RowSeatReclineNextToggle 0;
BA_ "GenSigSNA" SG_ 738 VCLEFT_2RowSeatReclineNextToggle "2";
BA_ "SystemSignalLongSymbol" SG_ 738 VCLEFT_2RowSeatReclineNextToggle "VCLEFT_2RowSeatReclineNextToggleDirection";
BA_ "Confidence" SG_ 738 VCLEFT_2RowSeatReclineChoreoBloc 0;
BA_ "SystemSignalLongSymbol" SG_ 738 VCLEFT_2RowSeatReclineChoreoBloc "VCLEFT_2RowSeatReclineChoreoBlockedByOccupancy";
BA_ "Confidence" SG_ 738 VCLEFT_2RowSeat1RClashAvoidanceB 0;
BA_ "SystemSignalLongSymbol" SG_ 738 VCLEFT_2RowSeat1RClashAvoidanceB "VCLEFT_2RowSeat1RClashAvoidanceBlockedReason";
BA_ "Confidence" SG_ 738 VCLEFT_2RowSeat1RClashAvoidanceS 0;
BA_ "SystemSignalLongSymbol" SG_ 738 VCLEFT_2RowSeat1RClashAvoidanceS "VCLEFT_2RowSeat1RClashAvoidanceState";
BA_ "Confidence" SG_ 738 VCLEFT_2RowSeatReclineAbsPo_0001 0;
BA_ "SystemSignalLongSymbol" SG_ 738 VCLEFT_2RowSeatReclineAbsPo_0001 "VCLEFT_2RowSeatReclineAbsPosSwitchTransPoint";
BA_ "Confidence" SG_ 738 VC_AH_2RowLeftSeatMovementHealth 0;
BA_ "Confidence" SG_ 738 VCLEFT_3RowSeatReclineState 0;
BA_ "GenSigSNA" SG_ 738 VCLEFT_3RowSeatReclineState "15";
BA_ "Confidence" SG_ 738 VCLEFT_3RowSeatReclineDuty 0;
BA_ "Confidence" SG_ 738 VCLEFT_3RowSeatReclineCurrent 0;
BA_ "Confidence" SG_ 738 VCLEFT_3RowSeatReclineCalibrated 0;
BA_ "Confidence" SG_ 738 VCLEFT_3RowSeatReclinePositionRa 0;
BA_ "SystemSignalLongSymbol" SG_ 738 VCLEFT_3RowSeatReclinePositionRa "VCLEFT_3RowSeatReclinePositionRaw";
BA_ "Confidence" SG_ 738 VCLEFT_3RowSeatReclineAngle 0;
BA_ "Confidence" SG_ 738 VCLEFT_3RowSeatReclineNextToggle 0;
BA_ "GenSigSNA" SG_ 738 VCLEFT_3RowSeatReclineNextToggle "2";
BA_ "SystemSignalLongSymbol" SG_ 738 VCLEFT_3RowSeatReclineNextToggle "VCLEFT_3RowSeatReclineNextToggleDirection";
BA_ "Confidence" SG_ 738 VCLEFT_3RRightCushionHeatCurrent 0;
BA_ "Confidence" SG_ 738 VCLEFT_3RRightCushionHeatDuty 0;
BA_ "Confidence" SG_ 738 VCLEFT_3RRightCushionHeatTmp 0;
BA_ "Confidence" SG_ 738 VCLEFT_3RRightCushionHeatTmpTarg 0;
BA_ "SystemSignalLongSymbol" SG_ 738 VCLEFT_3RRightCushionHeatTmpTarg "VCLEFT_3RRightCushionHeatTmpTarget";
BA_ "Confidence" SG_ 738 VCLEFT_3RRightCushionHeatInhibit 0;
BA_ "SystemSignalLongSymbol" SG_ 738 VCLEFT_3RRightCushionHeatInhibit "VCLEFT_3RRightCushionHeatInhibited";
BA_ "Confidence" SG_ 738 VCLEFT_3RowSeatReclinePositionSt 0;
BA_ "GenSigSNA" SG_ 738 VCLEFT_3RowSeatReclinePositionSt "4";
BA_ "SystemSignalLongSymbol" SG_ 738 VCLEFT_3RowSeatReclinePositionSt "VCLEFT_3RowSeatReclinePositionState";
BA_ "Confidence" SG_ 738 VCLEFT_3RowSeatReclineAdjustment 0;
BA_ "SystemSignalLongSymbol" SG_ 738 VCLEFT_3RowSeatReclineAdjustment "VCLEFT_3RowSeatReclineAdjustmentAllowed";
BA_ "Confidence" SG_ 738 VCLEFT_3RowSeatReclineFoldAllowe 0;
BA_ "SystemSignalLongSymbol" SG_ 738 VCLEFT_3RowSeatReclineFoldAllowe "VCLEFT_3RowSeatReclineFoldAllowed";
BA_ "Confidence" SG_ 738 VCLEFT_3RowSeatReclineUnfoldAllo 0;
BA_ "SystemSignalLongSymbol" SG_ 738 VCLEFT_3RowSeatReclineUnfoldAllo "VCLEFT_3RowSeatReclineUnfoldAllowed";
BA_ "Confidence" SG_ 738 VCLEFT_3RowSeatReclineChoreoBloc 0;
BA_ "SystemSignalLongSymbol" SG_ 738 VCLEFT_3RowSeatReclineChoreoBloc "VCLEFT_3RowSeatReclineChoreoBlockedByOccupancy";
BA_ "Confidence" SG_ 738 VCLEFT_3RowSeatReclineAbsPosSwit 0;
BA_ "GenSigSNA" SG_ 738 VCLEFT_3RowSeatReclineAbsPosSwit "0";
BA_ "SystemSignalLongSymbol" SG_ 738 VCLEFT_3RowSeatReclineAbsPosSwit "VCLEFT_3RowSeatReclineAbsPosSwitchState";
BA_ "Confidence" SG_ 930 VCLEFT_statusIndex 0;
BA_ "Confidence" SG_ 930 VCLEFT_securityControllerEnable 0;
BA_ "Confidence" SG_ 930 VCLEFT_securityControllerVoltage 0;
BA_ "Confidence" SG_ 930 VCLEFT_consoleDoorAssist 0;
BA_ "Confidence" SG_ 930 VCLEFT_OTAState 0;
BA_ "Confidence" SG_ 930 VCLEFT_5AVoltage 0;
BA_ "Confidence" SG_ 930 VCLEFT_vbatProt 0;
BA_ "Confidence" SG_ 930 VCLEFT_footwellLightCurrent 0;
BA_ "Confidence" SG_ 930 VCLEFT_swcInputVoltage 0;
BA_ "GenSigSNA" SG_ 930 VCLEFT_swcInputVoltage "255";
BA_ "Confidence" SG_ 930 VCLEFT_swcPCBATemperature 0;
BA_ "GenSigSNA" SG_ 930 VCLEFT_swcPCBATemperature "128";
BA_ "Confidence" SG_ 930 VCLEFT_obdEthernetActive 0;
BA_ "Confidence" SG_ 930 VCLEFT_rationalityAggregateCurre 0;
BA_ "SystemSignalLongSymbol" SG_ 930 VCLEFT_rationalityAggregateCurre "VCLEFT_rationalityAggregateCurrent";
BA_ "Confidence" SG_ 930 VCLEFT_LVBatteryTypeDBG 0;
BA_ "Confidence" SG_ 930 VCLEFT_DIeFuseFault 0;
BA_ "Confidence" SG_ 930 VCLEFT_eFuseMgmtVoltageMonitor 0;
BA_ "Confidence" SG_ 930 VCLEFT_trailerAuxCurrent 0;
BA_ "GenSigSNA" SG_ 930 VCLEFT_trailerAuxCurrent "4095";
BA_ "Confidence" SG_ 930 VCLEFT_swcHeatTmp 0;
BA_ "GenSigSNA" SG_ 930 VCLEFT_swcHeatTmp "1023";
BA_ "Confidence" SG_ 930 VCLEFT_swcHeatStatus 0;
BA_ "GenSigSNA" SG_ 930 VCLEFT_swcHeatStatus "0";
BA_ "Confidence" SG_ 930 VCLEFT_swcHeatInhibited 0;
BA_ "Confidence" SG_ 930 VCLEFT_obdDeviceDetected 0;
BA_ "Confidence" SG_ 930 VCLEFT_pcbaTemperature 0;
BA_ "Confidence" SG_ 930 VCLEFT_swcHeatPwr 0;
BA_ "GenSigSNA" SG_ 930 VCLEFT_swcHeatPwr "511";
BA_ "Confidence" SG_ 930 VCLEFT_swcHeatDutyCycle 0;
BA_ "GenSigSNA" SG_ 930 VCLEFT_swcHeatDutyCycle "127";
BA_ "Confidence" SG_ 930 VCLEFT_DIeFuseCurrent 0;
BA_ "Confidence" SG_ 930 VCLEFT_SWCpresent 0;
BA_ "Confidence" SG_ 930 VCLEFT_trailerBrakeControllerCur 0;
BA_ "SystemSignalLongSymbol" SG_ 930 VCLEFT_trailerBrakeControllerCur "VCLEFT_trailerBrakeControllerCurrent";
BA_ "Confidence" SG_ 930 VCLEFT_autonomyBehaviorStatus 0;
BA_ "Confidence" SG_ 930 VCLEFT_thirdRowLeftMapLightStatu 0;
BA_ "GenSigSNA" SG_ 930 VCLEFT_thirdRowLeftMapLightStatu "3";
BA_ "SystemSignalLongSymbol" SG_ 930 VCLEFT_thirdRowLeftMapLightStatu "VCLEFT_thirdRowLeftMapLightStatus";
BA_ "Confidence" SG_ 930 VCLEFT_thirdRowRightMapLightStat 0;
BA_ "GenSigSNA" SG_ 930 VCLEFT_thirdRowRightMapLightStat "3";
BA_ "SystemSignalLongSymbol" SG_ 930 VCLEFT_thirdRowRightMapLightStat "VCLEFT_thirdRowRightMapLightStatus";
BA_ "Confidence" SG_ 610 VCLEFT_steeringColumnSMState 0;
BA_ "GenSigSNA" SG_ 610 VCLEFT_steeringColumnSMState "0";
BA_ "Confidence" SG_ 610 VCLEFT_steeringColumnLastRequest 0;
BA_ "GenSigSNA" SG_ 610 VCLEFT_steeringColumnLastRequest "0";
BA_ "Confidence" SG_ 610 VCLEFT_steeringColumnUpDownDuty 0;
BA_ "Confidence" SG_ 610 VCLEFT_steeringColumnInOutDuty 0;
BA_ "Confidence" SG_ 610 VCLEFT_steeringColumnUpDownPos 0;
BA_ "Confidence" SG_ 610 VCLEFT_steeringColumnInOutPos 0;
BA_ "Confidence" SG_ 610 VCLEFT_steeringColumnUpDownAmps 0;
BA_ "Confidence" SG_ 610 VCLEFT_steeringColumnInOutAmps 0;
BA_ "Confidence" SG_ 610 VCLEFT_steeringColumnUpDownCalib 0;
BA_ "Confidence" SG_ 610 VCLEFT_steeringColumnInOutCalib 0;
BA_ "Confidence" SG_ 610 VCLEFT_steeringColumnUpDownTC 0;
BA_ "Confidence" SG_ 610 VCLEFT_steeringColumnInOutTC 0;
BA_ "Confidence" SG_ 962 VCLEFT_switchStatusIndex 0;
BA_ "Confidence" SG_ 962 VCLEFT_hornSwitchPressed 0;
BA_ "Confidence" SG_ 962 VCLEFT_hazardButtonPressed 0;
BA_ "Confidence" SG_ 962 VCLEFT_brakeSwitchPressed 0;
BA_ "Confidence" SG_ 962 VCLEFT_rightMirrorTilt 0;
BA_ "Confidence" SG_ 962 VCLEFT_frontSeatTrackBack 0;
BA_ "GenSigSNA" SG_ 962 VCLEFT_frontSeatTrackBack "0";
BA_ "Confidence" SG_ 962 VCLEFT_frontSeatTrackForward 0;
BA_ "GenSigSNA" SG_ 962 VCLEFT_frontSeatTrackForward "0";
BA_ "Confidence" SG_ 962 VCLEFT_frontSeatTiltDown 0;
BA_ "GenSigSNA" SG_ 962 VCLEFT_frontSeatTiltDown "0";
BA_ "Confidence" SG_ 962 VCLEFT_frontSeatTiltUp 0;
BA_ "GenSigSNA" SG_ 962 VCLEFT_frontSeatTiltUp "0";
BA_ "Confidence" SG_ 962 VCLEFT_frontSeatLiftDown 0;
BA_ "GenSigSNA" SG_ 962 VCLEFT_frontSeatLiftDown "0";
BA_ "Confidence" SG_ 962 VCLEFT_frontSeatLiftUp 0;
BA_ "GenSigSNA" SG_ 962 VCLEFT_frontSeatLiftUp "0";
BA_ "Confidence" SG_ 962 VCLEFT_frontSeatBackrestBack 0;
BA_ "GenSigSNA" SG_ 962 VCLEFT_frontSeatBackrestBack "0";
BA_ "Confidence" SG_ 962 VCLEFT_frontSeatBackrestForward 0;
BA_ "GenSigSNA" SG_ 962 VCLEFT_frontSeatBackrestForward "0";
BA_ "Confidence" SG_ 962 VCLEFT_frontSeatLumbarDown 0;
BA_ "GenSigSNA" SG_ 962 VCLEFT_frontSeatLumbarDown "0";
BA_ "Confidence" SG_ 962 VCLEFT_frontSeatLumbarUp 0;
BA_ "GenSigSNA" SG_ 962 VCLEFT_frontSeatLumbarUp "0";
BA_ "Confidence" SG_ 962 VCLEFT_frontSeatLumbarIn 0;
BA_ "GenSigSNA" SG_ 962 VCLEFT_frontSeatLumbarIn "0";
BA_ "Confidence" SG_ 962 VCLEFT_frontSeatLumbarOut 0;
BA_ "GenSigSNA" SG_ 962 VCLEFT_frontSeatLumbarOut "0";
BA_ "Confidence" SG_ 962 VCLEFT_btnWindowSwPackUpLF 0;
BA_ "Confidence" SG_ 962 VCLEFT_btnWindowSwPackAutoUpLF 0;
BA_ "Confidence" SG_ 962 VCLEFT_btnWindowSwPackDownLF 0;
BA_ "Confidence" SG_ 962 VCLEFT_btnWindowSwPackAutoDownLF 0;
BA_ "Confidence" SG_ 962 VCLEFT_btnWindowSwPackUpLR 0;
BA_ "Confidence" SG_ 962 VCLEFT_btnWindowSwPackAutoUpLR 0;
BA_ "Confidence" SG_ 962 VCLEFT_btnWindowSwPackDownLR 0;
BA_ "Confidence" SG_ 962 VCLEFT_btnWindowSwPackAutoDownLR 0;
BA_ "Confidence" SG_ 962 VCLEFT_btnWindowSwPackUpRF 0;
BA_ "Confidence" SG_ 962 VCLEFT_btnWindowSwPackAutoUpRF 0;
BA_ "Confidence" SG_ 962 VCLEFT_btnWindowSwPackDownRF 0;
BA_ "Confidence" SG_ 962 VCLEFT_btnWindowSwPackAutoDownRF 0;
BA_ "Confidence" SG_ 962 VCLEFT_btnWindowSwPackUpRR 0;
BA_ "Confidence" SG_ 962 VCLEFT_btnWindowSwPackAutoUpRR 0;
BA_ "Confidence" SG_ 962 VCLEFT_btnWindowSwPackDownRR 0;
BA_ "Confidence" SG_ 962 VCLEFT_btnWindowSwPackAutoDownRR 0;
BA_ "Confidence" SG_ 962 VCLEFT_frontBuckleSwitch 0;
BA_ "GenSigSNA" SG_ 962 VCLEFT_frontBuckleSwitch "0";
BA_ "Confidence" SG_ 962 VCLEFT_frontOccupancySwitch 0;
BA_ "GenSigSNA" SG_ 962 VCLEFT_frontOccupancySwitch "0";
BA_ "Confidence" SG_ 962 VCLEFT_rearLeftBuckleSwitch 0;
BA_ "GenSigSNA" SG_ 962 VCLEFT_rearLeftBuckleSwitch "0";
BA_ "Confidence" SG_ 962 VCLEFT_rearCenterOccupancySwitch 0;
BA_ "GenSigSNA" SG_ 962 VCLEFT_rearCenterOccupancySwitch "0";
BA_ "Confidence" SG_ 962 VCLEFT_rearLeftOccupancySwitch 0;
BA_ "GenSigSNA" SG_ 962 VCLEFT_rearLeftOccupancySwitch "0";
BA_ "Confidence" SG_ 962 VCLEFT_rearRightOccupancySwitch 0;
BA_ "GenSigSNA" SG_ 962 VCLEFT_rearRightOccupancySwitch "0";
BA_ "Confidence" SG_ 962 VCLEFT_brakePressed 0;
BA_ "Confidence" SG_ 962 VCLEFT_rearHVACButtonPressed 0;
BA_ "Confidence" SG_ 962 VCLEFT_rearCenterBuckleSwitch 0;
BA_ "GenSigSNA" SG_ 962 VCLEFT_rearCenterBuckleSwitch "0";
BA_ "Confidence" SG_ 962 VCLEFT_isAlcoholInterlockSet 0;
BA_ "Confidence" SG_ 962 VCLEFT_swcLeftTiltRight 0;
BA_ "GenSigSNA" SG_ 962 VCLEFT_swcLeftTiltRight "0";
BA_ "Confidence" SG_ 962 VCLEFT_swcLeftPressed 0;
BA_ "GenSigSNA" SG_ 962 VCLEFT_swcLeftPressed "0";
BA_ "Confidence" SG_ 962 VCLEFT_swcRightTiltLeft 0;
BA_ "GenSigSNA" SG_ 962 VCLEFT_swcRightTiltLeft "0";
BA_ "Confidence" SG_ 962 VCLEFT_swcRightTiltRight 0;
BA_ "GenSigSNA" SG_ 962 VCLEFT_swcRightTiltRight "0";
BA_ "Confidence" SG_ 962 VCLEFT_swcRightPressed 0;
BA_ "GenSigSNA" SG_ 962 VCLEFT_swcRightPressed "0";
BA_ "Confidence" SG_ 962 VCLEFT_swcLeftTiltLeft 0;
BA_ "GenSigSNA" SG_ 962 VCLEFT_swcLeftTiltLeft "0";
BA_ "Confidence" SG_ 962 VCLEFT_swcLeftScrollTicks 0;
BA_ "Confidence" SG_ 962 VCLEFT_swcWiperButtonState 0;
BA_ "Confidence" SG_ 962 VCLEFT_swcRightScrollTicks 0;
BA_ "Confidence" SG_ 962 VCLEFT_swcTurnSignalLeftButtonSt 0;
BA_ "SystemSignalLongSymbol" SG_ 962 VCLEFT_swcTurnSignalLeftButtonSt "VCLEFT_swcTurnSignalLeftButtonState";
BA_ "Confidence" SG_ 962 VCLEFT_btnWindowUpLR 0;
BA_ "Confidence" SG_ 962 VCLEFT_btnWindowAutoUpLR 0;
BA_ "Confidence" SG_ 962 VCLEFT_btnWindowDownLR 0;
BA_ "Confidence" SG_ 962 VCLEFT_btnWindowAutoDownLR 0;
BA_ "Confidence" SG_ 962 VCLEFT_2RowSeatReclineSwitch 0;
BA_ "Confidence" SG_ 962 VCLEFT_2RowSeatCenterSwitch 0;
BA_ "Confidence" SG_ 962 VCLEFT_2RowSeatLeftFoldFlatSwitc 0;
BA_ "SystemSignalLongSymbol" SG_ 962 VCLEFT_2RowSeatLeftFoldFlatSwitc "VCLEFT_2RowSeatLeftFoldFlatSwitch";
BA_ "Confidence" SG_ 962 VCLEFT_2RowSeatRightFoldFlatSwit 0;
BA_ "SystemSignalLongSymbol" SG_ 962 VCLEFT_2RowSeatRightFoldFlatSwit "VCLEFT_2RowSeatRightFoldFlatSwitch";
BA_ "Confidence" SG_ 962 VCLEFT_2RowSeatBothFoldFlatSwitc 0;
BA_ "SystemSignalLongSymbol" SG_ 962 VCLEFT_2RowSeatBothFoldFlatSwitc "VCLEFT_2RowSeatBothFoldFlatSwitch";
BA_ "Confidence" SG_ 962 VCLEFT_swcLeftDoublePress 0;
BA_ "Confidence" SG_ 962 VCLEFT_swcRightDoublePress 0;
BA_ "Confidence" SG_ 962 VCLEFT_2RowSeatBackrestFoldSwitc 0;
BA_ "SystemSignalLongSymbol" SG_ 962 VCLEFT_2RowSeatBackrestFoldSwitc "VCLEFT_2RowSeatBackrestFoldSwitch";
BA_ "Confidence" SG_ 962 VCLEFT_swcTurnSignalRightButtonS 0;
BA_ "SystemSignalLongSymbol" SG_ 962 VCLEFT_swcTurnSignalRightButtonS "VCLEFT_swcTurnSignalRightButtonState";
BA_ "Confidence" SG_ 962 VCLEFT_swcHighBeamButtonState 0;
BA_ "Confidence" SG_ 962 VCLEFT_swcVoiceControlPress 0;
BA_ "GenSigSNA" SG_ 962 VCLEFT_swcVoiceControlPress "0";
BA_ "Confidence" SG_ 962 VCLEFT_swcCameraButtonState 0;
BA_ "Confidence" SG_ 962 VCLEFT_swcRightPressedQF 0;
BA_ "Confidence" SG_ 962 VCLEFT_2RowSeatReclineSwitchpack 0;
BA_ "SystemSignalLongSymbol" SG_ 962 VCLEFT_2RowSeatReclineSwitchpack "VCLEFT_2RowSeatReclineSwitchpackState";
BA_ "Confidence" SG_ 962 VCLEFT_3RowLeftBuckleSwitch 0;
BA_ "GenSigSNA" SG_ 962 VCLEFT_3RowLeftBuckleSwitch "0";
BA_ "Confidence" SG_ 962 VCLEFT_frontSeatThighSupportExte 0;
BA_ "GenSigSNA" SG_ 962 VCLEFT_frontSeatThighSupportExte "0";
BA_ "SystemSignalLongSymbol" SG_ 962 VCLEFT_frontSeatThighSupportExte "VCLEFT_frontSeatThighSupportExtendSwitch";
BA_ "Confidence" SG_ 962 VCLEFT_frontSeatThighSupportRetr 0;
BA_ "GenSigSNA" SG_ 962 VCLEFT_frontSeatThighSupportRetr "0";
BA_ "SystemSignalLongSymbol" SG_ 962 VCLEFT_frontSeatThighSupportRetr "VCLEFT_frontSeatThighSupportRetractSwitch";
BA_ "Confidence" SG_ 962 VCLEFT_frontSeatResistiveOccupan 0;
BA_ "GenSigSNA" SG_ 962 VCLEFT_frontSeatResistiveOccupan "0";
BA_ "SystemSignalLongSymbol" SG_ 962 VCLEFT_frontSeatResistiveOccupan "VCLEFT_frontSeatResistiveOccupancy";
BA_ "Confidence" SG_ 656 VCLEFT_thermalLogging10HzIndex 1;
BA_ "Confidence" SG_ 656 VCLEFT_hvac2RLeftLateralVoltage 0;
BA_ "Confidence" SG_ 656 VCLEFT_hvac2RLeftVerticalVoltage 0;
BA_ "Confidence" SG_ 656 VCLEFT_hvac2RRightLateralVoltage 0;
BA_ "Confidence" SG_ 656 VCLEFT_hvac2RRightVerticalVoltag 0;
BA_ "SystemSignalLongSymbol" SG_ 656 VCLEFT_hvac2RRightVerticalVoltag "VCLEFT_hvac2RRightVerticalVoltage";
BA_ "Confidence" SG_ 656 VCLEFT_hvac2RLeftLateralCalibrat 0;
BA_ "SystemSignalLongSymbol" SG_ 656 VCLEFT_hvac2RLeftLateralCalibrat "VCLEFT_hvac2RLeftLateralCalibrated";
BA_ "Confidence" SG_ 656 VCLEFT_hvac2RLeftVerticalCalibra 0;
BA_ "SystemSignalLongSymbol" SG_ 656 VCLEFT_hvac2RLeftVerticalCalibra "VCLEFT_hvac2RLeftVerticalCalibrated";
BA_ "Confidence" SG_ 656 VCLEFT_hvac2RRightLateralCalibra 0;
BA_ "SystemSignalLongSymbol" SG_ 656 VCLEFT_hvac2RRightLateralCalibra "VCLEFT_hvac2RRightLateralCalibrated";
BA_ "Confidence" SG_ 656 VCLEFT_hvac2RRightVerticalCalibr 0;
BA_ "SystemSignalLongSymbol" SG_ 656 VCLEFT_hvac2RRightVerticalCalibr "VCLEFT_hvac2RRightVerticalCalibrated";
BA_ "Confidence" SG_ 656 VCLEFT_hvac2RLeftLateralState 0;
BA_ "Confidence" SG_ 656 VCLEFT_hvac2RLeftVerticalState 0;
BA_ "Confidence" SG_ 656 VCLEFT_hvac2RRightLateralState 0;
BA_ "Confidence" SG_ 656 VCLEFT_hvac2RRightVerticalState 0;
BA_ "Confidence" SG_ 656 VCLEFT_hvacBlowerWindmillElecRpm 0;
BA_ "Confidence" SG_ 656 VCLEFT_hvac2RRightVerticalVeloci 0;
BA_ "SystemSignalLongSymbol" SG_ 656 VCLEFT_hvac2RRightVerticalVeloci "VCLEFT_hvac2RRightVerticalVelocity";
BA_ "Confidence" SG_ 656 VCLEFT_hvacBlowerWindmillBemf 0;
BA_ "Confidence" SG_ 656 VCLEFT_hvac2RLeftVerticalVelocit 0;
BA_ "SystemSignalLongSymbol" SG_ 656 VCLEFT_hvac2RLeftVerticalVelocit "VCLEFT_hvac2RLeftVerticalVelocity";
BA_ "Confidence" SG_ 656 VCLEFT_hvac2RLeftLateralVelocity 0;
BA_ "Confidence" SG_ 656 VCLEFT_vcusbLinSchedule 0;
BA_ "Confidence" SG_ 656 VCLEFT_hvacBlowerArbState 0;
BA_ "Confidence" SG_ 656 VCLEFT_hvacBlowerArbResult 0;
BA_ "Confidence" SG_ 656 VCLEFT_hvac2RLeftLateralDuty 0;
BA_ "Confidence" SG_ 656 VCLEFT_hvac2RLeftVerticalDuty 0;
BA_ "Confidence" SG_ 656 VCLEFT_hvac2RRightLateralDuty 0;
BA_ "Confidence" SG_ 656 VCLEFT_hvac2RRightVerticalDuty 0;
BA_ "Confidence" SG_ 656 VCLEFT_hvacBlowerWindmilling 0;
BA_ "Confidence" SG_ 656 VCLEFT_hvac2RRightLateralVelocit 0;
BA_ "SystemSignalLongSymbol" SG_ 656 VCLEFT_hvac2RRightLateralVelocit "VCLEFT_hvac2RRightLateralVelocity";
BA_ "Confidence" SG_ 656 VCLEFT_hvacBlower1msOverrunFrequ 0;
BA_ "SystemSignalLongSymbol" SG_ 656 VCLEFT_hvacBlower1msOverrunFrequ "VCLEFT_hvacBlower1msOverrunFrequency";
BA_ "Confidence" SG_ 656 VCLEFT_hvacBlower10msOverrunFreq 0;
BA_ "SystemSignalLongSymbol" SG_ 656 VCLEFT_hvacBlower10msOverrunFreq "VCLEFT_hvacBlower10msOverrunFrequency";
BA_ "Confidence" SG_ 657 VCLEFT_thermalLogging1HzIndex 1;
BA_ "Confidence" SG_ 657 VCLEFT_hvac2RLeftLateralZeroStop 0;
BA_ "SystemSignalLongSymbol" SG_ 657 VCLEFT_hvac2RLeftLateralZeroStop "VCLEFT_hvac2RLeftLateralZeroStopVoltage";
BA_ "Confidence" SG_ 657 VCLEFT_hvac2RLeftVerticalZeroSto 0;
BA_ "SystemSignalLongSymbol" SG_ 657 VCLEFT_hvac2RLeftVerticalZeroSto "VCLEFT_hvac2RLeftVerticalZeroStopVoltage";
BA_ "Confidence" SG_ 657 VCLEFT_hvac2RRightLateralZeroSto 0;
BA_ "SystemSignalLongSymbol" SG_ 657 VCLEFT_hvac2RRightLateralZeroSto "VCLEFT_hvac2RRightLateralZeroStopVoltage";
BA_ "Confidence" SG_ 657 VCLEFT_hvac2RRightVerticalZeroSt 0;
BA_ "SystemSignalLongSymbol" SG_ 657 VCLEFT_hvac2RRightVerticalZeroSt "VCLEFT_hvac2RRightVerticalZeroStopVoltage";
BA_ "Confidence" SG_ 657 VCLEFT_hvac2RLeftLateralEndStopV 0;
BA_ "SystemSignalLongSymbol" SG_ 657 VCLEFT_hvac2RLeftLateralEndStopV "VCLEFT_hvac2RLeftLateralEndStopVoltage";
BA_ "Confidence" SG_ 657 VCLEFT_hvac2RLeftVerticalEndStop 0;
BA_ "SystemSignalLongSymbol" SG_ 657 VCLEFT_hvac2RLeftVerticalEndStop "VCLEFT_hvac2RLeftVerticalEndStopVoltage";
BA_ "Confidence" SG_ 657 VCLEFT_hvac2RRightLateralEndStop 0;
BA_ "SystemSignalLongSymbol" SG_ 657 VCLEFT_hvac2RRightLateralEndStop "VCLEFT_hvac2RRightLateralEndStopVoltage";
BA_ "Confidence" SG_ 657 VCLEFT_hvac2RRightVerticalEndSto 0;
BA_ "SystemSignalLongSymbol" SG_ 657 VCLEFT_hvac2RRightVerticalEndSto "VCLEFT_hvac2RRightVerticalEndStopVoltage";
BA_ "Confidence" SG_ 657 VCLEFT_hvacBlowerArbCurrent 0;
BA_ "Confidence" SG_ 657 VCLEFT_hvacBlowerTorqueIndexFilt 0;
BA_ "SystemSignalLongSymbol" SG_ 657 VCLEFT_hvacBlowerTorqueIndexFilt "VCLEFT_hvacBlowerTorqueIndexFiltered";
BA_ "Confidence" SG_ 386 VCLEFT_hvac2RLeftLateralStatus 0;
BA_ "Confidence" SG_ 386 VCLEFT_hvac2RLeftVerticalStatus 0;
BA_ "Confidence" SG_ 386 VCLEFT_hvac2RRightLateralStatus 0;
BA_ "Confidence" SG_ 386 VCLEFT_hvac2RRightVerticalStatus 0;
BA_ "Confidence" SG_ 386 VCLEFT_hvac2RLeftLateralPosition 0;
BA_ "Confidence" SG_ 386 VCLEFT_hvac2RLeftVerticalPositio 0;
BA_ "SystemSignalLongSymbol" SG_ 386 VCLEFT_hvac2RLeftVerticalPositio "VCLEFT_hvac2RLeftVerticalPosition";
BA_ "Confidence" SG_ 386 VCLEFT_hvac2RRightLateralPositio 0;
BA_ "SystemSignalLongSymbol" SG_ 386 VCLEFT_hvac2RRightLateralPositio "VCLEFT_hvac2RRightLateralPosition";
BA_ "Confidence" SG_ 386 VCLEFT_hvac2RRightVerticalPositi 0;
BA_ "SystemSignalLongSymbol" SG_ 386 VCLEFT_hvac2RRightVerticalPositi "VCLEFT_hvac2RRightVerticalPosition";
BA_ "Confidence" SG_ 1571 VCLEFT_udsResponseData_H 1;
BA_ "Confidence" SG_ 1571 VCLEFT_udsResponseData_L 1;
BA_ "Confidence" SG_ 706 VCLEFT_windowStatusIndex 0;
BA_ "Confidence" SG_ 706 VCLEFT_windowStateLF 0;
BA_ "Confidence" SG_ 706 VCLEFT_windowTrimClearMoveReques 0;
BA_ "SystemSignalLongSymbol" SG_ 706 VCLEFT_windowTrimClearMoveReques "VCLEFT_windowTrimClearMoveRequest";
BA_ "Confidence" SG_ 706 VCLEFT_windowDutyLF 0;
BA_ "Confidence" SG_ 706 VCLEFT_windowTrimClearActiveRequ 0;
BA_ "GenSigSNA" SG_ 706 VCLEFT_windowTrimClearActiveRequ "0";
BA_ "SystemSignalLongSymbol" SG_ 706 VCLEFT_windowTrimClearActiveRequ "VCLEFT_windowTrimClearActiveRequest";
BA_ "Confidence" SG_ 706 VCLEFT_windowCurrentLF 0;
BA_ "Confidence" SG_ 706 VCLEFT_windowPositionLF 0;
BA_ "GenSigSNA" SG_ 706 VCLEFT_windowPositionLF "1";
BA_ "Confidence" SG_ 706 VCLEFT_windowCalibratedLF 0;
BA_ "Confidence" SG_ 706 VCLEFT_windowStateLR 0;
BA_ "Confidence" SG_ 706 VCLEFT_windowDutyLR 0;
BA_ "Confidence" SG_ 706 VCLEFT_windowCurrentLR 0;
BA_ "Confidence" SG_ 706 VCLEFT_windowPositionLR 0;
BA_ "Confidence" SG_ 706 VCLEFT_windowCalibratedLR 0;
BA_ "Confidence" SG_ 706 VCLEFT_windowThermalTCLF 0;
BA_ "Confidence" SG_ 706 VCLEFT_windowThermalModeLF 0;
BA_ "GenSigSNA" SG_ 706 VCLEFT_windowThermalModeLF "0";
BA_ "Confidence" SG_ 706 VCLEFT_windowStopReasonLF 0;
BA_ "Confidence" SG_ 706 VCLEFT_windowStopReqReasonLF 0;
BA_ "Confidence" SG_ 706 VCLEFT_windowThermalTCLR 0;
BA_ "Confidence" SG_ 706 VCLEFT_windowThermalModeLR 0;
BA_ "GenSigSNA" SG_ 706 VCLEFT_windowThermalModeLR "0";
BA_ "Confidence" SG_ 706 VCLEFT_windowStopReasonLR 0;
BA_ "Confidence" SG_ 706 VCLEFT_windowStopReqReasonLR 0;
BA_ "Confidence" SG_ 706 VCLEFT_windowControlStateLF 0;
BA_ "Confidence" SG_ 706 VCLEFT_windowCtrlUnavailableLF 0;
BA_ "Confidence" SG_ 706 VCLEFT_windowControlStateLR 0;
BA_ "Confidence" SG_ 706 VCLEFT_windowCtrlUnavailableLR 0;
BA_ "Confidence" SG_ 706 VCLEFT_windowPositionStateLF 0;
BA_ "Confidence" SG_ 706 VCLEFT_windowPositionStateLR 0;
BA_ "Confidence" SG_ 706 VCLEFT_windowVehGearStateLF 0;
BA_ "GenSigSNA" SG_ 706 VCLEFT_windowVehGearStateLF "0";
BA_ "Confidence" SG_ 706 VCLEFT_windowVehGearStateLR 0;
BA_ "GenSigSNA" SG_ 706 VCLEFT_windowVehGearStateLR "0";
BA_ "Confidence" SG_ 706 VCLEFT_windowSpeedTableStatusLF 0;
BA_ "GenSigSNA" SG_ 706 VCLEFT_windowSpeedTableStatusLF "0";
BA_ "Confidence" SG_ 706 VCLEFT_windowSpeedTableStatusLR 0;
BA_ "GenSigSNA" SG_ 706 VCLEFT_windowSpeedTableStatusLR "0";
BA_ "Confidence" SG_ 1114 VCRIGHT_AP_hvacState10HzIndex 0;
BA_ "Confidence" SG_ 1114 VCRIGHT_AP_autoDefogAvailable 0;
BA_ "Confidence" SG_ 1114 VCRIGHT_AP_hvacFlashFoggingDetec 0;
BA_ "SystemSignalLongSymbol" SG_ 1114 VCRIGHT_AP_hvacFlashFoggingDetec "VCRIGHT_AP_hvacFlashFoggingDetected";
BA_ "Confidence" SG_ 1114 VCRIGHT_AP_hvacModelInitStatus 0;
BA_ "Confidence" SG_ 1114 VCRIGHT_AP_cabinTempWindshield 0;
BA_ "GenSigSNA" SG_ 1114 VCRIGHT_AP_cabinTempWindshield "255";
BA_ "Confidence" SG_ 1114 VCRIGHT_AP_cabinTempSideGlassRig 0;
BA_ "GenSigSNA" SG_ 1114 VCRIGHT_AP_cabinTempSideGlassRig "255";
BA_ "SystemSignalLongSymbol" SG_ 1114 VCRIGHT_AP_cabinTempSideGlassRig "VCRIGHT_AP_cabinTempSideGlassRight";
BA_ "Confidence" SG_ 1114 VCRIGHT_AP_cabinTempSideGlassLef 0;
BA_ "GenSigSNA" SG_ 1114 VCRIGHT_AP_cabinTempSideGlassLef "255";
BA_ "SystemSignalLongSymbol" SG_ 1114 VCRIGHT_AP_cabinTempSideGlassLef "VCRIGHT_AP_cabinTempSideGlassLeft";
BA_ "Confidence" SG_ 1114 VCRIGHT_AP_hvacRecircDoorPercent 0;
BA_ "Confidence" SG_ 1114 VCRIGHT_AP_hvacAirDistributionMo 0;
BA_ "SystemSignalLongSymbol" SG_ 1114 VCRIGHT_AP_hvacAirDistributionMo "VCRIGHT_AP_hvacAirDistributionMode";
BA_ "Confidence" SG_ 1114 VCRIGHT_AP_hvacEstimateWindshiel 0;
BA_ "SystemSignalLongSymbol" SG_ 1114 VCRIGHT_AP_hvacEstimateWindshiel "VCRIGHT_AP_hvacEstimateWindshieldRH";
BA_ "Confidence" SG_ 1114 VCRIGHT_AP_hvacMassflowTarget 0;
BA_ "Confidence" SG_ 1114 VCRIGHT_AP_tempDuctDefrost 0;
BA_ "GenSigSNA" SG_ 1114 VCRIGHT_AP_tempDuctDefrost "255";
BA_ "Confidence" SG_ 1114 VCRIGHT_AP_cameraTurnOnTime 0;
BA_ "GenSigSNA" SG_ 1114 VCRIGHT_AP_cameraTurnOnTime "511";
BA_ "Confidence" SG_ 1114 VCRIGHT_AP_cameraDefogType 0;
BA_ "Confidence" SG_ 1114 VCRIGHT_ah_hvacFaultSurvivabilit 0;
BA_ "GenSigSNA" SG_ 1114 VCRIGHT_ah_hvacFaultSurvivabilit "31";
BA_ "SystemSignalLongSymbol" SG_ 1114 VCRIGHT_ah_hvacFaultSurvivabilit "VCRIGHT_ah_hvacFaultSurvivabilityTime";
BA_ "Confidence" SG_ 1114 VCRIGHT_ah_defoggingTimeNeeded 0;
BA_ "GenSigSNA" SG_ 1114 VCRIGHT_ah_defoggingTimeNeeded "31";
BA_ "Confidence" SG_ 1114 VCRIGHT_AP_cameraFanDutyRequest 0;
BA_ "GenSigSNA" SG_ 1114 VCRIGHT_AP_cameraFanDutyRequest "127";
BA_ "Confidence" SG_ 1114 VCRIGHT_ah_defogSystemState 0;
BA_ "GenSigSNA" SG_ 1114 VCRIGHT_ah_defogSystemState "7";
BA_ "Confidence" SG_ 1114 VCRIGHT_AP_turnForwardCameraHeat 0;
BA_ "SystemSignalLongSymbol" SG_ 1114 VCRIGHT_AP_turnForwardCameraHeat "VCRIGHT_AP_turnForwardCameraHeaterOnReason";
BA_ "Confidence" SG_ 1114 VCRIGHT_AP_turnCameraFanOffReaso 0;
BA_ "SystemSignalLongSymbol" SG_ 1114 VCRIGHT_AP_turnCameraFanOffReaso "VCRIGHT_AP_turnCameraFanOffReason";
BA_ "Confidence" SG_ 1114 VCRIGHT_AP_forwardCameraIntegrat 0;
BA_ "SystemSignalLongSymbol" SG_ 1114 VCRIGHT_AP_forwardCameraIntegrat "VCRIGHT_AP_forwardCameraIntegratedHeaterRequest";
BA_ "Confidence" SG_ 1114 VCRIGHT_AP_solarFluxOnRightWindo 0;
BA_ "GenSigSNA" SG_ 1114 VCRIGHT_AP_solarFluxOnRightWindo "255";
BA_ "SystemSignalLongSymbol" SG_ 1114 VCRIGHT_AP_solarFluxOnRightWindo "VCRIGHT_AP_solarFluxOnRightWindow";
BA_ "Confidence" SG_ 1114 VCRIGHT_AP_solarFluxOnLeftWindow 0;
BA_ "GenSigSNA" SG_ 1114 VCRIGHT_AP_solarFluxOnLeftWindow "255";
BA_ "Confidence" SG_ 1124 VCRIGHT_AP_hvacState1HzIndex 1;
BA_ "Confidence" SG_ 1124 VCRIGHT_AP_tempCameraModele_0001 1;
BA_ "GenSigSNA" SG_ 1124 VCRIGHT_AP_tempCameraModele_0001 "255";
BA_ "SystemSignalLongSymbol" SG_ 1124 VCRIGHT_AP_tempCameraModele_0001 "VCRIGHT_AP_tempCameraModeledWindshieldOut";
BA_ "Confidence" SG_ 1124 VCRIGHT_AP_tempCameraModeledWind 1;
BA_ "GenSigSNA" SG_ 1124 VCRIGHT_AP_tempCameraModeledWind "255";
BA_ "SystemSignalLongSymbol" SG_ 1124 VCRIGHT_AP_tempCameraModeledWind "VCRIGHT_AP_tempCameraModeledWindshieldIn";
BA_ "Confidence" SG_ 1124 VCRIGHT_AP_cameraModeledWin_0001 1;
BA_ "GenSigSNA" SG_ 1124 VCRIGHT_AP_cameraModeledWin_0001 "127";
BA_ "SystemSignalLongSymbol" SG_ 1124 VCRIGHT_AP_cameraModeledWin_0001 "VCRIGHT_AP_cameraModeledWindshieldOutRh";
BA_ "Confidence" SG_ 1124 VCRIGHT_AP_cameraModeledWindshie 1;
BA_ "GenSigSNA" SG_ 1124 VCRIGHT_AP_cameraModeledWindshie "127";
BA_ "SystemSignalLongSymbol" SG_ 1124 VCRIGHT_AP_cameraModeledWindshie "VCRIGHT_AP_cameraModeledWindshieldInRh";
BA_ "Confidence" SG_ 1124 VCRIGHT_AP_maxAchievableASideTem 1;
BA_ "SystemSignalLongSymbol" SG_ 1124 VCRIGHT_AP_maxAchievableASideTem "VCRIGHT_AP_maxAchievableASideTempCameraPocket";
BA_ "Confidence" SG_ 1124 VCRIGHT_AP_cameraModeledPocketWa 1;
BA_ "GenSigSNA" SG_ 1124 VCRIGHT_AP_cameraModeledPocketWa "1023";
BA_ "SystemSignalLongSymbol" SG_ 1124 VCRIGHT_AP_cameraModeledPocketWa "VCRIGHT_AP_cameraModeledPocketWaterMass";
BA_ "Confidence" SG_ 1124 VCRIGHT_AP_humidityModelInitStat 1;
BA_ "SystemSignalLongSymbol" SG_ 1124 VCRIGHT_AP_humidityModelInitStat "VCRIGHT_AP_humidityModelInitStatus";
BA_ "Confidence" SG_ 1124 VCRIGHT_AP_humidityModelStatus 1;
BA_ "Confidence" SG_ 549 VCRIGHT_ptcLVState 0;
BA_ "Confidence" SG_ 549 VCRIGHT_ocsLVState 0;
BA_ "Confidence" SG_ 549 VCRIGHT_premAudioLVState 0;
BA_ "Confidence" SG_ 549 VCRIGHT_rearOilPumpLVState 0;
BA_ "Confidence" SG_ 549 VCRIGHT_tunerLVState 0;
BA_ "Confidence" SG_ 549 VCRIGHT_hvcLVState 0;
BA_ "Confidence" SG_ 549 VCRIGHT_rcmLVState 0;
BA_ "Confidence" SG_ 549 VCRIGHT_lumbarLVState 0;
BA_ "Confidence" SG_ 549 VCRIGHT_3RUSBPowered 0;
BA_ "Confidence" SG_ 549 VCRIGHT_cntctrPwrState 0;
BA_ "Confidence" SG_ 549 VCRIGHT_eFuseLockoutStatus 0;
BA_ "Confidence" SG_ 549 VCRIGHT_swEnStatus 0;
BA_ "Confidence" SG_ 549 VCRIGHT_vehiclePowerStateDBG 0;
BA_ "Confidence" SG_ 549 VCRIGHT_parkLVState 0;
BA_ "Confidence" SG_ 549 VCRIGHT_icrLVState 0;
BA_ "Confidence" SG_ 549 VCRIGHT_interiorCameraLedLVState 1;
BA_ "Confidence" SG_ 549 VCRIGHT_diLVState 0;
BA_ "Confidence" SG_ 549 VCRIGHT_accDevicesDetected 0;
BA_ "Confidence" SG_ 643 VCRIGHT_PTCLeftTargetPowerHV 0;
BA_ "Confidence" SG_ 643 VCRIGHT_PTCRightTargetPowerHV 0;
BA_ "Confidence" SG_ 643 VCRIGHT_PTCLeftTargetDuty 0;
BA_ "Confidence" SG_ 643 VCRIGHT_PTCRightTargetDuty 0;
BA_ "Confidence" SG_ 643 VCRIGHT_PTCFlagAllowOperation 0;
BA_ "Confidence" SG_ 643 VCRIGHT_PTCRequestMode 0;
BA_ "Confidence" SG_ 643 VCRIGHT_PTCResistanceCheckEnable 0;
BA_ "Confidence" SG_ 643 VCRIGHT_PTCReset 0;
BA_ "Confidence" SG_ 643 VCRIGHT_PTCLeftDirectDriveIGBTO 0;
BA_ "Confidence" SG_ 643 VCRIGHT_PTCLeftDirectDriveIGBTC 0;
BA_ "Confidence" SG_ 643 VCRIGHT_PTCLeftDirectDriveIGBTI 0;
BA_ "Confidence" SG_ 643 VCRIGHT_PTCRightDirectDriveIGBTI 0;
BA_ "Confidence" SG_ 643 VCRIGHT_PTCRightDirectDriveIGBTC 0;
BA_ "Confidence" SG_ 643 VCRIGHT_PTCRightDirectDriveIGBTO 0;
BA_ "Confidence" SG_ 2011 VCRIGHT_alertID 1;
BA_ "Confidence" SG_ 2011 VCRIGHT_alertState 1;
BA_ "SystemSignalLongSymbol" SG_ 2011 VCRIGHT_a010_UnderVoltageDetecte "VCRIGHT_a010_UnderVoltageDetected";
BA_ "Confidence" SG_ 2011 VCRIGHT_a059_voltageDrop 1;
BA_ "Confidence" SG_ 2011 VCRIGHT_a059_resistanceEstimate 1;
BA_ "Confidence" SG_ 2011 VCRIGHT_a059_current 1;
BA_ "Confidence" SG_ 2011 VCRIGHT_a063_ADCVoltage 1;
BA_ "SystemSignalLongSymbol" SG_ 2011 VCRIGHT_a082_RIPC_epbPrivateStat "VCRIGHT_a082_RIPC_epbPrivateState";
BA_ "SystemSignalLongSymbol" SG_ 2011 VCRIGHT_a083_LIPC_epbPrivateStat "VCRIGHT_a083_LIPC_epbPrivateState";
BA_ "SystemSignalLongSymbol" SG_ 2011 VCRIGHT_a086_VEH_LVBMS_statusHig "VCRIGHT_a086_VEH_LVBMS_statusHigh";
BA_ "SystemSignalLongSymbol" SG_ 2011 VCRIGHT_a086_VEH_12VBatteryStatu "VCRIGHT_a086_VEH_12VBatteryStatus";
BA_ "SystemSignalLongSymbol" SG_ 2011 VCRIGHT_a086_BDY_12VBatteryStatu "VCRIGHT_a086_BDY_12VBatteryStatus";
BA_ "SystemSignalLongSymbol" SG_ 2011 VCRIGHT_a087_PARTY_thermalContro "VCRIGHT_a087_PARTY_thermalControl";
BA_ "SystemSignalLongSymbol" SG_ 2011 VCRIGHT_a088_PARTY_thermalContro "VCRIGHT_a088_PARTY_thermalControl";
BA_ "SystemSignalLongSymbol" SG_ 2011 VCRIGHT_a098_PARTY_thermalContro "VCRIGHT_a098_PARTY_thermalControl";
BA_ "SystemSignalLongSymbol" SG_ 2011 VCRIGHT_a101_LIPC_externalWatchd "VCRIGHT_a101_LIPC_externalWatchdogHeartBeat";
BA_ "SystemSignalLongSymbol" SG_ 2011 VCRIGHT_a108_PARTY_thermalContro "VCRIGHT_a108_PARTY_thermalControl";
BA_ "SystemSignalLongSymbol" SG_ 2011 VCRIGHT_a110_VEH_canLogAvailabil "VCRIGHT_a110_VEH_canLogAvailability";
BA_ "SystemSignalLongSymbol" SG_ 2011 VCRIGHT_a110_CH_airbagCutoffStat "VCRIGHT_a110_CH_airbagCutoffStatus";
BA_ "SystemSignalLongSymbol" SG_ 2011 VCRIGHT_a111_RIPC_epbPrivateStat "VCRIGHT_a111_RIPC_epbPrivateState";
BA_ "SystemSignalLongSymbol" SG_ 2011 VCRIGHT_a112_LIPC_epbPrivateStat "VCRIGHT_a112_LIPC_epbPrivateState";
BA_ "SystemSignalLongSymbol" SG_ 2011 VCRIGHT_a115_UI_corianderVehicle "VCRIGHT_a115_UI_corianderVehicleControl";
BA_ "SystemSignalLongSymbol" SG_ 2011 VCRIGHT_a115_VEH_authenticationW "VCRIGHT_a115_VEH_authenticationWithMac";
VAL_ 727 VCLEFT_pitchEstimateFusionState 7 "PITCHESTIMATION_STATE_UNKNOWN" 4 "PITCHESTIMATION_STATE_CALCULATE" 3 "PITCHESTIMATION_STATE_WAIT_FOR_STARTUP" 2 "PITCHESTIMATION_STATE_WAIT_FOR_SPEED" 1 "PITCHESTIMATION_STATE_WAIT_FOR_SIGNALS_AND_DOORS" 0 "PITCHESTIMATION_STATE_INIT" ;
VAL_ 727 VCLEFT_pitchEstimateStateTransit 26 "PITCHESTIMATION_DELTA_LIVE_THEN_VALIDITIES_NOT_GOOD" 25 "PITCHESTIMATION_DELTA_LIVE_THEN_FUSION_INIT" 24 "PITCHESTIMATION_DELTA_LIVE_THEN_LIVE_AX" 23 "PITCHESTIMATION_DELTA_LIVE_THEN_SPEED_AND_EPB_NOT_PARKED" 22 "PITCHESTIMATION_DELTA_LIVE_THEN_NVRAM_DISALLOW" 21 "PITCHESTIMATION_DELTA_LIVE_THEN_TRANSPORT" 20 "PITCHESTIMATION_DELTA_LIVE_THEN_DOORS_CLOSED_LONG_TIME" 19 "PITCHESTIMATION_DELTA_LIVE_THEN_EPB_RELEASING" 18 "PITCHESTIMATION_CARRYOVER_THEN_LIVE_AX" 17 "PITCHESTIMATION_CARRYOVER_THEN_FUSION_READY" 16 "PITCHESTIMATION_CARRYOVER_THEN_VALIDITIES_NOT_GOOD" 15 "PITCHESTIMATION_CARRYOVER_THEN_FUSION_INIT" 14 "PITCHESTIMATION_FROZEN_THEN_LIVE_AX" 13 "PITCHESTIMATION_FROZEN_THEN_FUSION_READY" 12 "PITCHESTIMATION_FROZEN_THEN_VALIDITIES_NOT_GOOD" 11 "PITCHESTIMATION_FROZEN_THEN_FUSION_INIT" 10 "PITCHESTIMATION_FUSION_THEN_LIVE_AX" 9 "PITCHESTIMATION_FUSION_THEN_FUSION_INIT" 8 "PITCHESTIMATION_UNAVAILABLE_THEN_LIVE_AX" 7 "PITCHESTIMATION_UNAVAILABLE_THEN_FUSION_READY" 6 "PITCHESTIMATION_UNAVAILABLE_THEN_DELTA_LIVE_READY" 5 "PITCHESTIMATION_UNAVAILABLE_THEN_SPEED_AND_EPB_NOT_PARKED" 4 "PITCHESTIMATION_UNAVAILABLE_THEN_NVRAM_DISALLOW" 3 "PITCHESTIMATION_UNAVAILABLE_THEN_TRANSPORT" 2 "PITCHESTIMATION_LIVE_AX_THEN_VALIDITIES_NOT_GOOD" 1 "PITCHESTIMATION_LIVE_AX_THEN_NO_LONGER_LIVE_AX" 0 "PITCHESTIMATION_INVALID_STATE_TRANSITION_DEFAULT" ;
VAL_ 727 VCLEFT_pitchEstimateArbitratedSt 7 "PITCHESTIMATION_ARBITRATEDSTATE_UNKNOWN" 5 "PITCHESTIMATION_ARBITRATEDSTATE_LIVE_AX_NO_DELTA" 4 "PITCHESTIMATION_ARBITRATEDSTATE_CYCLE_DELTA_FROZEN" 3 "PITCHESTIMATION_ARBITRATEDSTATE_CYCLE_DELTA_CARRYOVER" 2 "PITCHESTIMATION_ARBITRATEDSTATE_CYCLE_DELTA_LIVE" 1 "PITCHESTIMATION_ARBITRATEDSTATE_FUSION" 0 "PITCHESTIMATION_ARBITRATEDSTATE_UNAVAILABLE" ;
VAL_ 727 VCLEFT_pitchEstimate -512 "SNA" ;
VAL_ 1860 VCLEFT_systemRecallStatus 3 "RECALL_INTERRUPTED" 2 "RECALL_COMPLETE" 1 "RECALL_IN_PROGRESS" 0 "RECALL_SNA" ;
VAL_ 1860 VCLEFT_seatRecallStatus 3 "RECALL_INTERRUPTED" 2 "RECALL_COMPLETE" 1 "RECALL_IN_PROGRESS" 0 "RECALL_SNA" ;
VAL_ 1860 VCLEFT_columnRecallStatus 3 "RECALL_INTERRUPTED" 2 "RECALL_COMPLETE" 1 "RECALL_IN_PROGRESS" 0 "RECALL_SNA" ;
VAL_ 1860 VCLEFT_mirrorRecallStatus 3 "RECALL_INTERRUPTED" 2 "RECALL_COMPLETE" 1 "RECALL_IN_PROGRESS" 0 "RECALL_SNA" ;
VAL_ 1863 VCLEFT_frontOccupancyStatus 7 "SEAT_OCCUPANCY_SNA" 3 "SEAT_NOT_CONFIGURED" 2 "SEAT_OCCUPANCY_FAULTED" 1 "SEAT_OCCUPIED" 0 "SEAT_UNOCCUPIED" ;
VAL_ 1863 VCLEFT_frontBuckleStatus 3 "SEAT_BELT_BUCKLE_NOT_CONFIGURED" 2 "SEAT_BELT_BUCKLE_STATUS_FAULTED" 1 "SEAT_BELT_BUCKLE_STATUS_LATCHED" 0 "SEAT_BELT_BUCKLE_STATUS_UNLATCHED" ;
VAL_ 1863 VCLEFT_rearLeftOccupancyStatus 3 "SEAT_NOT_CONFIGURED" 2 "SEAT_OCCUPANCY_FAULTED" 1 "SEAT_OCCUPIED" 0 "SEAT_UNOCCUPIED" ;
VAL_ 1863 VCLEFT_rearCenterOccupancyStatus 3 "SEAT_NOT_CONFIGURED" 2 "SEAT_OCCUPANCY_FAULTED" 1 "SEAT_OCCUPIED" 0 "SEAT_UNOCCUPIED" ;
VAL_ 1863 VCLEFT_rearRightOccupancyStatus 3 "SEAT_NOT_CONFIGURED" 2 "SEAT_OCCUPANCY_FAULTED" 1 "SEAT_OCCUPIED" 0 "SEAT_UNOCCUPIED" ;
VAL_ 1863 VCLEFT_rearLeftBuckleStatus 3 "SEAT_BELT_BUCKLE_NOT_CONFIGURED" 2 "SEAT_BELT_BUCKLE_STATUS_FAULTED" 1 "SEAT_BELT_BUCKLE_STATUS_LATCHED" 0 "SEAT_BELT_BUCKLE_STATUS_UNLATCHED" ;
VAL_ 1863 VCLEFT_rearCenterBuckleStatus 3 "SEAT_BELT_BUCKLE_NOT_CONFIGURED" 2 "SEAT_BELT_BUCKLE_STATUS_FAULTED" 1 "SEAT_BELT_BUCKLE_STATUS_LATCHED" 0 "SEAT_BELT_BUCKLE_STATUS_UNLATCHED" ;
VAL_ 1863 VCLEFT_seatTrackPosition 7 "SEAT_TRACK_POSITION_SNA" 3 "SEAT_TRACK_POSITION_FAULTED" 2 "SEAT_TRACK_POSITION_NOT_CONFIGURED" 1 "SEAT_TRACK_POSITION_REARWARD" 0 "SEAT_TRACK_POSITION_FORWARD" ;
VAL_ 1863 VCLEFT_3RowLeftABStatus 2 "AIRBAG_STATE_SNA" 1 "AIRBAG_SUPPRESS" 0 "AIRBAG_ALLOW" ;
VAL_ 1863 VCLEFT_3RowLeftBuckleStatus 3 "SEAT_BELT_BUCKLE_NOT_CONFIGURED" 2 "SEAT_BELT_BUCKLE_STATUS_FAULTED" 1 "SEAT_BELT_BUCKLE_STATUS_LATCHED" 0 "SEAT_BELT_BUCKLE_STATUS_UNLATCHED" ;
VAL_ 1250 VCLEFT_seatStatusIndex 7 "RELATIVE_POSITION" 6 "OFFSETS" 5 "POSITION" 4 "LUMBAR" 3 "TILT" 2 "LIFT" 1 "BACK" 0 "TRACK" ;
VAL_ 1250 VC_AH_1RowLeftSeatMovementHealth 4 "SEAT_CALIBRATION_REQUIRED" 3 "SEAT_IN_NON_USE_POSITION" 2 "SEAT_CANNOT_MOVE" 1 "SEAT_MOVEMENT_HEALTHY" 0 "SEAT_MOVEMENT_HEALTH_UNKNOWN" ;
VAL_ 1250 VCLEFT_frontSeatTrackState 5 "SEAT_STATE_UNDEFINED" 4 "SEAT_STATE_CALIBRATING" 3 "SEAT_STATE_RECALLING" 2 "SEAT_STATE_MOVING_DOWN" 1 "SEAT_STATE_MOVING_UP" 0 "SEAT_STATE_STOPPED" ;
VAL_ 1250 VCLEFT_frontSeatTrackBridgeSt 3 "IO_BRIDGE_STATE_COAST" 2 "IO_BRIDGE_STATE_BRAKE" 1 "IO_BRIDGE_STATE_ENABLED" 0 "IO_BRIDGE_STATE_DISABLED" ;
VAL_ 1250 VCLEFT_frontSeatBackState 5 "SEAT_STATE_UNDEFINED" 4 "SEAT_STATE_CALIBRATING" 3 "SEAT_STATE_RECALLING" 2 "SEAT_STATE_MOVING_DOWN" 1 "SEAT_STATE_MOVING_UP" 0 "SEAT_STATE_STOPPED" ;
VAL_ 1250 VCLEFT_frontSeatBackBridgeSt 3 "IO_BRIDGE_STATE_COAST" 2 "IO_BRIDGE_STATE_BRAKE" 1 "IO_BRIDGE_STATE_ENABLED" 0 "IO_BRIDGE_STATE_DISABLED" ;
VAL_ 1250 VCLEFT_frontSeatLiftState 5 "SEAT_STATE_UNDEFINED" 4 "SEAT_STATE_CALIBRATING" 3 "SEAT_STATE_RECALLING" 2 "SEAT_STATE_MOVING_DOWN" 1 "SEAT_STATE_MOVING_UP" 0 "SEAT_STATE_STOPPED" ;
VAL_ 1250 VCLEFT_frontSeatLiftBridgeSt 3 "IO_BRIDGE_STATE_COAST" 2 "IO_BRIDGE_STATE_BRAKE" 1 "IO_BRIDGE_STATE_ENABLED" 0 "IO_BRIDGE_STATE_DISABLED" ;
VAL_ 1250 VCLEFT_frontSeatTiltState 5 "SEAT_STATE_UNDEFINED" 4 "SEAT_STATE_CALIBRATING" 3 "SEAT_STATE_RECALLING" 2 "SEAT_STATE_MOVING_DOWN" 1 "SEAT_STATE_MOVING_UP" 0 "SEAT_STATE_STOPPED" ;
VAL_ 1250 VCLEFT_frontSeatTiltBridgeSt 3 "IO_BRIDGE_STATE_COAST" 2 "IO_BRIDGE_STATE_BRAKE" 1 "IO_BRIDGE_STATE_ENABLED" 0 "IO_BRIDGE_STATE_DISABLED" ;
VAL_ 1250 VCLEFT_lumbarAState 5 "SEAT_STATE_UNDEFINED" 4 "SEAT_STATE_CALIBRATING" 3 "SEAT_STATE_RECALLING" 2 "SEAT_STATE_MOVING_DOWN" 1 "SEAT_STATE_MOVING_UP" 0 "SEAT_STATE_STOPPED" ;
VAL_ 1250 VCLEFT_lumbarBState 5 "SEAT_STATE_UNDEFINED" 4 "SEAT_STATE_CALIBRATING" 3 "SEAT_STATE_RECALLING" 2 "SEAT_STATE_MOVING_DOWN" 1 "SEAT_STATE_MOVING_UP" 0 "SEAT_STATE_STOPPED" ;
VAL_ 738 VCLEFT_seatStatus2Index 15 "SEAT_HEAT_3R_RIGHT_CUSHION" 14 "SEAT_3ROW_ADJUSTABLE_FOLD_FLAT" 13 "FRONT_SEAT_THIGH_SUPPORT" 12 "SEAT_2ROW_ADJUSTABLE_FOLD_FLAT_2" 11 "SEAT_2ROW_ADJUSTABLE_FOLD_FLAT" 10 "SEAT_HEAT_3R_LEFT" 9 "SEAT_2ROW_EASY_ENTRY" 8 "SEAT_SWITCH_VOLTAGES_2" 7 "SEAT_SWITCH_VOLTAGES_1" 6 "SEAT_2ROW_ACTUATOR" 5 "SEAT_HEAT_REARR_CUSHION" 4 "SEAT_HEAT_REARC" 3 "SEAT_HEAT_REARL" 2 "OCCUPANCY" 1 "SEAT_HEAT_REARL_BACKREST" 0 "SEAT_HEAT_FRONT" ;
VAL_ 738 VCLEFT_frontSeatHeatCurrent 12 "SNA" ;
VAL_ 738 VCLEFT_2RowSeatFoldLeftSwitch 3 "SWITCH_FAULT" 2 "SWITCH_ON" 1 "SWITCH_OFF" 0 "SWITCH_SNA" ;
VAL_ 738 VCLEFT_2RowSeatUnfoldLeftSwitch 3 "SWITCH_FAULT" 2 "SWITCH_ON" 1 "SWITCH_OFF" 0 "SWITCH_SNA" ;
VAL_ 738 VCLEFT_2RowSeatFoldRightSwitch 3 "SWITCH_FAULT" 2 "SWITCH_ON" 1 "SWITCH_OFF" 0 "SWITCH_SNA" ;
VAL_ 738 VCLEFT_2RowSeatUnfoldRightSwitch 3 "SWITCH_FAULT" 2 "SWITCH_ON" 1 "SWITCH_OFF" 0 "SWITCH_SNA" ;
VAL_ 738 VCLEFT_3RowSeatFoldLeftSwitch 3 "SWITCH_FAULT" 2 "SWITCH_ON" 1 "SWITCH_OFF" 0 "SWITCH_SNA" ;
VAL_ 738 VCLEFT_3RowSeatUnfoldLeftSwitch 3 "SWITCH_FAULT" 2 "SWITCH_ON" 1 "SWITCH_OFF" 0 "SWITCH_SNA" ;
VAL_ 738 VCLEFT_3RowSeatFoldRightSwitch 3 "SWITCH_FAULT" 2 "SWITCH_ON" 1 "SWITCH_OFF" 0 "SWITCH_SNA" ;
VAL_ 738 VCLEFT_3RowSeatUnfoldRightSwitch 3 "SWITCH_FAULT" 2 "SWITCH_ON" 1 "SWITCH_OFF" 0 "SWITCH_SNA" ;
VAL_ 738 VC_AH_1RowLeftSeatHeatVentHealth 2 "SEAT_HEAT_VENT_UNAVAILABLE" 1 "SEAT_HEAT_VENT_HEALTHY" 0 "SEAT_HEAT_VENT_HEALTH_UNKNOWN" ;
VAL_ 738 VCLEFT_2RowSeatReclineState 15 "SEAT_ADJUSTABLE_FOLD_FLAT_STATE_SNA" 12 "SEAT_ADJUSTABLE_FOLD_FLAT_STATE_CALIBRATING_ABSOLUTE_SENSOR" 11 "SEAT_ADJUSTABLE_FOLD_FLAT_STATE_CALIBRATING_ZERO_POSITION" 10 "SEAT_ADJUSTABLE_FOLD_FLAT_STATE_WAITING_TO_CLEAR_FOR_UNFOLD" 9 "SEAT_ADJUSTABLE_FOLD_FLAT_STATE_WAITING_TO_CLEAR_FOR_FOLD" 8 "SEAT_ADJUSTABLE_FOLD_FLAT_STATE_MOVING_REARWARD_TO_POSITION" 7 "SEAT_ADJUSTABLE_FOLD_FLAT_STATE_MOVING_FORWARD_TO_POSITION" 6 "SEAT_ADJUSTABLE_FOLD_FLAT_STATE_UNFOLDING" 5 "SEAT_ADJUSTABLE_FOLD_FLAT_STATE_FOLDING" 4 "SEAT_ADJUSTABLE_FOLD_FLAT_STATE_ADJUSTING_REARWARD_FAST" 3 "SEAT_ADJUSTABLE_FOLD_FLAT_STATE_ADJUSTING_FORWARD_FAST" 2 "SEAT_ADJUSTABLE_FOLD_FLAT_STATE_ADJUSTING_REARWARD_COMFORT" 1 "SEAT_ADJUSTABLE_FOLD_FLAT_STATE_ADJUSTING_FORWARD_COMFORT" 0 "SEAT_ADJUSTABLE_FOLD_FLAT_STATE_STOPPED" ;
VAL_ 738 VCLEFT_2RowSeatReclineAbsPosSwit 3 "SWITCH_FAULT" 2 "SWITCH_ON" 1 "SWITCH_OFF" 0 "SWITCH_SNA" ;
VAL_ 738 VCLEFT_2RowSeatReclinePositionSt 4 "SEAT_ADJUSTABLE_FOLD_FLAT_POSITION_STATE_SNA" 3 "SEAT_ADJUSTABLE_FOLD_FLAT_POSITION_STATE_UNKNOWN" 2 "SEAT_ADJUSTABLE_FOLD_FLAT_POSITION_STATE_UNSAFE_INTERMEDIATE" 1 "SEAT_ADJUSTABLE_FOLD_FLAT_POSITION_STATE_UNFOLDED" 0 "SEAT_ADJUSTABLE_FOLD_FLAT_POSITION_STATE_FOLDED" ;
VAL_ 738 VCLEFT_2RowSeatReclineNextToggle 2 "SEAT_ADJUSTABLE_FOLD_FLAT_NEXT_TOGGLE_DIRECTION_SNA" 1 "SEAT_ADJUSTABLE_FOLD_FLAT_NEXT_TOGGLE_DIRECTION_UNFOLD" 0 "SEAT_ADJUSTABLE_FOLD_FLAT_NEXT_TOGGLE_DIRECTION_FOLD" ;
VAL_ 738 VCLEFT_2RowSeat1RClashAvoidanceB 6 "SEAT_FOLD_FLAT_CLASH_AVOIDANCE_REASON_FRONT_SEAT_OCCUPANCY" 5 "SEAT_FOLD_FLAT_CLASH_AVOIDANCE_REASON_FRONT_SEAT_MOVING" 4 "SEAT_FOLD_FLAT_CLASH_AVOIDANCE_REASON_FRONT_SEAT_PROFILE_RECALL" 3 "SEAT_FOLD_FLAT_CLASH_AVOIDANCE_REASON_REAR_SEAT_UNCALIBRATED" 2 "SEAT_FOLD_FLAT_CLASH_AVOIDANCE_REASON_FRONT_SEAT_UNCALIBRATED" 1 "SEAT_FOLD_FLAT_CLASH_AVOIDANCE_REASON_VEHICLE_IN_MOTION" 0 "SEAT_FOLD_FLAT_CLASH_AVOIDANCE_REASON_NONE" ;
VAL_ 738 VCLEFT_2RowSeat1RClashAvoidanceS 3 "SEAT_FOLD_FLAT_CLASH_AVOIDANCE_STATE_RESTORING_FRONT_SEAT" 2 "SEAT_FOLD_FLAT_CLASH_AVOIDANCE_STATE_WAITING_TO_RESTORE_FRONT_SEAT" 1 "SEAT_FOLD_FLAT_CLASH_AVOIDANCE_STATE_FRONT_SEAT_CLEARING" 0 "SEAT_FOLD_FLAT_CLASH_AVOIDANCE_STATE_IDLE" ;
VAL_ 738 VC_AH_2RowLeftSeatMovementHealth 4 "SEAT_CALIBRATION_REQUIRED" 3 "SEAT_IN_NON_USE_POSITION" 2 "SEAT_CANNOT_MOVE" 1 "SEAT_MOVEMENT_HEALTHY" 0 "SEAT_MOVEMENT_HEALTH_UNKNOWN" ;
VAL_ 738 VCLEFT_3RowSeatReclineState 15 "SEAT_ADJUSTABLE_FOLD_FLAT_STATE_SNA" 12 "SEAT_ADJUSTABLE_FOLD_FLAT_STATE_CALIBRATING_ABSOLUTE_SENSOR" 11 "SEAT_ADJUSTABLE_FOLD_FLAT_STATE_CALIBRATING_ZERO_POSITION" 10 "SEAT_ADJUSTABLE_FOLD_FLAT_STATE_WAITING_TO_CLEAR_FOR_UNFOLD" 9 "SEAT_ADJUSTABLE_FOLD_FLAT_STATE_WAITING_TO_CLEAR_FOR_FOLD" 8 "SEAT_ADJUSTABLE_FOLD_FLAT_STATE_MOVING_REARWARD_TO_POSITION" 7 "SEAT_ADJUSTABLE_FOLD_FLAT_STATE_MOVING_FORWARD_TO_POSITION" 6 "SEAT_ADJUSTABLE_FOLD_FLAT_STATE_UNFOLDING" 5 "SEAT_ADJUSTABLE_FOLD_FLAT_STATE_FOLDING" 4 "SEAT_ADJUSTABLE_FOLD_FLAT_STATE_ADJUSTING_REARWARD_FAST" 3 "SEAT_ADJUSTABLE_FOLD_FLAT_STATE_ADJUSTING_FORWARD_FAST" 2 "SEAT_ADJUSTABLE_FOLD_FLAT_STATE_ADJUSTING_REARWARD_COMFORT" 1 "SEAT_ADJUSTABLE_FOLD_FLAT_STATE_ADJUSTING_FORWARD_COMFORT" 0 "SEAT_ADJUSTABLE_FOLD_FLAT_STATE_STOPPED" ;
VAL_ 738 VCLEFT_3RowSeatReclineNextToggle 2 "SEAT_ADJUSTABLE_FOLD_FLAT_NEXT_TOGGLE_DIRECTION_SNA" 1 "SEAT_ADJUSTABLE_FOLD_FLAT_NEXT_TOGGLE_DIRECTION_UNFOLD" 0 "SEAT_ADJUSTABLE_FOLD_FLAT_NEXT_TOGGLE_DIRECTION_FOLD" ;
VAL_ 738 VCLEFT_3RowSeatReclinePositionSt 4 "SEAT_ADJUSTABLE_FOLD_FLAT_POSITION_STATE_SNA" 3 "SEAT_ADJUSTABLE_FOLD_FLAT_POSITION_STATE_UNKNOWN" 2 "SEAT_ADJUSTABLE_FOLD_FLAT_POSITION_STATE_UNSAFE_INTERMEDIATE" 1 "SEAT_ADJUSTABLE_FOLD_FLAT_POSITION_STATE_UNFOLDED" 0 "SEAT_ADJUSTABLE_FOLD_FLAT_POSITION_STATE_FOLDED" ;
VAL_ 738 VCLEFT_3RowSeatReclineAbsPosSwit 3 "SWITCH_FAULT" 2 "SWITCH_ON" 1 "SWITCH_OFF" 0 "SWITCH_SNA" ;
VAL_ 930 VCLEFT_statusIndex 2 "MUX2" 1 "MUX1" 0 "MUX0" ;
VAL_ 930 VCLEFT_swcInputVoltage 255 "SNA" ;
VAL_ 930 VCLEFT_swcPCBATemperature -128 "SNA" ;
VAL_ 930 VCLEFT_LVBatteryTypeDBG 5 "LV_BATTERY_TYPE_TESLA_48V_LI_ION" 4 "LV_BATTERY_TYPE_TESLA_16V_LI_ION" 3 "LV_BATTERY_TYPE_CATL_LI_ION" 2 "LV_BATTERY_TYPE_CLARIOS_B24_FLOODED" 1 "LV_BATTERY_TYPE_ATLASBX_B24_FLOODED" 0 "LV_BATTERY_TYPE_UNKNOWN" ;
VAL_ 930 VCLEFT_trailerAuxCurrent 4095 "SNA" ;
VAL_ 930 VCLEFT_swcHeatTmp 1023 "SNA" ;
VAL_ 930 VCLEFT_swcHeatStatus 4 "HEATER_STATE_FAULT" 3 "HEATER_STATE_OFF_UNAVAILABLE" 2 "HEATER_STATE_OFF" 1 "HEATER_STATE_ON" 0 "HEATER_STATE_SNA" ;
VAL_ 930 VCLEFT_swcHeatPwr 511 "SNA" ;
VAL_ 930 VCLEFT_swcHeatDutyCycle 127 "SNA" ;
VAL_ 930 VCLEFT_autonomyBehaviorStatus 2 "DRIVERLESS_NO_TAKEOVER" 1 "DRIVERLESS_TAKEOVER" 0 "DRIVER" ;
VAL_ 930 VCLEFT_thirdRowLeftMapLightStatu 3 "LIGHT_SNA" 2 "LIGHT_FAULT" 1 "LIGHT_ON" 0 "LIGHT_OFF" ;
VAL_ 930 VCLEFT_thirdRowRightMapLightStat 3 "LIGHT_SNA" 2 "LIGHT_FAULT" 1 "LIGHT_ON" 0 "LIGHT_OFF" ;
VAL_ 610 VCLEFT_steeringColumnSMState 3 "STEERING_COLUMN_STATE_MANUAL_CONTROL" 2 "STEERING_COLUMN_STATE_CALIBRATE" 1 "STEERING_COLUMN_STATE_RECALL" 0 "STEERING_COLUMN_STATE_SNA" ;
VAL_ 610 VCLEFT_steeringColumnLastRequest 5 "STEERING_COLUMN_REQUEST_OUT" 4 "STEERING_COLUMN_REQUEST_IN" 3 "STEERING_COLUMN_REQUEST_DOWN" 2 "STEERING_COLUMN_REQUEST_UP" 1 "STEERING_COLUMN_REQUEST_NONE" 0 "STEERING_COLUMN_REQUEST_SNA" ;
VAL_ 962 VCLEFT_switchStatusIndex 1 "1" 0 "0" ;
VAL_ 962 VCLEFT_rightMirrorTilt 4 "MIRROR_TILT_LEFT" 3 "MIRROR_TILT_RIGHT" 2 "MIRROR_TILT_UP" 1 "MIRROR_TILT_DOWN" 0 "MIRROR_TILT_STOP" ;
VAL_ 962 VCLEFT_frontSeatTrackBack 3 "SWITCH_FAULT" 2 "SWITCH_ON" 1 "SWITCH_OFF" 0 "SWITCH_SNA" ;
VAL_ 962 VCLEFT_frontSeatTrackForward 3 "SWITCH_FAULT" 2 "SWITCH_ON" 1 "SWITCH_OFF" 0 "SWITCH_SNA" ;
VAL_ 962 VCLEFT_frontSeatTiltDown 3 "SWITCH_FAULT" 2 "SWITCH_ON" 1 "SWITCH_OFF" 0 "SWITCH_SNA" ;
VAL_ 962 VCLEFT_frontSeatTiltUp 3 "SWITCH_FAULT" 2 "SWITCH_ON" 1 "SWITCH_OFF" 0 "SWITCH_SNA" ;
VAL_ 962 VCLEFT_frontSeatLiftDown 3 "SWITCH_FAULT" 2 "SWITCH_ON" 1 "SWITCH_OFF" 0 "SWITCH_SNA" ;
VAL_ 962 VCLEFT_frontSeatLiftUp 3 "SWITCH_FAULT" 2 "SWITCH_ON" 1 "SWITCH_OFF" 0 "SWITCH_SNA" ;
VAL_ 962 VCLEFT_frontSeatBackrestBack 3 "SWITCH_FAULT" 2 "SWITCH_ON" 1 "SWITCH_OFF" 0 "SWITCH_SNA" ;
VAL_ 962 VCLEFT_frontSeatBackrestForward 3 "SWITCH_FAULT" 2 "SWITCH_ON" 1 "SWITCH_OFF" 0 "SWITCH_SNA" ;
VAL_ 962 VCLEFT_frontSeatLumbarDown 3 "SWITCH_FAULT" 2 "SWITCH_ON" 1 "SWITCH_OFF" 0 "SWITCH_SNA" ;
VAL_ 962 VCLEFT_frontSeatLumbarUp 3 "SWITCH_FAULT" 2 "SWITCH_ON" 1 "SWITCH_OFF" 0 "SWITCH_SNA" ;
VAL_ 962 VCLEFT_frontSeatLumbarIn 3 "SWITCH_FAULT" 2 "SWITCH_ON" 1 "SWITCH_OFF" 0 "SWITCH_SNA" ;
VAL_ 962 VCLEFT_frontSeatLumbarOut 3 "SWITCH_FAULT" 2 "SWITCH_ON" 1 "SWITCH_OFF" 0 "SWITCH_SNA" ;
VAL_ 962 VCLEFT_frontBuckleSwitch 3 "SWITCH_FAULT" 2 "SWITCH_ON" 1 "SWITCH_OFF" 0 "SWITCH_SNA" ;
VAL_ 962 VCLEFT_frontOccupancySwitch 3 "SWITCH_FAULT" 2 "SWITCH_ON" 1 "SWITCH_OFF" 0 "SWITCH_SNA" ;
VAL_ 962 VCLEFT_rearLeftBuckleSwitch 3 "SWITCH_FAULT" 2 "SWITCH_ON" 1 "SWITCH_OFF" 0 "SWITCH_SNA" ;
VAL_ 962 VCLEFT_rearCenterOccupancySwitch 3 "SWITCH_FAULT" 2 "SWITCH_ON" 1 "SWITCH_OFF" 0 "SWITCH_SNA" ;
VAL_ 962 VCLEFT_rearLeftOccupancySwitch 3 "SWITCH_FAULT" 2 "SWITCH_ON" 1 "SWITCH_OFF" 0 "SWITCH_SNA" ;
VAL_ 962 VCLEFT_rearRightOccupancySwitch 3 "SWITCH_FAULT" 2 "SWITCH_ON" 1 "SWITCH_OFF" 0 "SWITCH_SNA" ;
VAL_ 962 VCLEFT_rearCenterBuckleSwitch 3 "SWITCH_FAULT" 2 "SWITCH_ON" 1 "SWITCH_OFF" 0 "SWITCH_SNA" ;
VAL_ 962 VCLEFT_swcLeftTiltRight 3 "SWITCH_FAULT" 2 "SWITCH_ON" 1 "SWITCH_OFF" 0 "SWITCH_SNA" ;
VAL_ 962 VCLEFT_swcLeftPressed 3 "SWITCH_FAULT" 2 "SWITCH_ON" 1 "SWITCH_OFF" 0 "SWITCH_SNA" ;
VAL_ 962 VCLEFT_swcRightTiltLeft 3 "SWITCH_FAULT" 2 "SWITCH_ON" 1 "SWITCH_OFF" 0 "SWITCH_SNA" ;
VAL_ 962 VCLEFT_swcRightTiltRight 3 "SWITCH_FAULT" 2 "SWITCH_ON" 1 "SWITCH_OFF" 0 "SWITCH_SNA" ;
VAL_ 962 VCLEFT_swcRightPressed 3 "SWITCH_FAULT" 2 "SWITCH_ON" 1 "SWITCH_OFF" 0 "SWITCH_SNA" ;
VAL_ 962 VCLEFT_swcLeftTiltLeft 3 "SWITCH_FAULT" 2 "SWITCH_ON" 1 "SWITCH_OFF" 0 "SWITCH_SNA" ;
VAL_ 962 VCLEFT_swcWiperButtonState 3 "FAULT" 2 "HARD_PRESS" 1 "SOFT_PRESS" 0 "INACTIVE" ;
VAL_ 962 VCLEFT_swcTurnSignalLeftButtonSt 3 "FAULT" 2 "HARD_PRESS" 1 "SOFT_PRESS" 0 "INACTIVE" ;
VAL_ 962 VCLEFT_swcTurnSignalRightButtonS 3 "FAULT" 2 "HARD_PRESS" 1 "SOFT_PRESS" 0 "INACTIVE" ;
VAL_ 962 VCLEFT_swcHighBeamButtonState 3 "FAULT" 2 "HARD_PRESS" 1 "SOFT_PRESS" 0 "INACTIVE" ;
VAL_ 962 VCLEFT_swcVoiceControlPress 3 "SWITCH_FAULT" 2 "SWITCH_ON" 1 "SWITCH_OFF" 0 "SWITCH_SNA" ;
VAL_ 962 VCLEFT_swcCameraButtonState 3 "FAULT" 2 "HARD_PRESS" 1 "SOFT_PRESS" 0 "INACTIVE" ;
VAL_ 962 VCLEFT_swcRightPressedQF 1 "VALID" 0 "INVALID" ;
VAL_ 962 VCLEFT_2RowSeatReclineSwitchpack 6 "FAULT" 5 "REARWARD_FAST" 4 "REARWARD_SLOW" 3 "FORWARD_FAST" 2 "FORWARD_SLOW" 1 "INACTIVE" 0 "DISCONNECTED" ;
VAL_ 962 VCLEFT_3RowLeftBuckleSwitch 3 "SWITCH_FAULT" 2 "SWITCH_ON" 1 "SWITCH_OFF" 0 "SWITCH_SNA" ;
VAL_ 962 VCLEFT_frontSeatThighSupportExte 3 "SWITCH_FAULT" 2 "SWITCH_ON" 1 "SWITCH_OFF" 0 "SWITCH_SNA" ;
VAL_ 962 VCLEFT_frontSeatThighSupportRetr 3 "SWITCH_FAULT" 2 "SWITCH_ON" 1 "SWITCH_OFF" 0 "SWITCH_SNA" ;
VAL_ 962 VCLEFT_frontSeatResistiveOccupan 3 "SWITCH_FAULT" 2 "SWITCH_ON" 1 "SWITCH_OFF" 0 "SWITCH_SNA" ;
VAL_ 656 VCLEFT_thermalLogging10HzIndex 5 "END" 4 "2R_HVAC_DUTY" 3 "MISC" 2 "2R_HVAC_VOLTAGE_AND_STATUS" 1 "HVAC_VARS2" 0 "HVAC_VARS" ;
VAL_ 656 VCLEFT_hvac2RLeftLateralCalibrat 1 "CALIBRATED" 0 "NOT_CALIBRATED" ;
VAL_ 656 VCLEFT_hvac2RLeftVerticalCalibra 1 "CALIBRATED" 0 "NOT_CALIBRATED" ;
VAL_ 656 VCLEFT_hvac2RRightLateralCalibra 1 "CALIBRATED" 0 "NOT_CALIBRATED" ;
VAL_ 656 VCLEFT_hvac2RRightVerticalCalibr 1 "CALIBRATED" 0 "NOT_CALIBRATED" ;
VAL_ 656 VCLEFT_hvac2RLeftLateralState 11 "HVAC_ACTUATOR_BRUSHED_STATE_RUNNING_OVERSHOOT" 10 "HVAC_ACTUATOR_BRUSHED_STATE_NEGATIVE_BACKOFF" 9 "HVAC_ACTUATOR_BRUSHED_STATE_POSITIVE_BACKOFF" 8 "HVAC_ACTUATOR_BRUSHED_STATE_CONTROL_DISABLED" 7 "HVAC_ACTUATOR_BRUSHED_STATE_FAULT" 6 "HVAC_ACTUATOR_BRUSHED_STATE_BRAKING" 5 "HVAC_ACTUATOR_BRUSHED_STATE_RUNNING" 4 "HVAC_ACTUATOR_BRUSHED_STATE_NEGATIVE_STALL" 3 "HVAC_ACTUATOR_BRUSHED_STATE_NEGATIVE_RUN" 2 "HVAC_ACTUATOR_BRUSHED_STATE_POSITIVE_STALL" 1 "HVAC_ACTUATOR_BRUSHED_STATE_POSITIVE_RUN" 0 "HVAC_ACTUATOR_BRUSHED_STATE_INIT" ;
VAL_ 656 VCLEFT_hvac2RLeftVerticalState 11 "HVAC_ACTUATOR_BRUSHED_STATE_RUNNING_OVERSHOOT" 10 "HVAC_ACTUATOR_BRUSHED_STATE_NEGATIVE_BACKOFF" 9 "HVAC_ACTUATOR_BRUSHED_STATE_POSITIVE_BACKOFF" 8 "HVAC_ACTUATOR_BRUSHED_STATE_CONTROL_DISABLED" 7 "HVAC_ACTUATOR_BRUSHED_STATE_FAULT" 6 "HVAC_ACTUATOR_BRUSHED_STATE_BRAKING" 5 "HVAC_ACTUATOR_BRUSHED_STATE_RUNNING" 4 "HVAC_ACTUATOR_BRUSHED_STATE_NEGATIVE_STALL" 3 "HVAC_ACTUATOR_BRUSHED_STATE_NEGATIVE_RUN" 2 "HVAC_ACTUATOR_BRUSHED_STATE_POSITIVE_STALL" 1 "HVAC_ACTUATOR_BRUSHED_STATE_POSITIVE_RUN" 0 "HVAC_ACTUATOR_BRUSHED_STATE_INIT" ;
VAL_ 656 VCLEFT_hvac2RRightLateralState 11 "HVAC_ACTUATOR_BRUSHED_STATE_RUNNING_OVERSHOOT" 10 "HVAC_ACTUATOR_BRUSHED_STATE_NEGATIVE_BACKOFF" 9 "HVAC_ACTUATOR_BRUSHED_STATE_POSITIVE_BACKOFF" 8 "HVAC_ACTUATOR_BRUSHED_STATE_CONTROL_DISABLED" 7 "HVAC_ACTUATOR_BRUSHED_STATE_FAULT" 6 "HVAC_ACTUATOR_BRUSHED_STATE_BRAKING" 5 "HVAC_ACTUATOR_BRUSHED_STATE_RUNNING" 4 "HVAC_ACTUATOR_BRUSHED_STATE_NEGATIVE_STALL" 3 "HVAC_ACTUATOR_BRUSHED_STATE_NEGATIVE_RUN" 2 "HVAC_ACTUATOR_BRUSHED_STATE_POSITIVE_STALL" 1 "HVAC_ACTUATOR_BRUSHED_STATE_POSITIVE_RUN" 0 "HVAC_ACTUATOR_BRUSHED_STATE_INIT" ;
VAL_ 656 VCLEFT_hvac2RRightVerticalState 11 "HVAC_ACTUATOR_BRUSHED_STATE_RUNNING_OVERSHOOT" 10 "HVAC_ACTUATOR_BRUSHED_STATE_NEGATIVE_BACKOFF" 9 "HVAC_ACTUATOR_BRUSHED_STATE_POSITIVE_BACKOFF" 8 "HVAC_ACTUATOR_BRUSHED_STATE_CONTROL_DISABLED" 7 "HVAC_ACTUATOR_BRUSHED_STATE_FAULT" 6 "HVAC_ACTUATOR_BRUSHED_STATE_BRAKING" 5 "HVAC_ACTUATOR_BRUSHED_STATE_RUNNING" 4 "HVAC_ACTUATOR_BRUSHED_STATE_NEGATIVE_STALL" 3 "HVAC_ACTUATOR_BRUSHED_STATE_NEGATIVE_RUN" 2 "HVAC_ACTUATOR_BRUSHED_STATE_POSITIVE_STALL" 1 "HVAC_ACTUATOR_BRUSHED_STATE_POSITIVE_RUN" 0 "HVAC_ACTUATOR_BRUSHED_STATE_INIT" ;
VAL_ 656 VCLEFT_vcusbLinSchedule 3 "VCUSB_LIN_SCHEDULE_COUNT" 2 "VCUSB_LIN_SCHEDULE_DIAGNOSTIC" 1 "VCUSB_LIN_SCHEDULE_COMMAND_AND_RESPONSE" 0 "VCUSB_LIN_SCHEDULE_OFF" ;
VAL_ 656 VCLEFT_hvacBlowerArbState 6 "ARBITRATOR_FAULTED" 5 "ARBITRATOR_COMPLETED" 4 "ARBITRATOR_REQUEST_CURRENT" 3 "ARBITRATOR_WAIT_BEFORE_REQUEST" 2 "ARBITRATOR_HIGH_FREQ_VOLT_INJECTION" 1 "ARBITRATOR_READY" 0 "ARBITRATOR_NOT_READY" ;
VAL_ 656 VCLEFT_hvacBlowerArbResult 2 "VC_MOTOR_ID_BOSCH" 1 "VC_MOTOR_ID_DELTA" 0 "VC_MOTOR_ID_UNKNOWN" ;
VAL_ 657 VCLEFT_thermalLogging1HzIndex 15 "MAX" 2 "END" 1 "ENDSTOP" 0 "ZEROSTOP" ;
VAL_ 706 VCLEFT_windowStatusIndex 1 "Mux1" 0 "Mux0" ;
VAL_ 706 VCLEFT_windowStateLF 10 "WINDOW_STATE_SHORT_RISE_REVERSE" 9 "WINDOW_STATE_SHORT_RISE" 8 "WINDOW_STATE_BACKDRIVE" 7 "WINDOW_STATE_MOVING_AUTO_DOWN" 6 "WINDOW_STATE_MOVING_AUTO_UP" 5 "WINDOW_STATE_SHORT_DROP_REVERSE" 4 "WINDOW_STATE_SHORT_DROP" 3 "WINDOW_STATE_BACKOFF" 2 "WINDOW_STATE_MOVING_DOWN" 1 "WINDOW_STATE_MOVING_UP" 0 "WINDOW_STATE_STOPPED" ;
VAL_ 706 VCLEFT_windowTrimClearMoveReques 3 "WINDOW_TRIM_CLEAR_MOVE_REQUEST_BACKDRIVE" 2 "WINDOW_TRIM_CLEAR_MOVE_REQUEST_RESEAL" 1 "WINDOW_TRIM_CLEAR_MOVE_REQUEST_IDLE" 0 "WINDOW_TRIM_CLEAR_MOVE_REQUEST_SNA" ;
VAL_ 706 VCLEFT_windowTrimClearActiveRequ 2 "WINDOW_TRIM_CLEAR_ACTIVE_REQUEST_ACTIVE" 1 "WINDOW_TRIM_CLEAR_ACTIVE_REQUEST_INACTIVE" 0 "WINDOW_TRIM_CLEAR_ACTIVE_REQUEST_SNA" ;
VAL_ 706 VCLEFT_windowPositionLF 1 "SNA" ;
VAL_ 706 VCLEFT_windowStateLR 10 "WINDOW_STATE_SHORT_RISE_REVERSE" 9 "WINDOW_STATE_SHORT_RISE" 8 "WINDOW_STATE_BACKDRIVE" 7 "WINDOW_STATE_MOVING_AUTO_DOWN" 6 "WINDOW_STATE_MOVING_AUTO_UP" 5 "WINDOW_STATE_SHORT_DROP_REVERSE" 4 "WINDOW_STATE_SHORT_DROP" 3 "WINDOW_STATE_BACKOFF" 2 "WINDOW_STATE_MOVING_DOWN" 1 "WINDOW_STATE_MOVING_UP" 0 "WINDOW_STATE_STOPPED" ;
VAL_ 706 VCLEFT_windowThermalModeLF 3 "WINDOW_THERMAL_MODE_CRITICAL" 2 "WINDOW_THERMAL_MODE_ALERT" 1 "WINDOW_THERMAL_MODE_NORMAL" 0 "WINDOW_THERMAL_MODE_SNA" ;
VAL_ 706 VCLEFT_windowStopReasonLF 6 "WINDOW_STOP_REASON_STATE_TIMEOUT" 5 "WINDOW_STOP_REASON_FULL_OPEN_SOFT_STOP" 4 "WINDOW_STOP_REASON_STOP_REQUEST" 3 "WINDOW_STOP_REASON_TARGET_REACHED" 2 "WINDOW_STOP_REASON_NEW_REQUEST" 1 "WINDOW_STOP_REASON_DOOR_OPEN_TRIM_PROTECT" 0 "WINDOW_STOP_REASON_NONE" ;
VAL_ 706 VCLEFT_windowStopReqReasonLF 8 "WINDOW_STOP_REQUEST_REASON_EXTERNAL_REQUEST" 7 "WINDOW_STOP_REQUEST_REASON_FULL_OPEN_SOFT_STOP" 6 "WINDOW_STOP_REQUEST_REASON_STATE_TIMEOUT" 5 "WINDOW_STOP_REQUEST_REASON_STALL" 4 "WINDOW_STOP_REQUEST_REASON_THERMAL" 3 "WINDOW_STOP_REQUEST_REASON_REAR_LOCKOUT" 2 "WINDOW_STOP_REQUEST_REASON_SWITCH_RELEASED" 1 "WINDOW_STOP_REQUEST_REASON_SWITCH_CANCEL_AUTO_MOVEMENT" 0 "WINDOW_STOP_REQUEST_REASON_NONE" ;
VAL_ 706 VCLEFT_windowThermalModeLR 3 "WINDOW_THERMAL_MODE_CRITICAL" 2 "WINDOW_THERMAL_MODE_ALERT" 1 "WINDOW_THERMAL_MODE_NORMAL" 0 "WINDOW_THERMAL_MODE_SNA" ;
VAL_ 706 VCLEFT_windowStopReasonLR 6 "WINDOW_STOP_REASON_STATE_TIMEOUT" 5 "WINDOW_STOP_REASON_FULL_OPEN_SOFT_STOP" 4 "WINDOW_STOP_REASON_STOP_REQUEST" 3 "WINDOW_STOP_REASON_TARGET_REACHED" 2 "WINDOW_STOP_REASON_NEW_REQUEST" 1 "WINDOW_STOP_REASON_DOOR_OPEN_TRIM_PROTECT" 0 "WINDOW_STOP_REASON_NONE" ;
VAL_ 706 VCLEFT_windowStopReqReasonLR 8 "WINDOW_STOP_REQUEST_REASON_EXTERNAL_REQUEST" 7 "WINDOW_STOP_REQUEST_REASON_FULL_OPEN_SOFT_STOP" 6 "WINDOW_STOP_REQUEST_REASON_STATE_TIMEOUT" 5 "WINDOW_STOP_REQUEST_REASON_STALL" 4 "WINDOW_STOP_REQUEST_REASON_THERMAL" 3 "WINDOW_STOP_REQUEST_REASON_REAR_LOCKOUT" 2 "WINDOW_STOP_REQUEST_REASON_SWITCH_RELEASED" 1 "WINDOW_STOP_REQUEST_REASON_SWITCH_CANCEL_AUTO_MOVEMENT" 0 "WINDOW_STOP_REQUEST_REASON_NONE" ;
VAL_ 706 VCLEFT_windowControlStateLF 2 "WINDOW_CONTROL_STATE_GOING_TO_POSITION" 1 "WINDOW_CONTROL_STATE_CLOSING" 0 "WINDOW_CONTROL_STATE_IDLE" ;
VAL_ 706 VCLEFT_windowCtrlUnavailableLF 7 "WINDOW_CONTROL_UNAVAILABLE_REASON_WINDOW_MOVING" 6 "WINDOW_CONTROL_UNAVAILABLE_REASON_VEHICLE_IN_DRIVE" 5 "WINDOW_CONTROL_UNAVAILABLE_REASON_UNCALIBRATED" 4 "WINDOW_CONTROL_UNAVAILABLE_REASON_THERMAL_LIMIT" 3 "WINDOW_CONTROL_UNAVAILABLE_REASON_PINCH" 2 "WINDOW_CONTROL_UNAVAILABLE_REASON_SWITCH_PRESSED" 1 "WINDOW_CONTROL_UNAVAILABLE_REASON_UNEXPECTED" 0 "WINDOW_CONTROL_UNAVAILABLE_REASON_NONE" ;
VAL_ 706 VCLEFT_windowControlStateLR 2 "WINDOW_CONTROL_STATE_GOING_TO_POSITION" 1 "WINDOW_CONTROL_STATE_CLOSING" 0 "WINDOW_CONTROL_STATE_IDLE" ;
VAL_ 706 VCLEFT_windowCtrlUnavailableLR 7 "WINDOW_CONTROL_UNAVAILABLE_REASON_WINDOW_MOVING" 6 "WINDOW_CONTROL_UNAVAILABLE_REASON_VEHICLE_IN_DRIVE" 5 "WINDOW_CONTROL_UNAVAILABLE_REASON_UNCALIBRATED" 4 "WINDOW_CONTROL_UNAVAILABLE_REASON_THERMAL_LIMIT" 3 "WINDOW_CONTROL_UNAVAILABLE_REASON_PINCH" 2 "WINDOW_CONTROL_UNAVAILABLE_REASON_SWITCH_PRESSED" 1 "WINDOW_CONTROL_UNAVAILABLE_REASON_UNEXPECTED" 0 "WINDOW_CONTROL_UNAVAILABLE_REASON_NONE" ;
VAL_ 706 VCLEFT_windowPositionStateLF 7 "WINDOW_POSITION_CLOSED_TRIM_CLEAR" 6 "WINDOW_POSITION_FULL_OPEN" 5 "WINDOW_POSITION_PARTIAL_OPEN" 4 "WINDOW_POSITION_DAS_LIMITED" 3 "WINDOW_POSITION_VENT" 2 "WINDOW_POSITION_CRACKED" 1 "WINDOW_POSITION_CLOSED" 0 "WINDOW_POSITION_UNKNOWN" ;
VAL_ 706 VCLEFT_windowPositionStateLR 7 "WINDOW_POSITION_CLOSED_TRIM_CLEAR" 6 "WINDOW_POSITION_FULL_OPEN" 5 "WINDOW_POSITION_PARTIAL_OPEN" 4 "WINDOW_POSITION_DAS_LIMITED" 3 "WINDOW_POSITION_VENT" 2 "WINDOW_POSITION_CRACKED" 1 "WINDOW_POSITION_CLOSED" 0 "WINDOW_POSITION_UNKNOWN" ;
VAL_ 706 VCLEFT_windowVehGearStateLF 2 "WINDOW_VEHICLE_GEAR_STATE_IN_GEAR" 1 "WINDOW_VEHICLE_GEAR_STATE_PARK" 0 "WINDOW_VEHICLE_GEAR_STATE_UNKNOWN_SNA" ;
VAL_ 706 VCLEFT_windowVehGearStateLR 2 "WINDOW_VEHICLE_GEAR_STATE_IN_GEAR" 1 "WINDOW_VEHICLE_GEAR_STATE_PARK" 0 "WINDOW_VEHICLE_GEAR_STATE_UNKNOWN_SNA" ;
VAL_ 706 VCLEFT_windowSpeedTableStatusLF 2 "WINDOW_SPEED_TABLE_STATUS_FULLY_BUILT" 1 "WINDOW_SPEED_TABLE_STATUS_SENSITIVE_BUILT" 0 "WINDOW_SPEED_TABLE_STATUS_EMPTY_SNA" ;
VAL_ 706 VCLEFT_windowSpeedTableStatusLR 2 "WINDOW_SPEED_TABLE_STATUS_FULLY_BUILT" 1 "WINDOW_SPEED_TABLE_STATUS_SENSITIVE_BUILT" 0 "WINDOW_SPEED_TABLE_STATUS_EMPTY_SNA" ;
VAL_ 1114 VCRIGHT_AP_hvacState10HzIndex 2 "END" 1 "MUX_1" 0 "MUX_0" ;
VAL_ 1114 VCRIGHT_AP_hvacModelInitStatus 5 "INIT_WAITING_FOR_SENSORS" 4 "INIT_FORWARD_CALC" 3 "INIT_FROM_SENSORS_PREDICTION_ERROR" 2 "INIT_FROM_SENSORS" 1 "NOT_INIT_WAIT_FOR_GTW" 0 "NOT_INIT_WAIT_FOR_SENSORS" ;
VAL_ 1114 VCRIGHT_AP_cabinTempWindshield 255 "SNA" ;
VAL_ 1114 VCRIGHT_AP_cabinTempSideGlassRig 255 "SNA" ;
VAL_ 1114 VCRIGHT_AP_cabinTempSideGlassLef 255 "SNA" ;
VAL_ 1114 VCRIGHT_AP_hvacAirDistributionMo 7 "DEFROST_PANEL_FLOOR" 6 "DEFROST_PANEL" 5 "DEFROST_FLOOR" 4 "DEFROST" 3 "PANEL_FLOOR" 2 "PANEL" 1 "FLOOR" 0 "NONE" ;
VAL_ 1114 VCRIGHT_AP_tempDuctDefrost 255 "SNA" ;
VAL_ 1114 VCRIGHT_AP_cameraTurnOnTime 511 "SNA" ;
VAL_ 1114 VCRIGHT_AP_cameraDefogType 4 "TWO_CAMERA_PLUS_FAN" 3 "GLARESHIELD_HEATER_PLUS_FAN" 2 "CMD" 1 "CAMERA" 0 "NONE" ;
VAL_ 1114 VCRIGHT_ah_hvacFaultSurvivabilit 31 "SNA" ;
VAL_ 1114 VCRIGHT_ah_defoggingTimeNeeded 31 "SNA" ;
VAL_ 1114 VCRIGHT_AP_cameraFanDutyRequest 127 "SNA" ;
VAL_ 1114 VCRIGHT_ah_defogSystemState 7 "DEFOG_SYS_SNA" 6 "DEFOG_SYS_UNHEALTHY" 5 "DEFOG_SYS_HEALTHY_DEGRADED" 4 "DEFOG_SYS_HEALTHY" 3 "DEFOG_SYS_HEALTHY_REEVALUATING" 2 "DEFOG_SYS_EVALUATING_PRECONDITIONING" 1 "DEFOG_SYS_EVALUATING_HARDWARE" 0 "DEFOG_SYS_INIT" ;
VAL_ 1114 VCRIGHT_AP_turnForwardCameraHeat 15 "TURN_ON_REASON_MANUAL_FOGGING_HAMMER" 14 "TURN_ON_REASON_MANUAL_DEFOG_DEFROST" 13 "TURN_ON_REASON_MANUAL_HVAC_CONTROL" 12 "TURN_ON_REASON_HVAC_SYSTEM_NOT_NOMINAL" 11 "TURN_ON_REASON_WET_EVAP_STARTUP" 10 "TURN_ON_REASON_GLARESHIELD_PRECONDITIONING" 9 "TURN_ON_REASON_ROBOTAXI_PRECONDITIONING" 8 "TURN_ON_REASON_LOSS_OF_DEHUMIDIFICATION" 7 "TURN_ON_REASON_EXTERNAL_DEW_LIKELY" 6 "TURN_ON_REASON_FLASH_FOGGING" 5 "TURN_ON_REASON_COMPRESSOR_OFF" 4 "TURN_ON_REASON_START_OF_COLD_DRIVE" 3 "TURN_ON_REASON_RADIATOR_STEAMING" 2 "TURN_ON_REASON_EVAP_UNAVAILABLE" 1 "TURN_ON_REASON_EVAP_JUST_TURNED_OFF" 0 "TURN_ON_REASON_NONE" ;
VAL_ 1114 VCRIGHT_AP_turnCameraFanOffReaso 7 "TURN_OFF_REASON_CABIN_HUMIDITY" 6 "TURN_OFF_REASON_EVAP_CONTROLS_COMPROMISED" 5 "TURN_OFF_REASON_FLASH_FOGGING" 4 "TURN_OFF_REASON_VOC_CONCENTRATION_HIGH" 3 "TURN_OFF_REASON_START_OF_COLD_DRIVE" 2 "TURN_OFF_REASON_RADIATOR_STEAMING" 1 "TURN_OFF_REASON_EVAP_JUST_TURNED_OFF" 0 "TURN_OFF_REASON_NONE" ;
VAL_ 1114 VCRIGHT_AP_solarFluxOnRightWindo 255 "SNA" ;
VAL_ 1114 VCRIGHT_AP_solarFluxOnLeftWindow 255 "SNA" ;
VAL_ 1124 VCRIGHT_AP_hvacState1HzIndex 1 "END" 0 "0" ;
VAL_ 1124 VCRIGHT_AP_tempCameraModele_0001 255 "SNA" ;
VAL_ 1124 VCRIGHT_AP_tempCameraModeledWind 255 "SNA" ;
VAL_ 1124 VCRIGHT_AP_cameraModeledWin_0001 127 "SNA" ;
VAL_ 1124 VCRIGHT_AP_cameraModeledWindshie 127 "SNA" ;
VAL_ 1124 VCRIGHT_AP_cameraModeledPocketWa 1023 "SNA" ;
VAL_ 1124 VCRIGHT_AP_humidityModelInitStat 21 "INIT_STATUS_LIMP_FORWARD_CALC_AMBIENT_PROBE_AND_THS" 20 "INIT_STATUS_LIMP_FORWARD_CALC_WEATHER_PROBE_AND_THS" 19 "INIT_STATUS_LIMP_FORWARD_CALC_PROBE_AND_THS" 18 "INIT_STATUS_LIMP_FORWARD_CALC_AMBIENT_AND_THS" 17 "INIT_STATUS_LIMP_FORWARD_CALC_WEATHER_AND_THS" 16 "INIT_STATUS_LIMP_FORWARD_CALC_THS_ONLY" 15 "INIT_STATUS_LIMP_FORWARD_CALC_AMBIENT_AND_PROBE" 14 "INIT_STATUS_LIMP_FORWARD_CALC_WEATHER_AND_PROBE" 13 "INIT_STATUS_LIMP_FORWARD_CALC_PROBE_ONLY" 12 "INIT_STATUS_LIMP_FORWARD_CALC_AMBIENT_ONLY" 11 "INIT_STATUS_LIMP_FORWARD_CALC_WEATHER_ONLY" 10 "INIT_STATUS_LIMP_FROM_SENSORS_PROBE_ONLY" 9 "INIT_STATUS_FROM_FORWARD_CALC" 8 "INIT_STATUS_FROM_SENSORS" 7 "INIT_STATUS_FAULTED_MULTI_CYCLE_SENSOR_INVALID" 6 "INIT_STATUS_FAULTED_ALL_INVALID" 5 "INIT_STATUS_FAULTED_FORWARD_CALC_WEATHER_AND_AMBIENT_INVALID" 4 "INIT_STATUS_FAULTED_FROM_SENSORS_THS_INVALID" 3 "INIT_STATUS_WAITING_FOR_SENSORS_API" 2 "INIT_STATUS_WAITING_FOR_CABIN_MODEL_INIT" 1 "INIT_STATUS_WAITING_FOR_GTW" 0 "INIT_STATUS_UNKNOWN" ;
VAL_ 1124 VCRIGHT_AP_humidityModelStatus 19 "STATUS_RUNNING_FAULTED_WEATHER_AND_AMBIENT_INVALID" 18 "STATUS_RUNNING_LIMP_THS_DIRECTLY_NO_PROBE_LIMIT" 17 "STATUS_RUNNING_LIMP_THS_DIRECTLY_WITH_PROBE_LIMIT" 16 "STATUS_RUNNING_LIMP_THS_ONLY_SUBSTITUTED" 15 "STATUS_RUNNING_LIMP_AMBIENT_AND_PROBE_SUBSTITUTED_NO_THS_FEEDBACK" 14 "STATUS_RUNNING_LIMP_WEATHER_AND_PROBE_SUBSTITUTED_NO_THS_FEEDBACK" 13 "STATUS_RUNNING_LIMP_AMBIENT_AND_PROBE_SUBSTITUTED_WITH_THS_FEEDBACK" 12 "STATUS_RUNNING_LIMP_WEATHER_AND_PROBE_SUBSTITUTED_WITH_THS_FEEDBACK" 11 "STATUS_RUNNING_LIMP_EVAP_SUBSTITUTED_NO_THS_FEEDBACK" 10 "STATUS_RUNNING_LIMP_PROBE_SUBSTITUTED_NO_THS_FEEDBACK" 9 "STATUS_RUNNING_LIMP_AMBIENT_SUBSTITUTED_NO_THS_FEEDBACK" 8 "STATUS_RUNNING_LIMP_WEATHER_SUBSTITUTED_NO_THS_FEEDBACK" 7 "STATUS_RUNNING_LIMP_EVAP_SUBSTITUTED_WITH_THS_FEEDBACK" 6 "STATUS_RUNNING_LIMP_PROBE_SUBSTITUTED_WITH_THS_FEEDBACK" 5 "STATUS_RUNNING_LIMP_AMBIENT_SUBSTITUTED_WITH_THS_FEEDBACK" 4 "STATUS_RUNNING_LIMP_WEATHER_SUBSTITUTED_WITH_THS_FEEDBACK" 3 "STATUS_RUNNING_RECOVERED_CATCHUP" 2 "STATUS_RUNNING_PAUSED_AWAITING_RECOVERY" 1 "STATUS_RUNNING_NOMINAL" 0 "STATUS_UNKNOWN" ;
VAL_ 549 VCRIGHT_ptcLVState 3 "LV_FAULT" 2 "LV_GOING_DOWN" 1 "LV_ON" 0 "LV_OFF" ;
VAL_ 549 VCRIGHT_ocsLVState 3 "LV_FAULT" 2 "LV_GOING_DOWN" 1 "LV_ON" 0 "LV_OFF" ;
VAL_ 549 VCRIGHT_premAudioLVState 3 "LV_FAULT" 2 "LV_GOING_DOWN" 1 "LV_ON" 0 "LV_OFF" ;
VAL_ 549 VCRIGHT_rearOilPumpLVState 3 "LV_FAULT" 2 "LV_GOING_DOWN" 1 "LV_ON" 0 "LV_OFF" ;
VAL_ 549 VCRIGHT_tunerLVState 3 "LV_FAULT" 2 "LV_GOING_DOWN" 1 "LV_ON" 0 "LV_OFF" ;
VAL_ 549 VCRIGHT_hvcLVState 3 "LV_FAULT" 2 "LV_GOING_DOWN" 1 "LV_ON" 0 "LV_OFF" ;
VAL_ 549 VCRIGHT_rcmLVState 3 "LV_FAULT" 2 "LV_GOING_DOWN" 1 "LV_ON" 0 "LV_OFF" ;
VAL_ 549 VCRIGHT_lumbarLVState 3 "LV_FAULT" 2 "LV_GOING_DOWN" 1 "LV_ON" 0 "LV_OFF" ;
VAL_ 549 VCRIGHT_eFuseLockoutStatus 2 "EFUSE_LOCKOUT_STATUS_ACTIVE" 1 "EFUSE_LOCKOUT_STATUS_PENDING" 0 "EFUSE_LOCKOUT_STATUS_IDLE" ;
VAL_ 549 VCRIGHT_vehiclePowerStateDBG 3 "VEHICLE_POWER_STATE_DRIVE" 2 "VEHICLE_POWER_STATE_ACCESSORY" 1 "VEHICLE_POWER_STATE_CONDITIONING" 0 "VEHICLE_POWER_STATE_OFF" ;
VAL_ 549 VCRIGHT_parkLVState 3 "LV_FAULT" 2 "LV_GOING_DOWN" 1 "LV_ON" 0 "LV_OFF" ;
VAL_ 549 VCRIGHT_icrLVState 3 "LV_FAULT" 2 "LV_GOING_DOWN" 1 "LV_ON" 0 "LV_OFF" ;
VAL_ 549 VCRIGHT_interiorCameraLedLVState 3 "LV_FAULT" 2 "LV_GOING_DOWN" 1 "LV_ON" 0 "LV_OFF" ;
VAL_ 549 VCRIGHT_diLVState 3 "LV_FAULT" 2 "LV_GOING_DOWN" 1 "LV_ON" 0 "LV_OFF" ;
VAL_ 643 VCRIGHT_PTCRequestMode 4 "SEQ_ROD_CIO" 3 "SEQ_ROD_COI" 2 "DIRECT" 1 "DUTY" 0 "POWER" ;
VAL_ 2011 VCRIGHT_alertID 617 "a617_APP_MIA" 605 "a605_CANMsgMACVerificationKeyMismatch" 601 "a601_wakeToOpenDoorDbg" 599 "a599_LVBatteryTypeUnsupported" 598 "a598_childModeMonitorTrip" 597 "a597_rearDoorLatchUnexpectedVoltage" 596 "a596_frontDoorLatchUnexpectedVoltage" 595 "a595_seatThighSupportHCEncStlDbg" 594 "a594_seatThighSupportStallDebug" 593 "a593_seatEncOverThighSupport" 592 "a592_seatUncalThighSupport" 591 "a591_seatCurrUnderThighSupport" 590 "a590_seatEncStallThighSupport" 589 "a589_defogSysDriverlessSelfTest" 588 "a588_VCSEAT2R_MIA" 587 "a587_VCSEAT2L_MIA" 586 "a586_doorRemoteUnlatchFailedRear" 585 "a585_doorRemoteUnlatchFailedFront" 584 "a584_doorRemoteUnlatchedRear" 583 "a583_doorRemoteUnlatchedFront" 580 "a580_debugLiftgateFollowerCurrentSpike" 579 "a579_liftgateFollowerUnexpectedStop" 578 "a578_RGBLightFault" 577 "a577_bsiHardwareIssue" 575 "a575_3RowSeatStatsFromLastStateDbg2" 574 "a574_2RowSeatStatsFromLastStateDbg2" 573 "a573_seatHeatDisabledRearR" 572 "a572_seatHeatDisabledRearC" 571 "a571_seatHeatDisabledRearL" 570 "a570_seatHeatDisabledF" 569 "a569_2RowSeatOverfolded" 568 "a568_2RowSeatClashAvoidanceBlocked" 567 "a567_2RowSeatRequestWhileUncalibrated" 566 "a566_2RowSeatStatsFromLastStateDbg" 565 "a565_2RowSeatAbsPosSensorTransitionDbg" 564 "a564_2RowSeatTempHigh" 563 "a563_2RowSeatObstacleDetected" 562 "a562_2RowSeatAbsPosOffsetApplied" 561 "a561_2RowSeatPositionNonsensical" 560 "a560_2RowSeatUncalibrated" 556 "a556_rcmReportedOCSError" 555 "a555_RCM2_MIA" 551 "a551_interiorDoorRequestInhibited" 550 "a550_ambientTempDelta" 546 "a546_mirrorFoldTypeChanged" 545 "a545_LVBatteryTypeUnknown" 542 "a542_steeringWheelHeatingInhibited" 540 "a540_hvacActuatorDitherDebug" 539 "a539_dogModeMonitorTrip" 538 "a538_hvacSystemNotNominal" 537 "a537_solarCalcsNotNominal" 533 "a533_cabinModelDebug" 532 "a532_airflowModelFeedForwardError" 531 "a531_airflowModelTmpCompDisabled" 529 "a529_airflowFeedBackModelError" 528 "a528_unableToRunStuckOnTest" 527 "a527_continuousFeedUnexpectedVoltage" 526 "a526_pcbaOverTemperature" 525 "a525_LVBatterySWMisconfiguration" 520 "a520_configMismatch" 519 "a519_3RowSeatOverfolded" 518 "a518_3RowSeatClashAvoidanceBlocked" 517 "a517_3RowSeatRequestWhileUncalibrated" 516 "a516_3RowSeatStatsFromLastStateDbg" 515 "a515_3RowSeatAbsPosSensorTransitionDbg" 514 "a514_3RowSeatTempHigh" 513 "a513_3RowSeatObstacleDetected" 512 "a512_3RowSeatAbsPosOffsetApplied" 511 "a511_3RowSeatPositionNonsensical" 510 "a510_3RowSeatUncalibrated" 499 "a499_epbmInvalidateCdp" 498 "a498_CANMsgMACVerificationFailure" 497 "a497_CANMsgMACVerificationKeyNotProvisioned" 496 "a496_gloveboxOpenFailed" 492 "a492_uvSelfTestLoadUnattemptedOnDbg" 491 "a491_BPillarCameraHeaterFault" 490 "a490_vehicleOccupiedOnOTAStart" 489 "a489_undervoltageSelfTestStuckOn" 488 "a488_undervoltageSelfTestStuckOnDebug" 487 "a487_centerHighMountStopLightFaultUser" 486 "a486_rightTailLightFaultUser" 485 "a485_leftTailLightFaultUser" 484 "a484_rightBrakeLightFaultUser" 483 "a483_rightTurnLightFaultUser" 482 "a482_NCV77XXFault" 454 "a454_ptcHeaterBadRodDetected" 451 "a451_ptcSeqRodOutOfRetries" 450 "a450_ptcForcedOutOfSeqRod" 448 "a448_manualHVACAlert" 446 "a446_cabinHVACUnavailableContext" 445 "a445_drv8703SpiFaultDBG" 444 "a444_drv8703Fault" 429 "a429_seatAbuseBufferFull" 428 "a428_seatAbuseBufferWarn" 427 "a427_seatAbuseMotorStop" 426 "a426_seatAbuseMotorWarn" 422 "a422_undervoltageSelfTestStuckOff" 421 "a421_leftTailLightFault" 420 "a420_tailFasciaRightLightFault" 419 "a419_tailFasciaLeftLightFault" 418 "a418_rearFasciaRightTurnLightFault" 417 "a417_rearFasciaLeftTurnLightFault" 416 "a416_rearFasciaTailLightFault" 415 "a415_rearFasciaFogLightFault" 414 "a414_rearFasciaReverseLightFault" 413 "a413_centerHighMountStopLightFault" 412 "a412_rightBrakeTailLightFault" 411 "a411_undervoltageSelfTestFailure" 409 "a409_aptivOCSDeviceErrorDebug" 408 "a408_aptivOCSDeviceError" 407 "a407_aptivOCSInterfaceError" 406 "a406_aptivOCSMIA" 385 "a385_glareShieldHeaterUnavailable" 383 "a383_hvacRearWarning" 382 "a382_leftLiftgateTailLightFault" 381 "a381_rearFogLightFault" 380 "a380_reverseLightFault" 379 "a379_ductRightUpperTempSns" 378 "a378_ductLeftUpperTempSns" 377 "a377_ambientTempSns" 376 "a376_seat2RowBridgeCurrentExceeded" 375 "a375_windowPinchOverrideNudge" 373 "a373_windowSwOpenReqInDogMode" 372 "a372_seat2RowBackrestUnlatched" 371 "a371_seat2RowTrackUnlatched" 370 "a370_seat2RowPitchUnlatched" 369 "a369_ductRightLowerTempSns" 368 "a368_ductLeftLowerTempSns" 367 "a367_trunkLatchSwFault" 366 "a366_trunkLatchUnhomed" 365 "a365_pitchUnlatchDisabled" 364 "a364_hvacIntakeWarning" 363 "a363_hvacLowerModeWarning" 362 "a362_movingThresholdsIncorrect" 361 "a361_stationaryThresholdsIncorrect" 360 "a360_detectedStationaryWhileMoving" 359 "a359_hvacUpperModeWarning" 358 "a358_hvacRHVaneWarning" 357 "a357_hvacLHVaneWarning" 356 "a356_hvacRHBleedWarning" 355 "a355_hvacLHBleedWarning" 352 "a352_audioCurrentSpikeData" 347 "a347_nonContMonitorClearedDBG" 346 "a346_cabinRadarEFuseFault" 345 "a345_HVACPTCHeaterPwrEFuseFault" 344 "a344_rearDefrostOvercurrent" 343 "a343_rearDefrostUndercurrent" 342 "a342_rearDefrostDisabled" 337 "a337_windowDropRevThermalR" 336 "a336_windowDropRevThermalF" 331 "a331_shortDropFailedR" 330 "a330_shortDropFailedF" 329 "a329_airwaveRightLateralWarning" 328 "a328_airwaveLeftVerticalWarning" 327 "a327_airwaveLeftLateralWarning" 326 "a326_airwaveLeftLateralUnavailable" 325 "a325_airwaveLeftVerticalUnavailable" 324 "a324_mirrorHeatFault" 323 "a323_mirrorCalibrated" 322 "a322_windowRezeroedDebugR" 321 "a321_windowRezeroedDebugF" 320 "a320_windowReportCrackedAtTrimClear" 319 "a319_rightExteriorTrunkLightFault" 318 "a318_leftExteriorTrunkLightFault" 317 "a317_epbmLimpModeEnabled" 316 "a316_mirrorPrematureFoldStall" 315 "a315_rightInteriorTrunkLightFault" 314 "a314_rightMapPocketLightFault" 313 "a313_rightFootwellLightFault" 312 "a312_rightTailLightFault" 311 "a311_rightBrakeLightFault" 310 "a310_mirrorFoldStall" 308 "a308_airwaveRightLateralUnavailable" 307 "a307_handleDisconnectedR" 306 "a306_handleDisconnectedF" 305 "a305_rearIntHandleUnexpectedVoltage" 304 "a304_frontIntHandleUnexpectedVoltage" 303 "a303_eFuseMgmtWindowLift" 302 "a302_airwaveRightVerticalUnavailable" 301 "a301_airwaveRightVerticalWarning" 300 "a300_VCFRONT1_MIA" 299 "a299_buckleFaulted3RowR" 298 "a298_buckleFaulted3RowL" 297 "a297_seatBelowMinPumpTmp" 296 "a296_occupancyFaulted3RowR" 295 "a295_occupancyFaulted3RowL" 294 "a294_occupancyFaultedRearR" 293 "a293_buckleFaultedRearR" 292 "a292_buckleFaultedRearC" 291 "a291_buckleFaultedFront" 290 "a290_occupancyFaultedFront" 289 "a289_handlePWMPeriodR" 288 "a288_handlePWMPeriodF" 287 "a287_windowSpeedInvalidR" 286 "a286_windowSpeedInvalidF" 285 "a285_gloveboxOverCurrentDetected" 284 "a284_gloveboxUnderCurrentDetected" 283 "a283_latchUnexpectedArmR" 282 "a282_latchUnexpectedArmF" 281 "a281_latchDidNotDisarmR" 280 "a280_latchDidNotDisarmF" 279 "a279_trunkFailedToClose" 278 "a278_hvacPtcHeatingUnavailable" 277 "a277_BLERightUnderVoltage" 276 "a276_mirrorDebug" 275 "a275_rightTurnLightFault" 274 "a274_handleStuckActiveR" 273 "a273_handleStuckActiveF" 272 "a272_vhclPwrStateMsmtch" 271 "a271_THSSensorFault" 270 "a270_seatLiftHCEncStlDbg" 269 "a269_seatTiltHCEncStlDbg" 268 "a268_seatBackHCEncStlDbg" 267 "a267_seatTrackHCEncStlDbg" 266 "a266_seatLiftStallDebug" 265 "a265_seatTiltStallDebug" 264 "a264_seatBackStallDebug" 263 "a263_seatTrackStallDebug" 262 "a262_PTCFaulted" 261 "a261_emergencyLatchRelRear" 260 "a260_latchDisarmDelayR" 259 "a259_latchDisarmDelayF" 258 "a258_PTCStuckInBoot" 257 "a257_THSMIA" 256 "a256_PTCCurrentDrawNoReq" 255 "a255_PTCOverTemp" 254 "a254_seatUncalLift" 253 "a253_seatUncalTilt" 252 "a252_seatUncalBack" 251 "a251_seatUncalTrack" 250 "a250_seatHeatMIARearR" 249 "a249_seatHeatShortRearR" 248 "a248_seatHeatIRearR" 247 "a247_seatHeatMIARearC" 246 "a246_seatHeatShortRearC" 245 "a245_seatHeatIRearC" 244 "a244_seatHeatMIARearL" 243 "a243_seatHeatShortRearL" 242 "a242_seatHeatIRearL" 241 "a241_seatHeatMIAFront" 240 "a240_seatHeatShortFront" 239 "a239_seatHeatIFront" 238 "a238_lumbarValveMIA" 237 "a237_lumbarOverPresB" 236 "a236_lumbarOverPresA" 235 "a235_seatCurrUnderLift" 234 "a234_seatCurrUnderTilt" 233 "a233_seatCurrUnderBack" 232 "a232_seatCurrUnderTrack" 231 "a231_seatEncOverLift" 230 "a230_seatEncOverTilt" 229 "a229_seatEncOverBack" 228 "a228_seatEncOverTrack" 227 "a227_seatEncStallLift" 226 "a226_seatEncStallTilt" 225 "a225_seatEncStallBack" 224 "a224_seatEncStallTrack" 223 "a223_VCBATT1_MIA" 222 "a222_rearFasciaFogLightFaultUser" 221 "a221_undervoltageLoadshedTriggered" 220 "a220_reverseLightFaultUser" 219 "a219_motorCurrentDropout" 218 "a218_motorDriverFault" 217 "a217_SPI_MIA_debugData2" 216 "a216_SPI_MIA_debugData1" 215 "a215_currentDesyncWarning" 214 "a214_epbmOverIDynNew" 213 "a213_epbmUnderIDynNew" 212 "a212_epbmOverIStaticNew" 211 "a211_epbmUnderIStaticNew" 210 "a210_epbStateTime" 209 "a209_epbStateMisTime" 208 "a208_epbFaulted" 207 "a207_epbmEnableWrong" 206 "a206_epbWrongDirection" 205 "a205_epbmOverIDyn" 204 "a204_epbmUnderIDyn" 203 "a203_epbmOverIStatic" 202 "a202_epbmUnderIStatic" 201 "a201_motorDutyEncDisabl" 200 "a200_motorPhantomEncoder" 199 "a199_PRVCANUndertrminate" 198 "a198_PRVCANOverterminate" 197 "a197_VEHCANUndertrminate" 196 "a196_VEHCANOverterminate" 195 "a195_hvcEFuseFault" 194 "a194_cntctrPwrEFuseFault" 193 "a193_amplifierEFuseFault" 192 "a192_gloveboxLatchRel" 191 "a191_gloveboxPower" 190 "a190_eFuseMgmtVbatFused" 189 "a189_latchUnableToRearmR" 188 "a188_latchUnableToRearmF" 187 "a187_latchReleaseFailedR" 186 "a186_latchReleaseFailedF" 185 "a185_summonAborted" 184 "a184_trunkFailedOpening" 183 "a183_doorStateFactoryTest" 182 "a182_emergencyLatchRel" 181 "a181_rearDoorLatchRehome" 180 "a180_frontDoorLatchRehome" 179 "a179_trunkSwitchVCFRONTMIA" 178 "a178_trunkSwitchVCBATTMIA" 177 "a177_hvacRearFault" 176 "a176_windowSealDefectRear" 175 "a175_windowSealDefectFront" 174 "a174_BLERightPowerCycled" 173 "a173_windowBtnDoorOpen" 172 "a172_SPI_MIA" 171 "a171_hvacRearUncalib" 170 "a170_windowCurrentPeakR" 169 "a169_windowCurrentPeakF" 168 "a168_windowDebugPinchR" 167 "a167_windowDebugPinchF" 166 "a166_windowDebug" 165 "a165_windowFactoryTest2" 164 "a164_windowFactoryTest" 163 "a163_windowEncoderStallR" 162 "a162_windowEncoderStallF" 161 "a161_windowUndercurrentR" 160 "a160_windowUndercurrentF" 159 "a159_windowPinchOverideR" 158 "a158_windowPinchOverideF" 157 "a157_windowNoInputRear" 156 "a156_windowNoInputFront" 155 "a155_windowThermalRear" 154 "a154_windowThermalFront" 153 "a153_windowUncalRear" 152 "a152_windowUncalFront" 151 "a151_windowPinchRear" 150 "a150_windowPinchFront" 149 "a149_incarDeepTempSns" 148 "a148_incarMidTempSns" 147 "a147_incarProbeTempSns" 146 "a146_ductRightTempSns" 145 "a145_ductLeftTempSns" 144 "a144_evaporatorTempSns" 143 "a143_mirrorManuallyFolded" 142 "a142_hvacLowerModeFault" 141 "a141_hvacUpperModeFault" 140 "a140_hvacRHVaneFault" 139 "a139_hvacLHVaneFault" 138 "a138_hvacRHBleedFault" 137 "a137_hvacLHBleedFault" 136 "a136_hvacIntakeFault" 135 "a135_hvacLowrModeUncalib" 134 "a134_hvacUpprModeUncalib" 133 "a133_hvacRHVaneUncalib" 132 "a132_hvacLHVaneUncalib" 131 "a131_hvacRHBleedUncalib" 130 "a130_hvacLHBleedUncalib" 129 "a129_hvacIntakeUncalib" 128 "a128_hvacActDrvFaultDBG" 127 "a127_hvacActOvercurrentDBG" 126 "a126_hvacActOpenLoadDBG" 125 "a125_RCU_MIA" 124 "a124_BB_MIA" 123 "a123_VC_SECONDARY_LIGHTING_LEADER_MIA" 122 "a122_ICR_MIA" 121 "a121_ETC_MIA" 120 "a120_DI_DRIVE_MIA" 119 "a119_SCCM_MIA" 118 "a118_VCFRONT_MIA" 117 "a117_VCLEFT_MIA" 116 "a116_VCRIGHT_MIA" 115 "a115_VCSEC_MIA" 114 "a114_ESP_MIA" 113 "a113_UI_MIA" 112 "a112_EPBL_MIA" 111 "a111_EPBR_MIA" 110 "a110_GTW_MIA" 109 "a109_RCM_MIA" 108 "a108_DIF_MIA" 107 "a107_BMS_MIA" 106 "a106_PCS_MIA" 105 "a105_TAS_MIA" 104 "a104_DAS_MIA" 103 "a103_CP_MIA" 102 "a102_PTC_MIA" 101 "a101_PM_MIA" 100 "a100_CANbus_MIA" 99 "a099_PARK_MIA" 98 "a098_DIR_MIA" 97 "a097_CMP_MIA" 96 "a096_OCS1P_MIA" 95 "a095_CHG_MIA" 94 "a094_EPAS3P_MIA" 93 "a093_VCSEATP_MIA" 92 "a092_VCSEATD_MIA" 91 "a091_CMPD_MIA" 90 "a090_APS_MIA" 89 "a089_IBST_MIA" 88 "a088_DIRER_MIA" 87 "a087_DIREL_MIA" 86 "a086_VCBATT_MIA" 85 "a085_CCCM_MIA" 84 "a084_TPMS_MIA" 83 "a083_VCLEFT_IPC_MIA" 82 "a082_VCRIGHT_IPC_MIA" 66 "a066_emiosIsrShortPeriodDetectedDbg" 65 "a065_emiosIsrRateLimitedDbg" 64 "a064_busSleepReqTimeout" 63 "a063_SwitchFault" 62 "a062_XCPWasConnected" 61 "a061_XCPConnected" 60 "a060_engineeringBuild" 59 "a059_inputResistanceHigh" 58 "a058_inputRHighSyncDebug" 57 "a057_HVP_MIA" 46 "a046_Task1000msError" 45 "a045_Task100msError" 44 "a044_Task10msError" 43 "a043_Task1msError" 42 "a042_HighStackUsage" 41 "a041_HighCPULoad" 31 "a031_UDSActive" 30 "a030_ECULogUploadRequest" 29 "a029_CoreDump" 22 "a022_TaskInitError" 21 "a021_TaskSchedulerError" 17 "a017_NVMMStatusDbg" 16 "a016_NVMMRecordError" 15 "a015_NVMMError" 13 "a013_AlertManagerFault" 12 "a012_CPUReset" 10 "a010_ExtSupplyVoltError" 6 "a006_CANTX_cyclicError" 5 "a005_CANTXError" 3 "a003_SWAssertion" 2 "a002_PowerLossReset" 1 "a001_WatchdogReset" 0 "ALERT_DO_NOT_USE_ZERO" ;
VAL_ 2011 VCRIGHT_alertState 1 "SET" 0 "CLEARED" ;
